VERSION ""

NS_ :

BS_:

BU_: FLC_FD3

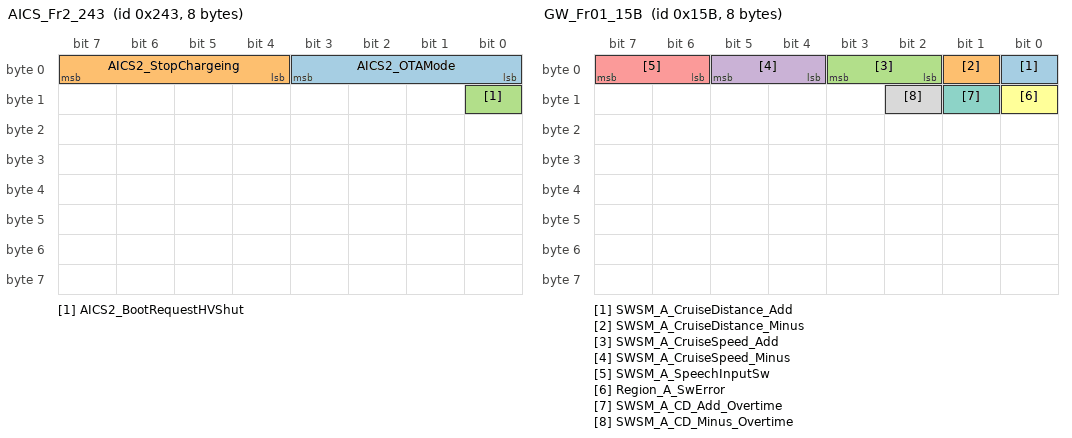
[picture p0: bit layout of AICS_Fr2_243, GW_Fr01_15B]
BO_ 579 AICS_Fr2_243: 8 Vector__XXX
 SG_ AICS2_OTAMode : 3|4@0+ (1,0) [0|15] "NoUnit" FLC_FD3
 SG_ AICS2_StopChargeing : 7|4@0+ (1,0) [0|15] "NoUnit" FLC_FD3
 SG_ AICS2_BootRequestHVShut : 8|1@0+ (1,0) [0|1] "NoUnit" FLC_FD3

BO_ 347 GW_Fr01_15B: 8 Vector__XXX
 SG_ SWSM_A_CruiseDistance_Add : 0|1@0+ (1,0) [0|1] "NoUnit" FLC_FD3
 SG_ SWSM_A_CruiseDistance_Minus : 1|1@0+ (1,0) [0|1] "NoUnit" FLC_FD3
 SG_ SWSM_A_CruiseSpeed_Add : 3|2@0+ (1,0) [0|3] "NoUnit" FLC_FD3
 SG_ SWSM_A_CruiseSpeed_Minus : 5|2@0+ (1,0) [0|3] "NoUnit" FLC_FD3
 SG_ SWSM_A_SpeechInputSw : 7|2@0+ (1,0) [0|3] "NoUnit" FLC_FD3
 SG_ Region_A_SwError : 8|1@0+ (1,0) [0|1] "NoUnit" FLC_FD3
 SG_ SWSM_A_CD_Add_Overtime : 9|1@0+ (1,0) [0|1] "NoUnit" FLC_FD3
 SG_ SWSM_A_CD_Minus_Overtime : 10|1@0+ (1,0) [0|1] "NoUnit" FLC_FD3

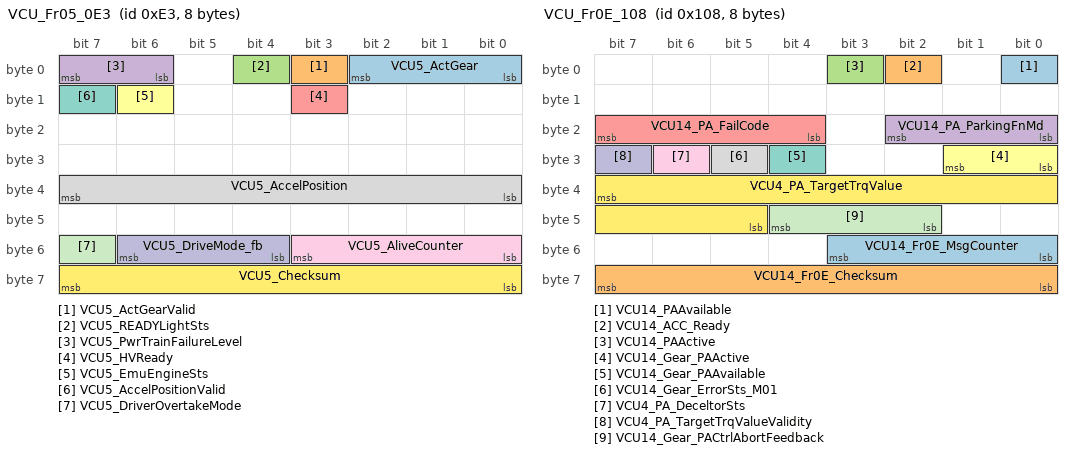
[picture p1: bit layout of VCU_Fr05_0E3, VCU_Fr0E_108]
BO_ 227 VCU_Fr05_0E3: 8 Vector__XXX
 SG_ VCU5_ActGear : 2|3@0+ (1,0) [0|7] "NoUnit" FLC_FD3
 SG_ VCU5_ActGearValid : 3|1@0+ (1,0) [0|1] "NoUnit" FLC_FD3
 SG_ VCU5_READYLightSts : 4|1@0+ (1,0) [0|1] "NoUnit" FLC_FD3
 SG_ VCU5_PwrTrainFailureLevel : 7|2@0+ (1,0) [0|3] "NoUnit" FLC_FD3
 SG_ VCU5_HVReady : 11|1@0+ (1,0) [0|1] "NoUnit" FLC_FD3
 SG_ VCU5_EmuEngineSts : 14|1@0+ (1,0) [0|1] "NoUnit" FLC_FD3
 SG_ VCU5_AccelPositionValid : 15|1@0+ (1,0) [0|1] "NoUnit" FLC_FD3
 SG_ VCU5_AccelPosition : 39|8@0+ (1,0) [0|100] "%" FLC_FD3
 SG_ VCU5_AliveCounter : 51|4@0+ (1,0) [0|15] "NoUnit" FLC_FD3
 SG_ VCU5_DriveMode_fb : 54|3@0+ (1,0) [0|7] "NoUnit" FLC_FD3
 SG_ VCU5_DriverOvertakeMode : 55|1@0+ (1,0) [0|1] "NoUnit" FLC_FD3
 SG_ VCU5_Checksum : 63|8@0+ (1,0) [0|255] "NoUnit" FLC_FD3

BO_ 264 VCU_Fr0E_108: 8 Vector__XXX
 SG_ VCU14_PAAvailable : 0|1@0+ (1,0) [0|1] "NoUnit" FLC_FD3
 SG_ VCU14_ACC_Ready : 2|1@0+ (1,0) [0|1] "NoUnit" FLC_FD3
 SG_ VCU14_PAActive : 3|1@0+ (1,0) [0|1] "NoUnit" FLC_FD3
 SG_ VCU14_PA_ParkingFnMd : 18|3@0+ (1,0) [0|7] "NoUnit" FLC_FD3
 SG_ VCU14_PA_FailCode : 23|4@0+ (1,0) [0|15] "NoUnit" FLC_FD3
 SG_ VCU14_Gear_PAActive : 25|2@0+ (1,0) [0|3] "NoUnit" FLC_FD3
 SG_ VCU14_Gear_PAAvailable : 28|1@0+ (1,0) [0|1] "NoUnit" FLC_FD3
 SG_ VCU14_Gear_ErrorSts_M01 : 29|1@0+ (1,0) [0|1] "NoUnit" FLC_FD3
 SG_ VCU4_PA_DeceltorSts : 30|1@0+ (1,0) [0|1] "NoUnit" FLC_FD3
 SG_ VCU4_PA_TargetTrqValueValidity : 31|1@0+ (1,0) [0|1] "NoUnit" FLC_FD3
 SG_ VCU14_Gear_PACtrlAbortFeedback : 44|3@0+ (1,0) [0|7] "NoUnit" FLC_FD3
 SG_ VCU4_PA_TargetTrqValue : 39|11@0+ (0.5,-400) [400|400] "Nm" FLC_FD3
 SG_ VCU14_Fr0E_MsgCounter : 51|4@0+ (1,0) [0|15] "NoUnit" FLC_FD3
 SG_ VCU14_Fr0E_Checksum : 63|8@0+ (1,0) [0|255] "NoUnit" FLC_FD3

BO_ 600 BMS_Fr03_258: 8 Vector__XXX
 SG_ BMS3_StateOfCharge : 7|16@0+ (0.1,0) [0|100] "NoUnit" FLC_FD3
 SG_ BMS3_Charge_State : 59|4@0+ (1,0) [0|15] "NoUnit" FLC_FD3

BO_ 170 MCU_Fr01_0AA: 16 Vector__XXX
 SG_ MCU1_MotorSpeed : 23|16@0+ (1,-20000) [-20000|45531] "Rpm" FLC_FD3
 SG_ MCU1_ControllerTorque : 39|16@0+ (0.05,-1024) [-1024|1024] "Nm" FLC_FD3
 SG_ MCU1_AliveCounter : 51|4@0+ (1,0) [0|15] "NoUnit" FLC_FD3
 SG_ MCU1_presentActivityFault : 71|8@0+ (1,0) [0|128] "NoUnit" FLC_FD3
 SG_ MCU1_CurrentTorque : 78|15@0+ (0.05,-400) [-400|400] "Nm" FLC_FD3
 SG_ MCU1_CurrentTorqueValid : 95|1@0+ (1,0) [0|1] "NoUnit" FLC_FD3

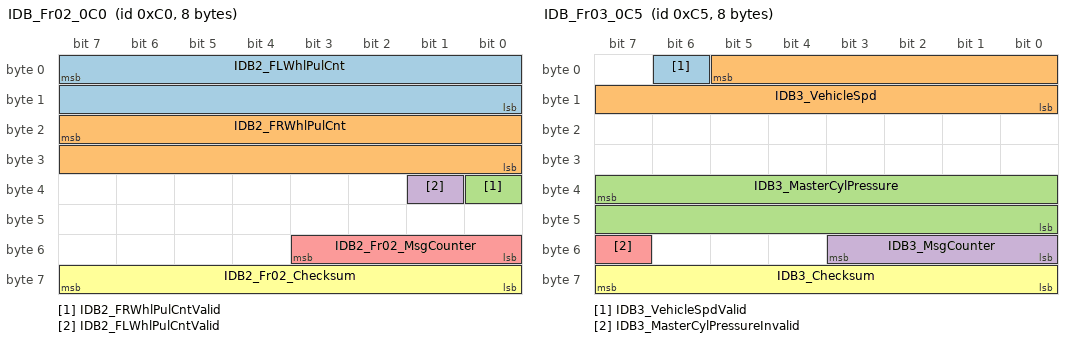
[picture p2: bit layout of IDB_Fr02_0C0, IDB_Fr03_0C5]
BO_ 192 IDB_Fr02_0C0: 8 Vector__XXX
 SG_ IDB2_FLWhlPulCnt : 7|16@0+ (0.5,0) [0|32767] "NoUnit" FLC_FD3
 SG_ IDB2_FRWhlPulCnt : 23|16@0+ (0.5,0) [0|32767] "NoUnit" FLC_FD3
 SG_ IDB2_FRWhlPulCntValid : 32|1@0+ (1,0) [0|1] "NoUnit" FLC_FD3
 SG_ IDB2_FLWhlPulCntValid : 33|1@0+ (1,0) [0|1] "NoUnit" FLC_FD3
 SG_ IDB2_Fr02_MsgCounter : 51|4@0+ (1,0) [0|15] "NoUnit" FLC_FD3
 SG_ IDB2_Fr02_Checksum : 63|8@0+ (1,0) [0|255] "NoUnit" FLC_FD3

BO_ 197 IDB_Fr03_0C5: 8 Vector__XXX
 SG_ IDB3_VehicleSpdValid : 6|1@0+ (1,0) [0|1] "NoUnit" FLC_FD3
 SG_ IDB3_VehicleSpd : 5|14@0+ (0.03125,0) [0|511.9375] "km/h" FLC_FD3
 SG_ IDB3_MasterCylPressure : 39|16@0+ (0.01,-30) [0|280] "bar" FLC_FD3
 SG_ IDB3_MsgCounter : 51|4@0+ (1,0) [0|15] "NoUnit" FLC_FD3
 SG_ IDB3_MasterCylPressureInvalid : 55|1@0+ (1,0) [0|1] "NoUnit" FLC_FD3
 SG_ IDB3_Checksum : 63|8@0+ (1,0) [0|255] "NoUnit" FLC_FD3

BO_ 199 IDB_Fr04_0C7: 32 Vector__XXX
 SG_ IDB4_FLWhlVelocityValid : 9|1@0+ (1,0) [0|1] "NoUnit" FLC_FD3
 SG_ IDB4_FLWhlVelocity : 7|14@0+ (0.03125,0) [0|511.9375] "km/h" FLC_FD3
 SG_ IDB4_FRWhlVelocityValid : 25|1@0+ (1,0) [0|1] "NoUnit" FLC_FD3
 SG_ IDB4_FRWhlVelocity : 23|14@0+ (0.03125,0) [0|511.9375] "km/h" FLC_FD3
 SG_ IDB4_RRWhlDir : 33|2@0+ (1,0) [0|3] "NoUnit" FLC_FD3
 SG_ IDB4_RLWhlDir : 35|2@0+ (1,0) [0|3] "NoUnit" FLC_FD3
 SG_ IDB4_FRWhlDir : 37|2@0+ (1,0) [0|3] "NoUnit" FLC_FD3
 SG_ IDB4_FLWhlDir : 39|2@0+ (1,0) [0|3] "NoUnit" FLC_FD3
 SG_ IDB4_MsgCounter : 51|4@0+ (1,0) [0|15] "NoUnit" FLC_FD3
 SG_ IDB4_Checksum : 63|8@0+ (1,0) [0|255] "NoUnit" FLC_FD3
 SG_ IDB4_RRWhlVelocityValid : 72|1@0+ (1,0) [0|1] "NoUnit" FLC_FD3
 SG_ IDB4_RLWhlVelocityValid : 73|1@0+ (1,0) [0|1] "NoUnit" FLC_FD3
 SG_ IDB4_RLWhlVelocity : 71|14@0+ (0.03125,0) [0|511.9375] "km/h" FLC_FD3
 SG_ IDB4_RLWhlPulCntValid : 88|1@0+ (1,0) [0|1] "NoUnit" FLC_FD3
 SG_ IDB4_RRWhlPulCntValid : 89|1@0+ (1,0) [0|1] "NoUnit" FLC_FD3
 SG_ IDB4_RRWhlVelocity : 87|14@0+ (0.03125,0) [0|511.9375] "km/h" FLC_FD3
 SG_ IDB4_RLWhlPulCnt : 103|16@0+ (0.5,0) [0|32767] "NoUnit" FLC_FD3
 SG_ IDB4_RRWhlPulCnt : 119|16@0+ (0.5,0) [0|32767] "NoUnit" FLC_FD3

BO_ 201 IDB_Fr10_0C9: 16 Vector__XXX
 SG_ IDB10_ADAS_DrvTorqueReq : 40|1@0+ (1,0) [0|1] "NoUnit" FLC_FD3
 SG_ IDB10_ADAS_RegenTorqueReq : 41|1@0+ (1,0) [0|1] "NoUnit" FLC_FD3
 SG_ IDB10_ADAS_DrvTorque : 103|16@0+ (0.5,-16000) [-16000|16000] "Nm" FLC_FD3
 SG_ IDB10_ADAS_RegenTorque : 119|16@0+ (0.5,-16000) [-16000|16000] "Nm" FLC_FD3

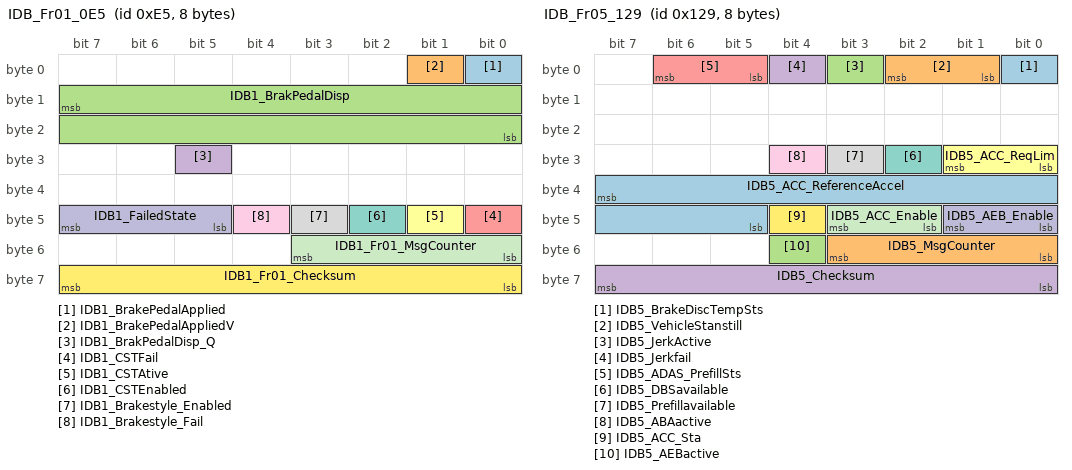
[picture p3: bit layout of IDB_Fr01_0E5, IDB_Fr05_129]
BO_ 229 IDB_Fr01_0E5: 8 Vector__XXX
 SG_ IDB1_BrakePedalApplied : 0|1@0+ (1,0) [0|1] "NoUnit" FLC_FD3
 SG_ IDB1_BrakePedalAppliedV : 1|1@0+ (1,0) [0|1] "NoUnit" FLC_FD3
 SG_ IDB1_BrakPedalDisp : 15|16@0+ (0.1,-40) [-40|160] "mm" FLC_FD3
 SG_ IDB1_BrakPedalDisp_Q : 29|1@0+ (1,0) [0|1] "NoUnit" FLC_FD3
 SG_ IDB1_CSTFail : 40|1@0+ (1,0) [0|1] "NoUnit" FLC_FD3
 SG_ IDB1_CSTAtive : 41|1@0+ (1,0) [0|1] "NoUnit" FLC_FD3
 SG_ IDB1_CSTEnabled : 42|1@0+ (1,0) [0|1] "NoUnit" FLC_FD3
 SG_ IDB1_Brakestyle_Enabled : 43|1@0+ (1,0) [0|1] "NoUnit" FLC_FD3
 SG_ IDB1_Brakestyle_Fail : 44|1@0+ (1,0) [0|1] "NoUnit" FLC_FD3
 SG_ IDB1_FailedState : 47|3@0+ (1,0) [0|7] "NoUnit" FLC_FD3
 SG_ IDB1_Fr01_MsgCounter : 51|4@0+ (1,0) [0|15] "NoUnit" FLC_FD3
 SG_ IDB1_Fr01_Checksum : 63|8@0+ (1,0) [0|255] "NoUnit" FLC_FD3

BO_ 289 IDB_Fr09_121: 8 Vector__XXX
 SG_ IDB9_BrakePedalPosition : 43|8@0+ (1,0) [0|100] "%" FLC_FD3

BO_ 297 IDB_Fr05_129: 8 Vector__XXX
 SG_ IDB5_BrakeDiscTempSts : 0|1@0+ (1,0) [0|1] "NoUnit" FLC_FD3
 SG_ IDB5_VehicleStanstill : 2|2@0+ (1,0) [0|3] "NoUnit" FLC_FD3
 SG_ IDB5_JerkActive : 3|1@0+ (1,0) [0|1] "NoUnit" FLC_FD3
 SG_ IDB5_Jerkfail : 4|1@0+ (1,0) [0|1] "NoUnit" FLC_FD3
 SG_ IDB5_ADAS_PrefillSts : 6|2@0+ (1,0) [0|3] "" FLC_FD3
 SG_ IDB5_ACC_ReqLim : 25|2@0+ (1,0) [0|3] "NoUnit" FLC_FD3
 SG_ IDB5_DBSavailable : 26|1@0+ (1,0) [0|1] "NoUnit" FLC_FD3
 SG_ IDB5_Prefillavailable : 27|1@0+ (1,0) [0|1] "NoUnit" FLC_FD3
 SG_ IDB5_ABAactive : 28|1@0+ (1,0) [0|1] "NoUnit" FLC_FD3
 SG_ IDB5_AEB_Enable : 41|2@0+ (1,0) [0|3] "NoUnit" FLC_FD3
 SG_ IDB5_ACC_Enable : 43|2@0+ (1,0) [0|3] "NoUnit" FLC_FD3
 SG_ IDB5_ACC_Sta : 44|1@0+ (1,0) [0|1] "NoUnit" FLC_FD3
 SG_ IDB5_ACC_ReferenceAccel : 39|11@0+ (0.01,-10.23) [-10.23|10.24] "m/s?" FLC_FD3
 SG_ IDB5_MsgCounter : 51|4@0+ (1,0) [0|15] "NoUnit" FLC_FD3
 SG_ IDB5_AEBactive : 52|1@0+ (1,0) [0|1] "NoUnit" FLC_FD3
 SG_ IDB5_Checksum : 63|8@0+ (1,0) [0|255] "NoUnit" FLC_FD3

BO_ 299 IDB_Fr06_12B: 8 Vector__XXX
 SG_ IDB6_EPBStatus : 34|3@0+ (1,0) [0|7] "NoUnit" FLC_FD3
 SG_ IDB6_EPBAvailable : 37|3@0+ (1,0) [0|7] "NoUnit" FLC_FD3

BO_ 301 IDB_Fr07_12D: 16 Vector__XXX
 SG_ IDB7_ESCFail : 0|1@0+ (1,0) [0|1] "NoUnit" FLC_FD3
 SG_ IDB7_ESCActive : 1|1@0+ (1,0) [0|1] "NoUnit" FLC_FD3
 SG_ IDB7_ESCDisable : 2|1@0+ (1,0) [0|1] "NoUnit" FLC_FD3
 SG_ IDB7_ABSActive : 3|1@0+ (1,0) [0|1] "NoUnit" FLC_FD3
 SG_ IDB7_EBD_Fail : 4|1@0+ (1,0) [0|1] "NoUnit" FLC_FD3
 SG_ IDB7_EBD_Active : 5|1@0+ (1,0) [0|1] "NoUnit" FLC_FD3
 SG_ IDB7_HBAActive : 6|1@0+ (1,0) [0|1] "NoUnit" FLC_FD3
 SG_ IDB7_HBAFail : 7|1@0+ (1,0) [0|1] "NoUnit" FLC_FD3
 SG_ IDB7_DiagMode : 8|1@0+ (1,0) [0|1] "NoUnit" FLC_FD3
 SG_ IDB7_TCSActive : 9|1@0+ (1,0) [0|1] "NoUnit" FLC_FD3
 SG_ IDB7_TCSDisable : 10|1@0+ (1,0) [0|1] "NoUnit" FLC_FD3
 SG_ IDB7_TCSFail : 11|1@0+ (1,0) [0|1] "NoUnit" FLC_FD3
 SG_ IDB7_ROPACTIVE : 12|1@0+ (1,0) [0|1] "NoUnit" FLC_FD3
 SG_ IDB7_ROPFailure : 13|1@0+ (1,0) [0|1] "NoUnit" FLC_FD3
 SG_ IDB7_DynParkBrkByIDBActive : 21|1@0+ (1,0) [0|1] "NoUnit" FLC_FD3
 SG_ IDB7_DynParkBrkByIDBAvailable : 22|1@0+ (1,0) [0|1] "NoUnit" FLC_FD3
 SG_ IDB7_HSAActive : 23|1@0+ (1,0) [0|1] "NoUnit" FLC_FD3
 SG_ IDB7_HSAFail : 24|1@0+ (1,0) [0|1] "NoUnit" FLC_FD3
 SG_ IDB7_HDCEnabled : 25|1@0+ (1,0) [0|1] "NoUnit" FLC_FD3
 SG_ IDB7_HDCFail : 26|1@0+ (1,0) [0|1] "NoUnit" FLC_FD3
 SG_ IDB7_HDCAtive : 27|1@0+ (1,0) [0|1] "NoUnit" FLC_FD3
 SG_ IDB7_ABSFail : 29|1@0+ (1,0) [0|1] "NoUnit" FLC_FD3
 SG_ IDB7_MsgCounter : 51|4@0+ (1,0) [0|15] "NoUnit" FLC_FD3
 SG_ IDB7_Checksum : 63|8@0+ (1,0) [0|255] "NoUnit" FLC_FD3

BO_ 302 IDB_Fr12_12E: 16 Vector__XXX
 SG_ IDB12_AVHDispMSG : 15|2@0+ (1,0) [0|3] "NoUnit" FLC_FD3
 SG_ IDB12_AVHLampReq : 17|2@0+ (1,0) [0|3] "NoUnit" FLC_FD3
 SG_ IDB12_AVHStatus : 19|2@0+ (1,0) [0|3] "NoUnit" FLC_FD3
 SG_ IDB12_AVHEnabled : 20|1@0+ (1,0) [0|1] "NoUnit" FLC_FD3

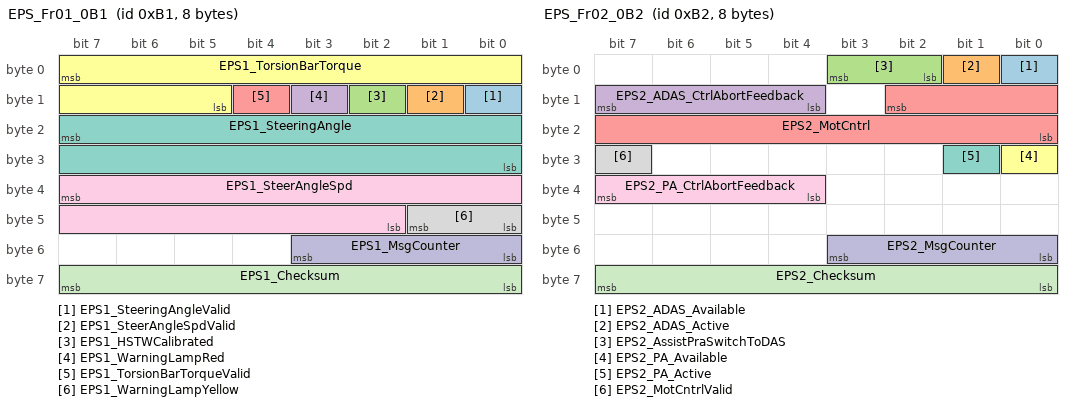
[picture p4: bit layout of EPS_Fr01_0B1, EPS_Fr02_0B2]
BO_ 177 EPS_Fr01_0B1: 8 Vector__XXX
 SG_ EPS1_SteeringAngleValid : 8|1@0+ (1,0) [0|1] "NoUnit" FLC_FD3
 SG_ EPS1_SteerAngleSpdValid : 9|1@0+ (1,0) [0|1] "NoUnit" FLC_FD3
 SG_ EPS1_HSTWCalibrated : 10|1@0+ (1,0) [0|1] "NoUnit" FLC_FD3
 SG_ EPS1_WarningLampRed : 11|1@0+ (1,0) [0|1] "NoUnit" FLC_FD3
 SG_ EPS1_TorsionBarTorqueValid : 12|1@0+ (1,0) [0|1] "NoUnit" FLC_FD3
 SG_ EPS1_TorsionBarTorque : 7|11@0+ (0.01,-10.24) [-10.24|10.23] "Nm" FLC_FD3
 SG_ EPS1_SteeringAngle : 23|16@0+ (0.0345,-780) [-780|780.021] "degree" FLC_FD3
 SG_ EPS1_WarningLampYellow : 41|2@0+ (1,0) [0|3] "NoUnit" FLC_FD3
 SG_ EPS1_SteerAngleSpd : 39|14@0+ (0.125,-1024) [-1024|1023.75] "deg/s" FLC_FD3
 SG_ EPS1_MsgCounter : 51|4@0+ (1,0) [0|15] "NoUnit" FLC_FD3
 SG_ EPS1_Checksum : 63|8@0+ (1,0) [0|255] "NoUnit" FLC_FD3

BO_ 178 EPS_Fr02_0B2: 8 Vector__XXX
 SG_ EPS2_ADAS_Available : 0|1@0+ (1,0) [0|1] "NoUnit" FLC_FD3
 SG_ EPS2_ADAS_Active : 1|1@0+ (1,0) [0|1] "NoUnit" FLC_FD3
 SG_ EPS2_AssistPraSwitchToDAS : 3|2@0+ (1,0) [0|3] "NoUnit" FLC_FD3
 SG_ EPS2_ADAS_CtrlAbortFeedback : 15|4@0+ (1,0) [0|15] "NoUnit" FLC_FD3
 SG_ EPS2_MotCntrl : 10|11@0+ (0.01,-8) [-8|8] "Nm" FLC_FD3
 SG_ EPS2_PA_Available : 24|1@0+ (1,0) [0|1] "NoUnit" FLC_FD3
 SG_ EPS2_PA_Active : 25|1@0+ (1,0) [0|1] "NoUnit" FLC_FD3
 SG_ EPS2_MotCntrlValid : 31|1@0+ (1,0) [0|1] "NoUnit" FLC_FD3
 SG_ EPS2_PA_CtrlAbortFeedback : 39|4@0+ (1,0) [0|15] "NoUnit" FLC_FD3
 SG_ EPS2_MsgCounter : 51|4@0+ (1,0) [0|15] "NoUnit" FLC_FD3
 SG_ EPS2_Checksum : 63|8@0+ (1,0) [0|255] "NoUnit" FLC_FD3

BO_ 142 ADCS_Fr02_08E: 16 FLC_FD3
 SG_ ADCS2_ADAS_EPSAngleReqSt : 0|1@0+ (1,0) [0|1] "NoUnit" Vector__XXX
 SG_ ADCS2_EPS_LDPState : 3|3@0+ (1,0) [0|7] "NoUnit" Vector__XXX
 SG_ ADCS2_NNP_SystemFaultStatus : 6|3@0+ (1,0) [0|7] "NoUnit" Vector__XXX
 SG_ ADCS_Pilot_SystemFaultStatus : 10|3@0+ (1,0) [0|7] "NoUnit" Vector__XXX
 SG_ ADCS2_ADAS_EPSLateralCtrlType : 14|4@0+ (1,0) [0|15] "NoUnit" Vector__XXX
 SG_ ADCS2_ADAS_EPSAngleReq : 29|14@0+ (0.1,-720) [-720|720] "degree" Vector__XXX
 SG_ ADCS2_ADAS_IHBCSysState : 42|3@0+ (1,0) [0|7] "NoUnit" Vector__XXX
 SG_ ADCS2_ALCDirection : 45|3@0+ (1,0) [0|7] "NoUnit" Vector__XXX
 SG_ ADCS2_ACC_EpbReq : 47|2@0+ (1,0) [0|3] "NoUnit" Vector__XXX
 SG_ ADCS2_MsgCounter0 : 51|4@0+ (1,0) [0|15] "NoUnit" Vector__XXX
 SG_ ADCS2_EPS_ELKState : 54|3@0+ (1,0) [0|7] "NoUnit" Vector__XXX
 SG_ ADCS2_Checksum0 : 63|8@0+ (1,0) [0|255] "NoUnit" Vector__XXX
 SG_ ADCS2_AEBVehicleHoldReq : 73|1@0+ (1,0) [0|1] "NoUnit" Vector__XXX
 SG_ ADCS2_AEBFullBrake : 74|1@0+ (1,0) [0|1] "NoUnit" Vector__XXX
 SG_ ADCS2_AEBPartialBrake : 75|1@0+ (1,0) [0|1] "NoUnit" Vector__XXX
 SG_ ADCS2_AEB_DBSLevel : 77|2@0+ (1,0) [0|3] "NoUnit" Vector__XXX
 SG_ ADCS2_AEBPrefillReq : 78|1@0+ (1,0) [0|1] "NoUnit" Vector__XXX
 SG_ ADCS2_AEB_JerkReq : 79|1@0+ (1,0) [0|1] "NoUnit" Vector__XXX
 SG_ ADCS2_AEBTargetDeceleration : 87|8@0+ (0.1,-12.7) [-12.7|12.8] "m/s?" Vector__XXX
 SG_ ADCS2_longitudCtrlType : 98|3@0+ (1,0) [0|7] "NoUnit" Vector__XXX
 SG_ ADCS2_LongitudCtrlDecToStopReq : 99|1@0+ (1,0) [0|1] "NoUnit" Vector__XXX
 SG_ ADCS2_LongitudCtrlDriveOff : 100|1@0+ (1,0) [0|1] "NoUnit" Vector__XXX
 SG_ ADCS2_AEB_JerkLevel : 102|2@0+ (1,0) [0|3] "NoUnit" Vector__XXX
 SG_ ADCS2_LongitudCtrlAccelCtrlReq : 116|1@0+ (1,0) [0|1] "NoUnit" Vector__XXX
 SG_ ADCS2_LongitudCtrlTargetAccel : 111|11@0+ (0.01,-10.23) [-10.23|10.24] "m/s?" Vector__XXX

BO_ 143 ADCS_Fr11_08F_APA1: 32 Vector__XXX
 SG_ ADCS11_Parking_WorkSts : 27|4@0+ (1,0) [0|15] "NoUnit" FLC_FD3

BO_ 310 ADCS_F12_136: 16 FLC_FD3
 SG_ ADCS12_FCWWarnAudioplay : 5|1@0+ (1,0) [0|1] "NoUnit" Vector__XXX
 SG_ ADCS12_RCTAWarnAudioplay : 9|2@0+ (1,0) [0|3] "NoUnit" Vector__XXX
 SG_ ADCS12_FCTAWarnAudioplay : 13|2@0+ (1,0) [0|3] "NoUnit" Vector__XXX
 SG_ ADCS12_SpeedWarnAudioplay : 16|1@0+ (1,0) [0|1] "NoUnit" Vector__XXX
 SG_ ADCS12_DOWWarnAudioplay : 21|1@0+ (1,0) [0|1] "NoUnit" Vector__XXX
 SG_ ADCS12_DCLCAudioplay : 31|3@0+ (1,0) [0|7] "NoUnit" Vector__XXX
 SG_ ADCS12_PilotAudioPlay : 33|2@0+ (1,0) [0|3] "NoUnit" Vector__XXX
 SG_ ADCS12_HandOffAudioplay : 35|2@0+ (1,0) [0|3] "NoUnit" Vector__XXX
 SG_ ADCS12_NNPCancelAudioPlay : 38|1@0+ (1,0) [0|1] "NoUnit" Vector__XXX
 SG_ ADCS12_RCWWarnAudioplay : 39|1@0+ (1,0) [0|1] "NoUnit" Vector__XXX
 SG_ ADCS12_MRMAudioPlay : 41|2@0+ (1,0) [0|3] "NoUnit" Vector__XXX
 SG_ ADCS12_NNP_ResumeAudioplay : 43|2@0+ (1,0) [0|3] "NoUnit" Vector__XXX
 SG_ ADCS12_Lcsndrequest : 45|2@0+ (1,0) [0|3] "NoUnit" Vector__XXX
 SG_ ADCS12_Lcsndrconfirm : 47|2@0+ (1,0) [0|3] "NoUnit" Vector__XXX
 SG_ ADCS12_DriveOffBroadcast : 50|1@0+ (1,0) [0|1] "NoUnit" Vector__XXX
 SG_ ADCS12_EyeOffBroadcast : 53|1@0+ (1,0) [0|1] "" Vector__XXX
 SG_ ADCS12_longitudDisableInfo : 59|4@0+ (1,0) [0|15] "NoUnit" Vector__XXX
 SG_ ADCS12_SpeedAdaptComfirm : 69|1@0+ (1,0) [0|1] "NoUnit" Vector__XXX
 SG_ ADCS12_PayModeConfirm : 72|1@0+ (1,0) [0|1] "NoUnit" Vector__XXX
 SG_ ADCS12_longitudCtrlSysInfo : 76|4@0+ (1,0) [0|15] "NoUnit" Vector__XXX
 SG_ ADCS12_ADAS_DriveOffinhibition : 80|1@0+ (1,0) [0|1] "NoUnit" Vector__XXX
 SG_ ADCS12_P2N_State_Reminder : 83|3@0+ (1,0) [0|7] "NoUnit" Vector__XXX
 SG_ ADCS12_NNP_State_Reminder : 86|3@0+ (1,0) [0|7] "NoUnit" Vector__XXX
 SG_ ADCS12_NNP_LightRemind : 87|1@0+ (1,0) [0|1] "NoUnit" Vector__XXX
 SG_ ADCS12_LaneChangePendingAlert : 90|1@0+ (1,0) [0|1] "NoUnit" Vector__XXX
 SG_ ADCS12_NPilotSysInfo : 95|5@0+ (1,0) [0|31] "NoUnit" Vector__XXX
 SG_ ADCS12_LCAudioPlay : 99|2@0+ (1,0) [0|3] "NoUnit" Vector__XXX
 SG_ ADCS12_NNP_Scenarios_AudioPlay : 103|4@0+ (1,0) [0|15] "NoUnit" Vector__XXX
 SG_ ADCS12_NNP_RINO : 111|4@0+ (1,0) [0|15] "NoUnit" Vector__XXX

BO_ 403 ADCS_Fr08_193: 64 FLC_FD3
 SG_ ADCS8_LDWState : 2|3@0+ (1,0) [0|7] "NoUnit" Vector__XXX
 SG_ ADCS8_LDWWarnState : 5|3@0+ (1,0) [0|7] "NoUnit" Vector__XXX
 SG_ ADCS8_ELKMode : 7|1@0+ (1,0) [0|1] "NoUnit" Vector__XXX
 SG_ ADCS8_LDPELKWarnState : 9|2@0+ (1,0) [0|3] "NoUnit" Vector__XXX
 SG_ ADCS8_lateralCtrHandsEyesOffWarning : 12|3@0+ (1,0) [0|7] "NoUnit" Vector__XXX
 SG_ ADCS8_MissingExitAlert : 15|3@0+ (1,0) [0|7] "NoUnit" Vector__XXX
 SG_ ADCS8_LKSSetspeed : 23|8@0+ (1,0) [0|255] "km/h" Vector__XXX
 SG_ ADCS8_ACCState : 26|3@0+ (1,0) [0|7] "NoUnit" Vector__XXX
 SG_ ADCS8_lateralCtrtakeover : 27|1@0+ (1,0) [0|1] "NoUnit" Vector__XXX
 SG_ ADAS8_LateralCtrHandOffReleasewarning : 28|1@0+ (1,0) [0|1] "NoUnit" Vector__XXX
 SG_ ADCS8_LDPELKtakeoverWarningstate : 31|2@0+ (1,0) [0|3] "NoUnit" Vector__XXX
 SG_ ADCS8_longitudCtrlSetSpeed : 39|8@0+ (1,0) [0|255] "km/h" Vector__XXX
 SG_ ADCS8_NNP_Scenarios : 43|4@0+ (1,0) [0|15] "NoUnit" Vector__XXX
 SG_ ADCS8_longitudCtrlTakeOverReq : 44|1@0+ (1,0) [0|1] "NoUnit" Vector__XXX
 SG_ ADCS8_longitudCtrlSetDistance : 47|3@0+ (1,0) [0|7] "NoUnit" Vector__XXX
 SG_ ADCS8_longitudCtrlTargetValidity : 48|1@0+ (1,0) [0|1] "NoUnit" Vector__XXX
 SG_ ADCS8_ACCSystemFaultStatus : 50|2@0+ (1,0) [0|3] "NoUnit" Vector__XXX
 SG_ ADCS8_AEB_SystemFaultStatus : 53|3@0+ (1,0) [0|7] "NoUnit" Vector__XXX
 SG_ ADCS8_AEB_SystemStatus : 55|2@0+ (1,0) [0|3] "NoUnit" Vector__XXX
 SG_ ADCS8_FCWSystemFaultStatus : 57|2@0+ (1,0) [0|3] "NoUnit" Vector__XXX
 SG_ ADCS8_FCWStatus : 59|2@0+ (1,0) [0|3] "NoUnit" Vector__XXX
 SG_ ADCS8_FCWSensitiveLevel : 61|2@0+ (1,0) [0|3] "NoUnit" Vector__XXX
 SG_ ADCS8_FCW_State : 63|2@0+ (1,0) [0|3] "NoUnit" Vector__XXX
 SG_ ADCS8_FCTA_State : 65|2@0+ (1,0) [0|3] "NoUnit" Vector__XXX
 SG_ ADCS8_AILampMode : 69|4@0+ (1,0) [0|15] "" Vector__XXX
 SG_ ADCS8_CDCS_CertificateState2 : 70|1@0+ (1,0) [0|1] "NoUnit" Vector__XXX
 SG_ ADCS8_FCTA_SystemFaultStatus : 73|2@0+ (1,0) [0|3] "NoUnit" Vector__XXX
 SG_ ADCS8_FCTAWarnObjType : 75|2@0+ (1,0) [0|3] "NoUnit" Vector__XXX
 SG_ ADCS8_FCTARightActiveSt : 77|2@0+ (1,0) [0|3] "NoUnit" Vector__XXX
 SG_ ADCS8_FCTALeftActiveSt : 79|2@0+ (1,0) [0|3] "NoUnit" Vector__XXX
 SG_ ADCS8_RCTA_SystemFaultStatus : 81|2@0+ (1,0) [0|3] "NoUnit" Vector__XXX
 SG_ ADCS8_RCTARightWarnSt : 83|2@0+ (1,0) [0|3] "NoUnit" Vector__XXX
 SG_ ADCS8_RCTALeftWarnSt : 85|2@0+ (1,0) [0|3] "NoUnit" Vector__XXX
 SG_ ADCS8_RCTA_State : 87|2@0+ (1,0) [0|3] "NoUnit" Vector__XXX
 SG_ ADCS8_DOW_State : 89|2@0+ (1,0) [0|3] "NoUnit" Vector__XXX
 SG_ ADCS8_RCW_SystemFaultStatus : 91|2@0+ (1,0) [0|3] "NoUnit" Vector__XXX
 SG_ ADCS8_RCW_WarnState : 93|2@0+ (1,0) [0|3] "NoUnit" Vector__XXX
 SG_ ADCS8_RCW_State : 95|2@0+ (1,0) [0|3] "NoUnit" Vector__XXX
 SG_ ADCS8_ADAS_IHBCStat : 97|2@0+ (1,0) [0|3] "NoUnit" Vector__XXX
 SG_ ADCS8_DOW_SystemFaultStatus : 99|2@0+ (1,0) [0|3] "NoUnit" Vector__XXX
 SG_ ADCS8_DOWRightWarnState : 101|2@0+ (1,0) [0|3] "NoUnit" Vector__XXX
 SG_ ADCS8_DOWLeftWarnState : 103|2@0+ (1,0) [0|3] "NoUnit" Vector__XXX
 SG_ ADCS8_LCAState : 105|2@0+ (1,0) [0|3] "NoUnit" Vector__XXX
 SG_ ADCS8_HornReq : 106|1@0+ (1,0) [0|1] "NoUnit" Vector__XXX
 SG_ ADCS8_DoorUnlock : 107|1@0+ (1,0) [0|1] "NoUnit" Vector__XXX
 SG_ ADCS8_ADAS_HazardLampReq : 108|1@0+ (1,0) [0|1] "NoUnit" Vector__XXX
 SG_ ADCS8_LKAActvSts : 111|3@0+ (1,0) [0|7] "NoUnit" Vector__XXX
 SG_ ADCS8_LCALeftWarnSt : 117|2@0+ (1,0) [0|3] "NoUnit" Vector__XXX
 SG_ ADCS8_LCARightWarnSt : 119|2@0+ (1,0) [0|3] "NoUnit" Vector__XXX
 SG_ ADCS8_ACCOnOffState : 126|1@0+ (1,0) [0|1] "NoUnit" Vector__XXX
 SG_ ADCS8_TSR_SpeedSign : 131|4@0+ (1,0) [0|15] "NoUnit" Vector__XXX
 SG_ ADCS8_TSRState : 133|2@0+ (1,0) [0|3] "NoUnit" Vector__XXX
 SG_ ADCS8_LCASystemFaultStatus : 135|2@0+ (1,0) [0|3] "NoUnit" Vector__XXX
 SG_ ADCS8_TSR_ForbiddenSign : 139|4@0+ (1,0) [0|15] "NoUnit" Vector__XXX
 SG_ ADCS8_NNP_SOAAudioplay : 140|1@0+ (1,0) [0|1] "NoUnit" Vector__XXX
 SG_ ADCS8_TSR_SLFStatefeedback : 142|2@0+ (1,0) [0|3] "NoUnit" Vector__XXX
 SG_ ADCS8_TSR_SpeedWarnState : 143|1@0+ (1,0) [0|1] "NoUnit" Vector__XXX
 SG_ ADCS8_TSR_SystemFaultStatus : 153|2@0+ (1,0) [0|3] "NoUnit" Vector__XXX
 SG_ ADCS8_TSR_StrLightColor : 155|2@0+ (1,0) [0|3] "NoUnit" Vector__XXX
 SG_ ADCS8_TSR_RightLightColor : 157|2@0+ (1,0) [0|3] "NoUnit" Vector__XXX
 SG_ ADCS8_TSR_LeftLightColor : 159|2@0+ (1,0) [0|3] "NoUnit" Vector__XXX
 SG_ ADCS8_VoiceNotifFrequency_mode : 161|2@0+ (1,0) [0|3] "NoUnit" Vector__XXX
 SG_ ADCS8_NPilot_SystemFaultStatus : 164|3@0+ (1,0) [0|7] "NoUnit" Vector__XXX
 SG_ ADCS8_NPilot_SysState : 167|3@0+ (1,0) [0|7] "NoUnit" Vector__XXX
 SG_ ADCS8_NNP_AutoOnOffSet : 169|2@0+ (1,0) [0|3] "NoUnit" Vector__XXX
 SG_ ADCS8_NNP_SystemFaultStatus : 172|3@0+ (1,0) [0|7] "NoUnit" Vector__XXX
 SG_ ADCS8_NNPSysState : 175|3@0+ (1,0) [0|7] "NoUnit" Vector__XXX
 SG_ ADCS8_DrvOffAlertState : 177|2@0+ (1,0) [0|3] "NoUnit" Vector__XXX
 SG_ ADCS8_DrvOffAlertSwitch : 178|1@0+ (1,0) [0|1] "NoUnit" Vector__XXX
 SG_ ADCS8_DrvOffAlert_SystemFaultStatus : 185|2@0+ (1,0) [0|3] "NoUnit" Vector__XXX
 SG_ ADCS8_Lanechangeinfor : 189|3@0+ (1,0) [0|7] "NoUnit" Vector__XXX
 SG_ ADCS8_DCLCSysState : 191|2@0+ (1,0) [0|3] "NoUnit" Vector__XXX
 SG_ ADCS8_LaneChangeSystemFaultStatus : 194|3@0+ (1,0) [0|7] "NoUnit" Vector__XXX
 SG_ ADCS8_LaneChangeWarning : 205|2@0+ (1,0) [0|3] "NoUnit" Vector__XXX
 SG_ ADCS8_ADAS_DriveOffPossilbe : 211|1@0+ (1,0) [0|1] "NoUnit" Vector__XXX
 SG_ ADCS8_SRR_FL_Fail : 215|2@0+ (1,0) [0|3] "NoUnit" Vector__XXX
 SG_ ADCS8_FRS_Fail : 217|2@0+ (1,0) [0|3] "NoUnit" Vector__XXX
 SG_ ADCS8_SRR_RL_Fail : 219|2@0+ (1,0) [0|3] "NoUnit" Vector__XXX
 SG_ ADCS8_DriveOffinhibitionObjType : 222|3@0+ (1,0) [0|7] "NoUnit" Vector__XXX
 SG_ ADCS8_SVC_RL_Fail : 225|2@0+ (1,0) [0|3] "NoUnit" Vector__XXX
 SG_ ADCS8_SVC_FL_Fail : 227|2@0+ (1,0) [0|3] "NoUnit" Vector__XXX
 SG_ ADCS8_SRR_RR_Fail : 229|2@0+ (1,0) [0|3] "NoUnit" Vector__XXX
 SG_ ADCS8_SRR_FR_Fail : 231|2@0+ (1,0) [0|3] "NoUnit" Vector__XXX
 SG_ ADCS8_TSR_OverspeedOnOffSet : 233|2@0+ (1,0) [0|3] "NoUnit" Vector__XXX
 SG_ ADCS8_RVC_Fail : 239|2@0+ (1,0) [0|3] "NoUnit" Vector__XXX
 SG_ ADCS8_VoiceMode : 240|1@0+ (1,0) [0|1] "NoUnit" Vector__XXX
 SG_ ADCS8_ALC_mode : 241|1@0+ (1,0) [0|1] "NoUnit" Vector__XXX
 SG_ ADCS8_NNP_State : 242|1@0+ (1,0) [0|1] "NoUnit" Vector__XXX
 SG_ ADCS8_FVC_120_Fail : 245|2@0+ (1,0) [0|3] "NoUnit" Vector__XXX
 SG_ ADCS8_Lanechangedirection : 247|2@0+ (1,0) [0|3] "NoUnit" Vector__XXX
 SG_ ADCS8_ADSDriving_mode : 249|2@0+ (1,0) [0|3] "NoUnit" Vector__XXX
 SG_ ADCS8_FVC_30_Fail : 251|2@0+ (1,0) [0|3] "NoUnit" Vector__XXX
 SG_ ADCS8_SVC_RR_Fail : 253|2@0+ (1,0) [0|3] "NoUnit" Vector__XXX
 SG_ ADCS8_SVC_FR_Fail : 255|2@0+ (1,0) [0|3] "NoUnit" Vector__XXX
 SG_ ADCS8_NNP_MRM_status : 258|3@0+ (1,0) [0|7] "NoUnit" Vector__XXX
 SG_ ADCS8_NpilotOverride_State : 262|2@0+ (1,0) [0|3] "NoUnit" Vector__XXX
 SG_ ADCS8_SystemFault : 271|2@0+ (1,0) [0|3] "NoUnit" Vector__XXX
 SG_ ADCS8_LeftLidarFault : 273|2@0+ (1,0) [0|3] "NoUnit" Vector__XXX
 SG_ ADCS8_RightlidarFault : 275|2@0+ (1,0) [0|3] "NoUnit" Vector__XXX
 SG_ ADCS8_NNP_SpeedLimit : 287|8@0+ (1,0) [0|255] "NoUnit" Vector__XXX
 SG_ ADCS8_TSR_LimitOverspeedSet : 295|8@0+ (1,0) [0|100] "%" Vector__XXX
 SG_ ADCS8_FLC_LDWLKAAid_OnOff_fbk : 306|3@0+ (1,0) [0|7] "" Vector__XXX
 SG_ ADCS8_DOWVoiceWarnSt : 308|2@0+ (1,0) [0|3] "" Vector__XXX
 SG_ ADCS8_Pilot_WorkMod : 313|2@0+ (1,0) [0|3] "NoUnit" Vector__XXX
 SG_ ADCS8_HandShakeSts : 316|3@0+ (1,0) [0|4] "NoUnit" Vector__XXX
 SG_ ADCS8_DCLC_SubStatus : 318|2@0+ (1,0) [0|3] "NoUnit" Vector__XXX
 SG_ ADCS8_DCLC_SystemSts : 327|2@0+ (1,0) [0|3] "NoUnit" Vector__XXX
 SG_ ADCS8_DCLC_AutChgLane : 325|4@0+ (1,0) [0|6] "NoUnit" Vector__XXX
 SG_ ADCS8_HandsOffWarning : 321|2@0+ (1,0) [0|3] "NoUnit" Vector__XXX

BO_ 404 ADCS_Fr10_194: 64 Vector__XXX
 SG_ ADCS8_RPA_CheckListDispReq6 : 0|1@0+ (1,0) [0|1] "NoUnit" FLC_FD3
 SG_ ADCS8_RPA_CheckListDispReq5 : 1|1@0+ (1,0) [0|1] "NoUnit" FLC_FD3
 SG_ ADCS8_RPA_CheckListDispReq4 : 2|1@0+ (1,0) [0|1] "NoUnit" FLC_FD3
 SG_ ADCS8_RPA_CheckListDispReq3 : 3|1@0+ (1,0) [0|1] "NoUnit" FLC_FD3
 SG_ ADCS8_RPA_CheckListDispReq2 : 4|1@0+ (1,0) [0|1] "NoUnit" FLC_FD3
 SG_ ADCS8_RPA_CheckListDispReq1 : 5|1@0+ (1,0) [0|1] "NoUnit" FLC_FD3
 SG_ ADCS8_PA_warninginfo : 15|8@0+ (1,0) [0|255] "NoUnit" FLC_FD3
 SG_ ADCS8_PA_FPAS_SnsrObjWrnngZn_FLM : 18|3@0+ (1,0) [0|7] "NoUnit" FLC_FD3
 SG_ ADCS8_PA_FPAS_SnsrObjWrnngZn_FLC : 21|3@0+ (1,0) [0|7] "NoUnit" FLC_FD3
 SG_ ADCS8_RPA_CheckListDispReq8 : 22|1@0+ (1,0) [0|1] "NoUnit" FLC_FD3
 SG_ ADCS8_RPA_CheckListDispReq7 : 23|1@0+ (1,0) [0|1] "NoUnit" FLC_FD3
 SG_ ADCS8_PA_FPAS_SnsrObjWrnngZn_FRC : 28|3@0+ (1,0) [0|7] "NoUnit" FLC_FD3
 SG_ ADCS8_PA_FPAS_SnsrObjWrnngZn_FRM : 31|3@0+ (1,0) [0|7] "NoUnit" FLC_FD3
 SG_ ADCS8_PA_FPAS_SnsrObjWrnngZn_RLM : 36|3@0+ (1,0) [0|7] "NoUnit" FLC_FD3
 SG_ ADCS8_PA_FPAS_SnsrObjWrnngZn_RLC : 39|3@0+ (1,0) [0|7] "NoUnit" FLC_FD3
 SG_ ADCS8_PA_FPAS_SnsrObjWrnngZn_RRC : 44|3@0+ (1,0) [0|7] "NoUnit" FLC_FD3
 SG_ ADCS8_PA_FPAS_SnsrObjWrnngZn_RRM : 47|3@0+ (1,0) [0|7] "NoUnit" FLC_FD3
 SG_ ADCS8_PA_FPAS_SnsrObjWrnngZn_SFR : 52|3@0+ (1,0) [0|7] "NoUnit" FLC_FD3
 SG_ ADCS8_PA_FPAS_SnsrObjWrnngZn_SFL : 55|3@0+ (1,0) [0|7] "NoUnit" FLC_FD3
 SG_ ADCS8_PA_FPAS_SnsrObjWrnngZn_SRR : 60|3@0+ (1,0) [0|7] "NoUnit" FLC_FD3
 SG_ ADCS8_PA_FPAS_SnsrObjWrnngZn_SRL : 63|3@0+ (1,0) [0|7] "NoUnit" FLC_FD3
 SG_ ADCS8_PA_FPAS_SnsrDist_FLC : 71|8@0+ (1,0) [0|255] "cm" FLC_FD3
 SG_ ADCS8_PA_FPAS_SnsrDist_FLM : 79|8@0+ (1,0) [0|255] "cm" FLC_FD3
 SG_ ADCS8_PA_FPAS_SnsrDist_FRM : 87|8@0+ (1,0) [0|255] "cm" FLC_FD3
 SG_ ADCS8_PA_FPAS_SnsrDist_FRC : 95|8@0+ (1,0) [0|255] "cm" FLC_FD3
 SG_ ADCS8_PA_FPAS_SnsrDist_RLC : 103|8@0+ (1,0) [0|255] "cm" FLC_FD3
 SG_ ADCS8_PA_FPAS_SnsrDist_RLM : 111|8@0+ (1,0) [0|255] "cm" FLC_FD3
 SG_ ADCS8_PA_FPAS_SnsrDist_RRM : 119|8@0+ (1,0) [0|255] "cm" FLC_FD3
 SG_ ADCS8_PA_FPAS_SnsrDist_RRC : 127|8@0+ (1,0) [0|255] "cm" FLC_FD3
 SG_ ADCS8_PA_FPAS_SnsrDist_SFL : 135|9@0+ (1,0) [0|511] "cm" FLC_FD3
 SG_ ADCS8_PA_FPAS_SnsrDist_SFR : 142|9@0+ (1,0) [0|511] "cm" FLC_FD3
 SG_ ADCS8_PA_FPAS_SnsrDist_SRL : 149|9@0+ (1,0) [0|511] "cm" FLC_FD3
 SG_ ADCS8_PA_FPAS_SnsrDist_SRR : 156|9@0+ (1,0) [0|511] "cm" FLC_FD3
 SG_ ADCS8_PA_FPAS_SensorFaultStsFRC : 168|1@0+ (1,0) [0|1] "NoUnit" FLC_FD3
 SG_ ADCS8_PA_FPAS_SensorFaultStsFRM : 169|1@0+ (1,0) [0|1] "NoUnit" FLC_FD3
 SG_ ADCS8_PA_FPAS_SensorFaultStsFLM : 170|1@0+ (1,0) [0|1] "NoUnit" FLC_FD3
 SG_ ADCS8_PA_FPAS_SensorFaultStsFLC : 171|1@0+ (1,0) [0|1] "NoUnit" FLC_FD3
 SG_ ADCS8_PA_RPAS_WorkSts : 173|2@0+ (1,0) [0|3] "NoUnit" FLC_FD3
 SG_ ADCS8_PA_FPAS_WorkSts : 175|2@0+ (1,0) [0|3] "NoUnit" FLC_FD3
 SG_ ADCS8_PA_RPAS_SensorFaultStsSRR : 176|1@0+ (1,0) [0|1] "NoUnit" FLC_FD3
 SG_ ADCS8_PA_RPAS_SensorFaultStsSRL : 177|1@0+ (1,0) [0|1] "NoUnit" FLC_FD3
 SG_ ADCS8_PA_FPAS_SensorFaultStsSFR : 178|1@0+ (1,0) [0|1] "NoUnit" FLC_FD3
 SG_ ADCS8_PA_FPAS_SensorFaultStsSFL : 179|1@0+ (1,0) [0|1] "NoUnit" FLC_FD3
 SG_ ADCS8_PA_RPAS_SensorFaultStsRRC : 180|1@0+ (1,0) [0|1] "NoUnit" FLC_FD3
 SG_ ADCS8_PA_RPAS_SensorFaultStsRRM : 181|1@0+ (1,0) [0|1] "NoUnit" FLC_FD3
 SG_ ADCS8_PA_RPAS_SensorFaultStsRLM : 182|1@0+ (1,0) [0|1] "NoUnit" FLC_FD3
 SG_ ADCS8_PA_RPAS_SensorFaultStsRLC : 183|1@0+ (1,0) [0|1] "NoUnit" FLC_FD3
 SG_ ADCS8_AudBpRate_R : 186|3@0+ (1,0) [0|7] "NoUnit" FLC_FD3
 SG_ ADCS8_AudBpRate_F : 189|3@0+ (1,0) [0|7] "NoUnit" FLC_FD3
 SG_ ADCS8_AVM_MODWarning : 190|1@0+ (1,0) [0|1] "NoUnit" FLC_FD3
 SG_ ADCS8_AVM_RomoteAVMFeedBack : 191|1@0+ (1,0) [0|1] "NoUnit" FLC_FD3
 SG_ ADCS8_PA_FPAS_SnsrObjWrnngZn_RSDW : 194|3@0+ (1,0) [0|7] "NoUnit" FLC_FD3
 SG_ ADCS8_PA_FPAS_SnsrObjWrnngZn_LSDW : 197|3@0+ (1,0) [0|7] "NoUnit" FLC_FD3
 SG_ ADCS8_PA_FPAS_SnsrObjWrnnglc_RSDW : 201|2@0+ (1,0) [0|3] "NoUnit" FLC_FD3
 SG_ ADCS8_PA_FPAS_SnsrObjWrnnglc_LSDW : 204|2@0+ (1,0) [0|3] "NoUnit" FLC_FD3
 SG_ ADCS8_Mod_Object_MovingDirection : 211|4@0+ (1,0) [0|15] "NoUnit" FLC_FD3

BO_ 1556 FLC_NM_614: 8 FLC_FD3
 SG_ FLC_SourceNodeIdentifier : 7|8@0+ (1,0) [0|255] "NoUnit" Vector__XXX
 SG_ FLC_RepeatMessageRequest : 8|1@0+ (1,0) [0|1] "NoUnit" Vector__XXX
 SG_ FLC_Reserve1 : 11|3@0+ (1,0) [0|3] "NoUnit" Vector__XXX
 SG_ FLC_ActiveWakeup : 12|1@0+ (1,0) [0|1] "NoUnit" Vector__XXX
 SG_ FLC_Reserve2 : 15|3@0+ (1,0) [0|7] "NoUnit" Vector__XXX
 SG_ FLC_WakeUp_KL15 : 16|1@0+ (1,0) [0|1] "NoUnit" Vector__XXX
 SG_ FLC_WakeUp_NM : 17|1@0+ (1,0) [0|1] "NoUnit" Vector__XXX
 SG_ FLC_WakeUpReason4 : 19|1@0+ (1,0) [0|1] "NoUnit" Vector__XXX
 SG_ FLC_WakeUpReason5 : 20|1@0+ (1,0) [0|1] "NoUnit" Vector__XXX
 SG_ FLC_WakeUpReason6 : 21|1@0+ (1,0) [0|1] "NoUnit" Vector__XXX
 SG_ FLC_WakeUpReason7 : 22|1@0+ (1,0) [0|1] "NoUnit" Vector__XXX
 SG_ FLC_WakeUpReason8 : 23|1@0+ (1,0) [0|1] "NoUnit" Vector__XXX
 SG_ FLC_RepeatFromSleep : 24|1@0+ (1,0) [0|1] "NoUnit" Vector__XXX
 SG_ FLC_RepeatFromPrepare : 25|1@0+ (1,0) [0|1] "NoUnit" Vector__XXX
 SG_ FLC_NormalFromRepeat : 26|1@0+ (1,0) [0|1] "NoUnit" Vector__XXX
 SG_ FLC_NormalFromReady : 27|1@0+ (1,0) [0|1] "NoUnit" Vector__XXX
 SG_ FLC_RepeatFromReady : 28|1@0+ (1,0) [0|1] "NoUnit" Vector__XXX
 SG_ FLC_RepeatFromNormal : 29|1@0+ (1,0) [0|1] "NoUnit" Vector__XXX
 SG_ FLC_RNM_DOW : 32|1@0+ (1,0) [0|1] "NoUnit" Vector__XXX

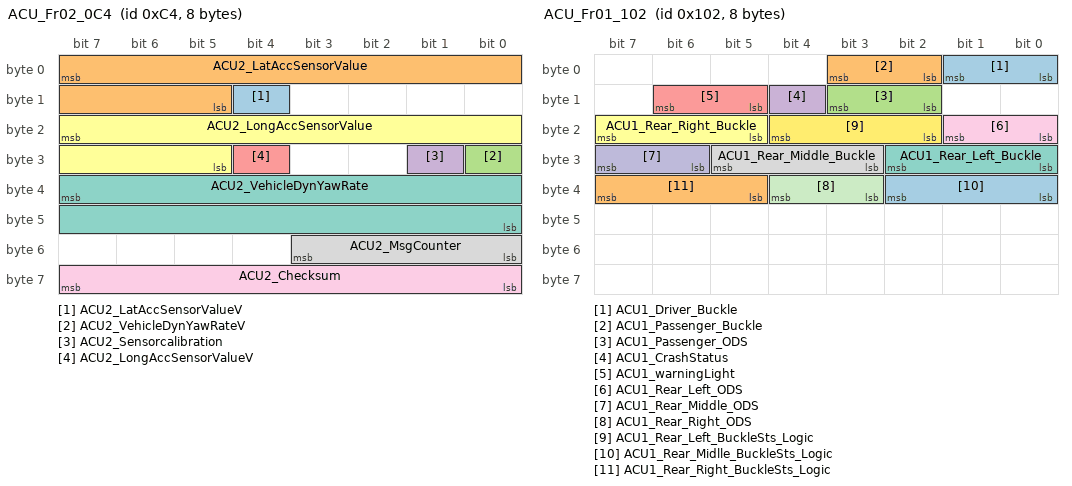
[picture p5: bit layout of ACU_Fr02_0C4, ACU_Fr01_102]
BO_ 196 ACU_Fr02_0C4: 8 Vector__XXX
 SG_ ACU2_LatAccSensorValueV : 12|1@0+ (1,0) [0|1] "NoUnit" FLC_FD3
 SG_ ACU2_LatAccSensorValue : 7|11@0+ (0.02,-16) [-16|16] "m/s?" FLC_FD3
 SG_ ACU2_VehicleDynYawRateV : 24|1@0+ (1,0) [0|1] "NoUnit" FLC_FD3
 SG_ ACU2_Sensorcalibration : 25|1@0+ (1,0) [0|1] "NoUnit" FLC_FD3
 SG_ ACU2_LongAccSensorValueV : 28|1@0+ (1,0) [0|1] "NoUnit" FLC_FD3
 SG_ ACU2_LongAccSensorValue : 23|11@0+ (0.02,-16) [-16|16] "m/s?" FLC_FD3
 SG_ ACU2_VehicleDynYawRate : 39|16@0+ (0.01,-180) [-180|180] "deg/s" FLC_FD3
 SG_ ACU2_MsgCounter : 51|4@0+ (1,0) [0|15] "NoUnit" FLC_FD3
 SG_ ACU2_Checksum : 63|8@0+ (1,0) [0|255] "NoUnit" FLC_FD3

BO_ 258 ACU_Fr01_102: 8 Vector__XXX
 SG_ ACU1_Driver_Buckle : 1|2@0+ (1,0) [0|3] "NoUnit" FLC_FD3
 SG_ ACU1_Passenger_Buckle : 3|2@0+ (1,0) [0|3] "NoUnit" FLC_FD3
 SG_ ACU1_Passenger_ODS : 11|2@0+ (1,0) [0|3] "NoUnit" FLC_FD3
 SG_ ACU1_CrashStatus : 12|1@0+ (1,0) [0|1] "NoUnit" FLC_FD3
 SG_ ACU1_warningLight : 14|2@0+ (1,0) [0|3] "NoUnit" FLC_FD3
 SG_ ACU1_Rear_Right_Buckle : 23|3@0+ (1,0) [0|7] "NoUnit" FLC_FD3
 SG_ ACU1_Rear_Left_Buckle : 26|3@0+ (1,0) [0|7] "NoUnit" FLC_FD3
 SG_ ACU1_Rear_Middle_Buckle : 29|3@0+ (1,0) [0|7] "NoUnit" FLC_FD3
 SG_ ACU1_Rear_Left_ODS : 17|2@0+ (1,0) [0|3] "NoUnit" FLC_FD3
 SG_ ACU1_Rear_Middle_ODS : 31|2@0+ (1,0) [0|3] "NoUnit" FLC_FD3
 SG_ ACU1_Rear_Right_ODS : 36|2@0+ (1,0) [0|3] "NoUnit" FLC_FD3
 SG_ ACU1_Rear_Left_BuckleSts_Logic : 20|3@0+ (1,0) [0|7] "NoUnit" FLC_FD3
 SG_ ACU1_Rear_Midlle_BuckleSts_Logic : 34|3@0+ (1,0) [0|7] "NoUnit" FLC_FD3
 SG_ ACU1_Rear_Right_BuckleSts_Logic : 39|3@0+ (1,0) [0|7] "NoUnit" FLC_FD3

BO_ 272 BDCS_Fr01_110: 8 Vector__XXX
 SG_ BDCS1_PowerMode : 1|2@0+ (1,0) [0|3] "NoUnit" FLC_FD3
 SG_ BDCS1_PowerManageMode : 7|4@0+ (1,0) [0|15] "NoUnit" FLC_FD3
 SG_ BDCS1_LowBeamSt : 11|1@0+ (1,0) [0|1] "NoUnit" FLC_FD3
 SG_ BDCS1_HighBeamSt : 12|1@0+ (1,0) [0|1] "NoUnit" FLC_FD3
 SG_ BDCS1_PositionLightSts : 17|1@0+ (1,0) [0|1] "NoUnit" FLC_FD3
 SG_ BDCS1_BacklightStatus : 18|1@0+ (1,0) [0|1] "NoUnit" FLC_FD3
 SG_ BDCS1_LeftTurnLightSt : 19|1@0+ (1,0) [0|1] "NoUnit" FLC_FD3
 SG_ BDCS1_RightTurnLightSt : 20|1@0+ (1,0) [0|1] "NoUnit" FLC_FD3
 SG_ BDCS1_FrontLampSt : 22|2@0+ (1,0) [0|3] "NoUnit" FLC_FD3
 SG_ BDCS1_HazardLampSt : 23|1@0+ (1,0) [0|1] "NoUnit" FLC_FD3
 SG_ BDCS1_HighBeamSW : 25|2@0+ (1,0) [0|3] "NoUnit" FLC_FD3
 SG_ BDCS1_TurnLightSW : 27|2@0+ (1,0) [0|3] "NoUnit" FLC_FD3
 SG_ BDCS1_HazardSwSt : 28|1@0+ (1,0) [0|1] "NoUnit" FLC_FD3
 SG_ BDCS1_RearFogLampSt : 30|1@0+ (1,0) [0|1] "NoUnit" FLC_FD3
 SG_ BDCS1_FrontFogLampSt : 31|1@0+ (1,0) [0|1] "NoUnit" FLC_FD3
 SG_ BDCS1_TrunkLockSts : 35|1@0+ (1,0) [0|1] "NoUnit" FLC_FD3
 SG_ BDCS1_HoodAjarSts : 39|1@0+ (1,0) [0|1] "NoUnit" FLC_FD3
 SG_ BDCS1_MsgCounter : 51|4@0+ (1,0) [0|15] "NoUnit" FLC_FD3
 SG_ BDCS1_Checksum : 63|8@0+ (1,0) [0|255] "NoUnit" FLC_FD3

BO_ 274 BDCS_Fr03_112: 16 Vector__XXX
 SG_ BDCS3_RemoteAuthenSts : 11|2@0+ (1,0) [0|3] "NoUnit" FLC_FD3
 SG_ BDCS3_BackDoorAjar : 27|3@0+ (1,0) [0|7] "NoUnit" FLC_FD3
 SG_ BDCS3_ADCSAuthenSts : 63|2@0+ (1,0) [0|3] "NoUnit" FLC_FD3

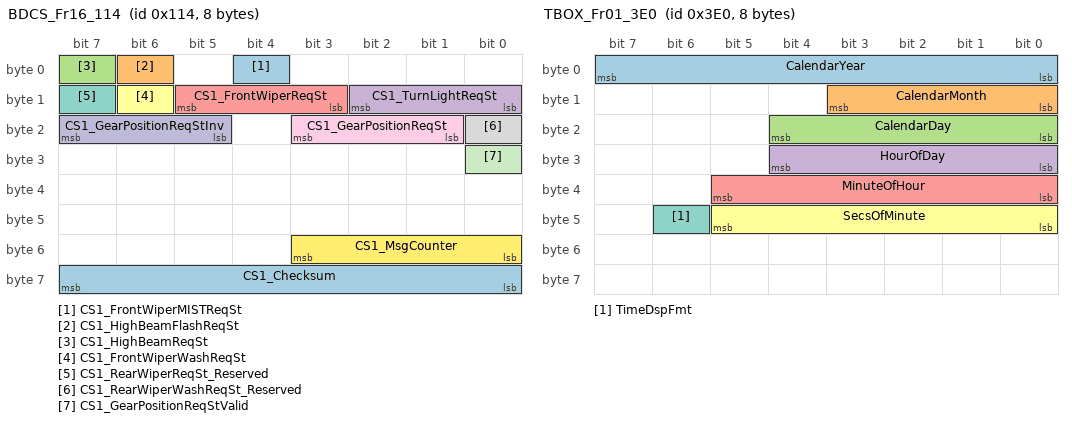
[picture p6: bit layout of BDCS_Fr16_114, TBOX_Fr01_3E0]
BO_ 276 BDCS_Fr16_114: 8 Vector__XXX
 SG_ CS1_FrontWiperMISTReqSt : 4|1@0+ (1,0) [0|1] "NoUnit" FLC_FD3
 SG_ CS1_HighBeamFlashReqSt : 6|1@0+ (1,0) [0|1] "NoUnit" FLC_FD3
 SG_ CS1_HighBeamReqSt : 7|1@0+ (1,0) [0|1] "NoUnit" FLC_FD3
 SG_ CS1_TurnLightReqSt : 10|3@0+ (1,0) [0|7] "NoUnit" FLC_FD3
 SG_ CS1_FrontWiperReqSt : 13|3@0+ (1,0) [0|7] "NoUnit" FLC_FD3
 SG_ CS1_FrontWiperWashReqSt : 14|1@0+ (1,0) [0|1] "NoUnit" FLC_FD3
 SG_ CS1_RearWiperReqSt_Reserved : 15|1@0+ (1,0) [0|1] "NoUnit" FLC_FD3
 SG_ CS1_RearWiperWashReqSt_Reserved : 16|1@0+ (1,0) [0|1] "NoUnit" FLC_FD3
 SG_ CS1_GearPositionReqSt : 19|3@0+ (1,0) [0|7] "NoUnit" FLC_FD3
 SG_ CS1_GearPositionReqStInv : 23|3@0+ (1,0) [0|7] "NoUnit" FLC_FD3
 SG_ CS1_GearPositionReqStValid : 24|1@0+ (1,0) [0|1] "NoUnit" FLC_FD3
 SG_ CS1_MsgCounter : 51|4@0+ (1,0) [0|15] "NoUnit" FLC_FD3
 SG_ CS1_Checksum : 63|8@0+ (1,0) [0|255] "NoUnit" FLC_FD3

BO_ 486 BDCS_Fr06_1E6: 16 Vector__XXX
 SG_ BDCS6_FrontWiperParkPos : 15|1@0+ (1,0) [0|1] "NoUnit" FLC_FD3
 SG_ BDCS6_FrontWiperSts : 18|3@0+ (1,0) [0|7] "NoUnit" FLC_FD3
 SG_ BDCS6_DayNightMode : 93|2@0+ (1,0) [0|3] "NoUnit" FLC_FD3

BO_ 645 BDCS_Fr13_LIN2_285: 8 Vector__XXX
 SG_ BDCS13_RLS_RQ_WiperSPD : 14|2@0+ (1,0) [0|3] "NoUnit" FLC_FD3

BO_ 418 DDCU_Fr01_1A2: 16 Vector__XXX
 SG_ DDCU1_FL_WinPos : 15|8@0+ (1,0) [0|100] "%" FLC_FD3
 SG_ DDCU1_RL_WinPos : 23|8@0+ (1,0) [0|100] "%" FLC_FD3
 SG_ DDCU1_FLDoorAjar : 25|2@0+ (1,0) [0|3] "NoUnit" FLC_FD3
 SG_ DDCU1_RLDoorAjar : 27|2@0+ (1,0) [0|3] "NoUnit" FLC_FD3
 SG_ DDCU1_MirrorFoldSt : 29|1@0+ (1,0) [0|1] "NoUnit" FLC_FD3

BO_ 419 PDCU_Fr01_1A3: 16 Vector__XXX
 SG_ PDCU1_FR_WinPos : 15|8@0+ (1,0) [0|100] "%" FLC_FD3
 SG_ PDCU1_RR_WinPos : 23|8@0+ (1,0) [0|100] "%" FLC_FD3
 SG_ PDCU1_FRDoorAjar : 25|2@0+ (1,0) [0|3] "NoUnit" FLC_FD3
 SG_ PDCU1_RRDoorAjar : 27|2@0+ (1,0) [0|3] "NoUnit" FLC_FD3

BO_ 320 CDCS_Fr03_140: 16 Vector__XXX
 SG_ CDCS3_ESCOffSw : 11|2@0+ (1,0) [0|3] "NoUnit" FLC_FD3
 SG_ CDCS3_HDCSw : 19|2@0+ (1,0) [0|3] "NoUnit" FLC_FD3
 SG_ CDCS3_DriveModeSet : 50|3@0+ (1,0) [0|7] "NoUnit" FLC_FD3
 SG_ CDCS3_Xcoordinate : 79|16@0+ (1,0) [0|65534] "NoUnit" FLC_FD3
 SG_ CDCS3_Ycoordinate : 95|16@0+ (1,0) [0|65534] "NoUnit" FLC_FD3
 SG_ CDCS3_XGestureSpd : 111|8@0+ (1,0) [0|254] "NoUnit" FLC_FD3
 SG_ CDCS3_YGestureSpd : 119|8@0+ (1,0) [0|254] "NoUnit" FLC_FD3
 SG_ CDCS3_TouchEvtTyp : 123|4@0+ (1,0) [0|15] "NoUnit" FLC_FD3

BO_ 442 CDCS_Fr10_1BA: 8 Vector__XXX
 SG_ CDCS10_WorK_status : 7|2@0+ (1,0) [0|3] "NoUnit" FLC_FD3

BO_ 443 CDCS_Fr13_1BB: 8 Vector__XXX
 SG_ CDCS13_SwSmMode : 1|2@0+ (1,0) [0|3] "NoUnit" FLC_FD3

BO_ 468 CDCS_FR05_1D4: 32 Vector__XXX
 SG_ CDCS5_ResetAllSetup : 0|1@0+ (1,0) [0|1] "NoUnit" FLC_FD3
 SG_ CDCS5_FactoryReset : 1|1@0+ (1,0) [0|1] "NoUnit" FLC_FD3

BO_ 501 CDCS_Fr11_1F5: 64 Vector__XXX
 SG_ CDCS11_LKSSetspeed : 7|8@0+ (1,0) [0|255] "Km/h" FLC_FD3
 SG_ CDCS11_LDW_OnOffSet : 9|2@0+ (1,0) [0|3] "NoUnit" FLC_FD3
 SG_ CDCS11_LowSpeedBSDSw : 11|2@0+ (1,0) [0|3] "NoUnit" FLC_FD3
 SG_ CDCS11_FCW_OnOffSet : 13|2@0+ (1,0) [0|3] "NoUnit" FLC_FD3
 SG_ CDCS11_AEB_OnOffSet : 15|2@0+ (1,0) [0|3] "NoUnit" FLC_FD3
 SG_ CDCS11_FCW_WarnTiming : 17|2@0+ (1,0) [0|3] "NoUnit" FLC_FD3
 SG_ CDCS11_FCTA_OnOffSet : 19|2@0+ (1,0) [0|3] "NoUnit" FLC_FD3
 SG_ CDCS11_RCTA_OnOffSet : 21|2@0+ (1,0) [0|3] "NoUnit" FLC_FD3
 SG_ CDCS11_RCW_OnOffSet : 23|2@0+ (1,0) [0|3] "NoUnit" FLC_FD3
 SG_ CDCS11_DOW_OnOffSet : 25|2@0+ (1,0) [0|3] "NoUnit" FLC_FD3
 SG_ CDCS11_IHBC_SysSwState : 27|2@0+ (1,0) [0|3] "NoUnit" FLC_FD3
 SG_ CDCS11_LCA_OnOffSet : 29|2@0+ (1,0) [0|3] "NoUnit" FLC_FD3
 SG_ CDCS11_TSR_OnOffSet : 31|2@0+ (1,0) [0|3] "NoUnit" FLC_FD3
 SG_ CDCS11_AVM_3DRotate : 33|2@0+ (1,0) [0|3] "NoUnit" FLC_FD3
 SG_ CDCS11_AVM_Turnlightstart : 35|2@0+ (1,0) [0|3] "NoUnit" FLC_FD3
 SG_ CDCS11_AVM_Steeringstart : 37|2@0+ (1,0) [0|3] "NoUnit" FLC_FD3
 SG_ CDCS11_AVM_Magnifiedview : 39|2@0+ (1,0) [0|3] "NoUnit" FLC_FD3
 SG_ CDCS11_AVM_MODdetection : 43|2@0+ (1,0) [0|3] "NoUnit" FLC_FD3
 SG_ CDCS11_GM_OnOffSet : 45|2@0+ (1,0) [0|3] "NoUnit" FLC_FD3
 SG_ CDCS11_NNP_OnOffSet : 47|2@0+ (1,0) [0|3] "NoUnit" FLC_FD3
 SG_ CDCS11_DCLCSysState : 49|2@0+ (1,0) [0|3] "NoUnit" FLC_FD3
 SG_ CDCS11_ALCSysState : 51|2@0+ (1,0) [0|3] "NoUnit" FLC_FD3
 SG_ CDCS11_DriveOffPossilbeswitch : 53|2@0+ (1,0) [0|3] "NoUnit" FLC_FD3
 SG_ CDCS11_DriveOffinhibitionswitch : 55|2@0+ (1,0) [0|3] "NoUnit" FLC_FD3
 SG_ CDCS11_ADAS_SndCtrlOnOff : 57|2@0+ (1,0) [0|3] "NoUnit" FLC_FD3
 SG_ CDCS11_AVM_auxiliaryline : 59|2@0+ (1,0) [0|3] "NoUnit" FLC_FD3
 SG_ CDCS11_AVM_Raderdisplay : 61|2@0+ (1,0) [0|3] "NoUnit" FLC_FD3
 SG_ CDCS11_AVM_Transparentchassis : 63|2@0+ (1,0) [0|3] "NoUnit" FLC_FD3
 SG_ CDCS11_VoiceMode : 65|2@0+ (1,0) [0|3] "NoUnit" FLC_FD3
 SG_ CDCS11_NNP_Active_OnOffSet : 67|2@0+ (1,0) [0|3] "NoUnit" FLC_FD3
 SG_ CDCS11_ALC_mode : 69|2@0+ (1,0) [0|3] "NoUnit" FLC_FD3
 SG_ CDCS11_ADSDriving_mode : 71|2@0+ (1,0) [0|3] "NoUnit" FLC_FD3
 SG_ CDCS11_TSR_OverspeedOnoffSet : 73|2@0+ (1,0) [0|3] "NoUnit" FLC_FD3
 SG_ CDCS11_NNP_AutoOnOffSet : 75|2@0+ (1,0) [0|3] "NoUnit" FLC_FD3
 SG_ CDCS11_SnCtrl_NNP_OnOff : 77|2@0+ (1,0) [0|3] "NoUnit" FLC_FD3
 SG_ CDCS11_GM_VidedIn : 79|2@0+ (1,0) [0|3] "NoUnit" FLC_FD3
 SG_ CDCS11_TSR_SLFOnOffSet : 81|2@0+ (1,0) [0|3] "NoUnit" FLC_FD3
 SG_ CDCS11_APA_FunctionMode : 85|4@0+ (1,0) [0|15] "NoUnit" FLC_FD3
 SG_ CDCS11_TrackreverseSW : 87|2@0+ (1,0) [0|3] "NoUnit" FLC_FD3
 SG_ CDCS11_SetPathwaySW : 89|2@0+ (1,0) [0|3] "NoUnit" FLC_FD3
 SG_ CDCS11_PA_changeLanguage : 91|2@0+ (1,0) [0|3] "NoUnit" FLC_FD3
 SG_ CDCS11_LDP_OnOffSet : 93|2@0+ (1,0) [0|3] "NoUnit" FLC_FD3
 SG_ CDCS11_AVMSw : 95|2@0+ (1,0) [0|3] "NoUnit" FLC_FD3
 SG_ CDCS11_tryHPP : 96|1@0+ (1,0) [0|1] "NoUnit" FLC_FD3
 SG_ CDCS11_RPASw : 99|2@0+ (1,0) [0|3] "NoUnit" FLC_FD3
 SG_ CDCS11_SetSw : 100|1@0+ (1,0) [0|1] "NoUnit" FLC_FD3
 SG_ CDCS11_SoundCtrlSetReq : 103|3@0+ (1,0) [0|7] "NoUnit" FLC_FD3
 SG_ CDCS11_location_sw : 104|1@0+ (1,0) [0|1] "NoUnit" FLC_FD3
 SG_ CDCS11_Pathrefresh : 105|1@0+ (1,0) [0|1] "NoUnit" FLC_FD3
 SG_ CDCS11_HPAGuideSW : 107|2@0+ (1,0) [0|3] "NoUnit" FLC_FD3
 SG_ CDCS11_HPAPathwaytoCloudSW : 109|2@0+ (1,0) [0|3] "NoUnit" FLC_FD3
 SG_ CDCS11_PathlearningSw : 111|2@0+ (1,0) [0|3] "NoUnit" FLC_FD3
 SG_ CDCS11_PA_screenMd : 115|4@0+ (1,0) [0|15] "NoUnit" FLC_FD3
 SG_ CDCS11_PASw : 118|3@0+ (1,0) [0|7] "NoUnit" FLC_FD3
 SG_ CDCS11_PA_Recover : 119|1@0+ (1,0) [0|1] "NoUnit" FLC_FD3
 SG_ CDCS_Lcsndrequest : 121|2@0+ (1,0) [0|3] "NoUnit" FLC_FD3
 SG_ CDCS_Lcsndconfirm : 123|2@0+ (1,0) [0|3] "NoUnit" FLC_FD3
 SG_ CDCS_SpdAdaptComfirm : 125|2@0+ (1,0) [0|3] "NoUnit" FLC_FD3
 SG_ CDCS_PayModeConfirm : 127|2@0+ (1,0) [0|3] "NoUnit" FLC_FD3
 SG_ CDCS11_SelectSlotID : 131|4@0+ (1,0) [0|15] "NoUnit" FLC_FD3
 SG_ CDCS11_ParkingInReq : 133|2@0+ (1,0) [0|3] "NoUnit" FLC_FD3
 SG_ CDCS11_ParkingOutReq : 135|2@0+ (1,0) [0|3] "NoUnit" FLC_FD3
 SG_ CDCS11_AVM_ViewMode : 137|2@0+ (1,0) [0|3] "NoUnit" FLC_FD3
 SG_ CDCS11_RPA_FunctionMode : 139|2@0+ (1,0) [0|3] "NoUnit" FLC_FD3
 SG_ CDCS11_AVM_VideoOutputFail : 140|1@0+ (1,0) [0|1] "NoUnit" FLC_FD3
 SG_ CDCS11_AVM_Initialization : 141|1@0+ (1,0) [0|1] "NoUnit" FLC_FD3
 SG_ CDCS11_AVM_bodySync : 143|2@0+ (1,0) [0|3] "NoUnit" FLC_FD3
 SG_ CDCS11_AVM_licenseplateabbr : 149|6@0+ (1,0) [0|63] "NoUnit" FLC_FD3
 SG_ CDCS11_AVM_SpeView : 151|2@0+ (1,0) [0|3] "NoUnit" FLC_FD3
 SG_ CDCS11_AVM_licenseplateArea : 156|5@0+ (1,0) [0|31] "NoUnit" FLC_FD3
 SG_ CDCS11_AVM_StartMode : 159|3@0+ (1,0) [0|7] "NoUnit" FLC_FD3
 SG_ CDCS11_AVM_LicensePlateNO1 : 165|6@0+ (1,0) [0|63] "NoUnit" FLC_FD3
 SG_ CDCS11_ELK_OnOffSet : 167|2@0+ (1,0) [0|3] "NoUnit" FLC_FD3
 SG_ CDCS11_AVM_LicensePlateNO2 : 173|6@0+ (1,0) [0|63] "NoUnit" FLC_FD3
 SG_ CDCS11_DrvOffAlertSwitch : 175|2@0+ (1,0) [0|3] "NoUnit" FLC_FD3
 SG_ CDCS11_AVM_LicensePlateNO3 : 181|6@0+ (1,0) [0|63] "NoUnit" FLC_FD3
 SG_ CDCS11_DCWposition : 183|2@0+ (1,0) [0|3] "NoUnit" FLC_FD3
 SG_ CDCS11_AVM_LicensePlateNO4 : 189|6@0+ (1,0) [0|63] "NoUnit" FLC_FD3
 SG_ CDCS11_AVM_LicensePlateNO5 : 197|6@0+ (1,0) [0|63] "NoUnit" FLC_FD3
 SG_ CDCS11_AVM_LicensePlateNO6 : 205|6@0+ (1,0) [0|63] "NoUnit" FLC_FD3
 SG_ CDCS11_DataUp_Trigger : 207|2@0+ (1,0) [0|3] "NoUnit" FLC_FD3
 SG_ CDCS11_AVM_LicensePlateNO7 : 213|6@0+ (1,0) [0|63] "NoUnit" FLC_FD3
 SG_ CDCS11_AVM_LicensePlateNO8 : 221|6@0+ (1,0) [0|63] "NoUnit" FLC_FD3
 SG_ CDCS11_AVM_Powertype : 223|2@0+ (1,0) [0|3] "NoUnit" FLC_FD3
 SG_ CDCS11_AVM_Diaphaneity : 227|4@0+ (1,0) [0|15] "NoUnit" FLC_FD3
 SG_ CDCS11_AVM_DiaphaneitySw : 228|1@0+ (1,0) [0|1] "NoUnit" FLC_FD3
 SG_ CDCS11_LDWLKAAidSwSts : 231|3@0+ (1,0) [0|3] "NoUnit" FLC_FD3
 SG_ CDCS11_MOD_Sound_Sw : 233|2@0+ (1,0) [0|3] "NoUnit" FLC_FD3
 SG_ CDCS11_MOD_BSD_Sw : 235|2@0+ (1,0) [0|3] "NoUnit" FLC_FD3
 SG_ CDCS11_PA_FRS_OnOffSet : 237|2@0+ (1,0) [0|3] "NoUnit" FLC_FD3
 SG_ CDCS11_PA_3D_OnOffSet : 239|2@0+ (1,0) [0|3] "NoUnit" FLC_FD3
 SG_ CDCS11_PA_measure_OnOffSet : 241|2@0+ (1,0) [0|3] "NoUnit" FLC_FD3
 SG_ CDCS11_MODSw : 243|2@0+ (1,0) [0|3] "NoUnit" FLC_FD3
 SG_ CDCS11_VoiceNotifFrequency_mode : 245|2@0+ (1,0) [0|3] "NoUnit" FLC_FD3
 SG_ CDCS11_ACCOnOffSet : 247|2@0+ (1,0) [0|3] "NoUnit" FLC_FD3
 SG_ CDCS11_HPASw : 249|2@0+ (1,0) [0|3] "NoUnit" FLC_FD3
 SG_ CDCS11_DeleteMapID : 263|8@0+ (1,0) [0|255] "NoUnit" FLC_FD3
 SG_ CDCS11_UploadMapID : 271|8@0+ (1,0) [0|255] "NoUnit" FLC_FD3
 SG_ CDCS11_HPAActiveConfirm : 274|1@0+ (1,0) [0|1] "NoUnit" FLC_FD3
 SG_ CDCS11_HPApreparkingSw : 278|2@0+ (1,0) [0|3] "NoUnit" FLC_FD3
 SG_ CDCS11_HPAPathwaytoCloud_WorkSts : 282|3@0+ (1,0) [0|7] "NoUnit" FLC_FD3
 SG_ CDCS11_HPA_ONPath_ID1 : 295|8@0+ (1,0) [0|255] "NoUnit" FLC_FD3
 SG_ CDCS11_HPA_ONPath_ID2 : 303|8@0+ (1,0) [0|255] "NoUnit" FLC_FD3
 SG_ CDCS11_HPA_ONPath_ID3 : 311|8@0+ (1,0) [0|255] "NoUnit" FLC_FD3
 SG_ CDCS11_HPA_ONPath_ID4 : 319|8@0+ (1,0) [0|255] "NoUnit" FLC_FD3
 SG_ CDCS11_HPA_Select_ID : 327|8@0+ (1,0) [0|255] "NoUnit" FLC_FD3
 SG_ CDCS11_PA_Select_ID : 335|8@0+ (1,0) [0|255] "NoUnit" FLC_FD3
 SG_ CDCS11_learnpath_St : 337|2@0+ (1,0) [0|3] "NoUnit" FLC_FD3
 SG_ CDCS11_LKAActvReq : 340|3@0+ (1,0) [0|7] "NoUnit" FLC_FD3
 SG_ CDCS11_TSR_LimitOverspeedSet : 351|8@0+ (1,0) [0|100] "%" FLC_FD3
 SG_ CDCS11_ParkingoutSlot_Type : 369|2@0+ (1,0) [0|3] "NoUnit" FLC_FD3
 SG_ CDCS11_ParkingoutSlot_Dire : 371|2@0+ (1,0) [0|3] "NoUnit" FLC_FD3
 SG_ CDCS11_OptionalSlot_Type : 373|2@0+ (1,0) [0|3] "NoUnit" FLC_FD3
 SG_ CDCS11_OptionalSlot_Dire : 360|3@0+ (1,0) [0|7] "NoUnit" FLC_FD3
 SG_ CDCS11_OptionalSlotAngle : 383|8@0+ (0.255,0) [0|65.025] "rad" FLC_FD3
 SG_ CDCS11_OptionalSlotCoor_P0_X : 391|16@0+ (1,0) [0|65535] "NoUnit" FLC_FD3
 SG_ CDCS11_OptionalSlotCoor_P0_Y : 407|16@0+ (1,0) [0|65535] "NoUnit" FLC_FD3
 SG_ CDCS11_OptionalSlotCoor_P1_X : 423|16@0+ (1,0) [0|65535] "NoUnit" FLC_FD3
 SG_ CDCS11_OptionalSlotCoor_P1_Y : 439|16@0+ (1,0) [0|65535] "NoUnit" FLC_FD3
 SG_ CDCS11_OptionalSlotCoor_P2_X : 455|16@0+ (1,0) [0|65535] "NoUnit" FLC_FD3
 SG_ CDCS11_OptionalSlotCoor_P2_Y : 471|16@0+ (1,0) [0|65535] "NoUnit" FLC_FD3
 SG_ CDCS11_OptionalSlotCoor_P3_X : 487|16@0+ (1,0) [0|65535] "NoUnit" FLC_FD3
 SG_ CDCS11_OptionalSlotCoor_P3_Y : 503|16@0+ (1,0) [0|65535] "NoUnit" FLC_FD3

BO_ 515 CDCS_Fr15_203: 16 Vector__XXX
 SG_ CDCS15_NNP_DriverStatus : 71|2@0+ (1,0) [0|3] "NoUnit" FLC_FD3
 SG_ CDCS15_Storage_St : 72|1@0+ (1,0) [0|1] "NoUnit" FLC_FD3
 SG_ CDCS15_USB_St : 73|1@0+ (1,0) [0|1] "NoUnit" FLC_FD3
 SG_ CDCS15_UserSceneMode : 79|4@0+ (1,0) [0|15] "NoUnit" FLC_FD3
 SG_ CDCS15_NNP_DriverFatigueStatus : 85|2@0+ (1,0) [0|3] "NoUnit" FLC_FD3
 SG_ CDCS15_NNP_DriverDistractedStatus : 87|2@0+ (1,0) [0|3] "NoUnit" FLC_FD3

BO_ 805 ICU_Fr02_325: 8 Vector__XXX
 SG_ ICU2_Odometer : 7|24@0+ (0.1,0) [0|1677721.4] "km" FLC_FD3

BO_ 305 ICU_Fr01_131: 8 Vector__XXX
 SG_ ICU1_VehicleSpdDisplayValid : 8|1@0+ (1,0) [0|1] "NoUnit" FLC_FD3
 SG_ ICU1_VehicleSpdDisplay : 7|10@0+ (0.5,0) [0|511] "NoUnit" FLC_FD3

BO_ 992 TBOX_Fr01_3E0: 8 Vector__XXX
 SG_ CalendarYear : 7|8@0+ (1,2000) [2000|2255] "NoUnit" FLC_FD3
 SG_ CalendarMonth : 11|4@0+ (1,0) [0|15] "NoUnit" FLC_FD3
 SG_ CalendarDay : 20|5@0+ (1,0) [0|31] "NoUnit" FLC_FD3
 SG_ HourOfDay : 28|5@0+ (1,0) [0|23] "NoUnit" FLC_FD3
 SG_ MinuteOfHour : 37|6@0+ (1,0) [0|59] "NoUnit" FLC_FD3
 SG_ SecsOfMinute : 45|6@0+ (1,0) [0|59] "NoUnit" FLC_FD3
 SG_ TimeDspFmt : 46|1@0+ (1,0) [0|1] "NoUnit" FLC_FD3

CM_ SG_ 579 AICS2_OTAMode "OTA模式进入及退出请求";
CM_ SG_ 579 AICS2_StopChargeing "断开充电";
CM_ SG_ 579 AICS2_BootRequestHVShut "OTA刷写三电下高压电请求";
CM_ SG_ 347 SWSM_A_CruiseDistance_Add "巡航跟车距离加开关";
CM_ SG_ 347 SWSM_A_CruiseDistance_Minus "巡航跟车距离减开关";
CM_ SG_ 347 SWSM_A_CruiseSpeed_Add "方向盘A区巡航车速+开关";
CM_ SG_ 347 SWSM_A_CruiseSpeed_Minus "方向盘A区巡航车速-开关";
CM_ SG_ 347 SWSM_A_SpeechInputSw "语音唤醒开关";
CM_ SG_ 347 Region_A_SwError "方向盘A区开关故障";
CM_ SG_ 347 SWSM_A_CD_Add_Overtime "CD加开关超时";
CM_ SG_ 347 SWSM_A_CD_Minus_Overtime "CD减开关超时";
CM_ SG_ 227 VCU5_ActGear "Strategy gear (VCU)";
CM_ SG_ 227 VCU5_ActGearValid "Strategy gear valid (VCU)";
CM_ SG_ 227 VCU5_READYLightSts "运动准备就绪指示灯";
CM_ SG_ 227 VCU5_PwrTrainFailureLevel "动力系统故障等级";
CM_ SG_ 227 VCU5_HVReady "高压准备就绪";
CM_ SG_ 227 VCU5_EmuEngineSts "模拟（仿真emulated）的引擎状态，用于start控制逻辑。";
CM_ SG_ 227 VCU5_AccelPositionValid "加速踏板行程有效位";
CM_ SG_ 227 VCU5_AccelPosition "加速踏板行程";
CM_ SG_ 227 VCU5_AliveCounter "E2E Profile2-CRC8H2F，Counter：0-15";
CM_ SG_ 227 VCU5_DriveMode_fb "驾驶模式反馈(VCU)";
CM_ SG_ 227 VCU5_DriverOvertakeMode "驾驶员超越模式";
CM_ SG_ 227 VCU5_Checksum "E2E Profile2-CRC8H2F
DataID List:#16 - 149 178 48 27 29 185 17 203 148 68 204 36 101 195 44 16";
CM_ SG_ 264 VCU14_PAAvailable "VCU是否满足APA控制要求";
CM_ SG_ 264 VCU14_ACC_Ready "VCU的ACC功能准备就绪，可以响应ACC扭矩请求";
CM_ SG_ 264 VCU14_PAActive "VCU反馈握手请求";
CM_ SG_ 264 VCU14_PA_ParkingFnMd "VCU反馈当前泊车功能模式";
CM_ SG_ 264 VCU14_PA_FailCode "VCU反馈VCU fail的原因";
CM_ SG_ 264 VCU14_Gear_PAActive "Gear反馈握手请求";
CM_ SG_ 264 VCU14_Gear_PAAvailable "Gear是否满足APA控制状态";
CM_ SG_ 264 VCU14_Gear_ErrorSts_M01 "系统故障信号";
CM_ SG_ 264 VCU4_PA_DeceltorSts "VCU是否支持负扭矩";
CM_ SG_ 264 VCU4_PA_TargetTrqValueValidity "VCU接收到PA目标扭力值有效位";
CM_ SG_ 264 VCU14_Gear_PACtrlAbortFeedback "Gear系统APA功能退出原因";
CM_ SG_ 264 VCU4_PA_TargetTrqValue "VCU接收到PA目标扭力值[-400,400]Nm";
CM_ SG_ 264 VCU14_Fr0E_MsgCounter "E2E Profile2-CRC8H2F，Counter：0-15";
CM_ SG_ 264 VCU14_Fr0E_Checksum "E2E Profile2-CRC8H2F
DataID List:#28 - 148 221 7 229 19 81 190 49 200 67 41 82 170 169 230 197";
CM_ SG_ 600 BMS3_StateOfCharge "电池电量SOC";
CM_ SG_ 600 BMS3_Charge_State "电池充电状态";
CM_ SG_ 170 MCU1_MotorSpeed "电机转速";
CM_ SG_ 170 MCU1_ControllerTorque "实际输出扭矩
包含MCU Damping torque";
CM_ SG_ 170 MCU1_AliveCounter "E2E Profile2-CRC8H2F，Counter：0-15";
CM_ SG_ 170 MCU1_presentActivityFault "当前活动最严重错误号";
CM_ SG_ 170 MCU1_CurrentTorque "实际扭力值
[-400,400] Nm";
CM_ SG_ 170 MCU1_CurrentTorqueValid "实际扭力值有效位";
CM_ SG_ 192 IDB2_FLWhlPulCnt "FL Wheel Pulse Counter";
CM_ SG_ 192 IDB2_FRWhlPulCnt "FR Wheel Pulse Counter";
CM_ SG_ 192 IDB2_FRWhlPulCntValid "FR Wheel Speed Sensor Validity";
CM_ SG_ 192 IDB2_FLWhlPulCntValid "FL Wheel Speed Sensor Validity";
CM_ SG_ 192 IDB2_Fr02_MsgCounter "E2E Profile2-CRC8H2F，Counter：0-15";
CM_ SG_ 192 IDB2_Fr02_Checksum "E2E Profile2-CRC8H2F
DataID List:#32 - 242 165 194 90 167 136 69 119 173 80 76 95 67 239 144 234";
CM_ SG_ 197 IDB3_VehicleSpdValid "Vehicle Speed Status 车速有效位";
CM_ SG_ 197 IDB3_VehicleSpd "Vehicle Speed 车速";
CM_ SG_ 197 IDB3_MasterCylPressure "主缸压力";
CM_ SG_ 197 IDB3_MsgCounter "E2E Profile2-CRC8H2F，Counter：0-15";
CM_ SG_ 197 IDB3_MasterCylPressureInvalid "主缸压力值有效性";
CM_ SG_ 197 IDB3_Checksum "E2E Profile2-CRC8H2F
DataID List:#54 - 87 57 114 13 81 177 37 40 90 82 133 184 56 248 43 107";
CM_ SG_ 199 IDB4_FLWhlVelocityValid "Wheel Ground Velocity FL Valid";
CM_ SG_ 199 IDB4_FLWhlVelocity "Wheel Ground Velocity FL";
CM_ SG_ 199 IDB4_FRWhlVelocityValid "Wheel Ground Velocity FR Valid";
CM_ SG_ 199 IDB4_FRWhlVelocity "Wheel Ground Velocity FR";
CM_ SG_ 199 IDB4_RRWhlDir "Wheel RR Directiion";
CM_ SG_ 199 IDB4_RLWhlDir "Wheel RL Directiion";
CM_ SG_ 199 IDB4_FRWhlDir "Wheel FR Directiion";
CM_ SG_ 199 IDB4_FLWhlDir "Wheel FL Directiion";
CM_ SG_ 199 IDB4_MsgCounter "E2E Profile2-CRC8H2F，Counter：0-15";
CM_ SG_ 199 IDB4_Checksum "E2E Profile2-CRC8H2F
DataID List:#2 - 180 134 53 233 243 121 67 176 9 94 168 132 198 142 201 138";
CM_ SG_ 199 IDB4_RRWhlVelocityValid "Wheel Ground Velocity RR Valid";
CM_ SG_ 199 IDB4_RLWhlVelocityValid "Wheel Ground Velocity RL Valid";
CM_ SG_ 199 IDB4_RLWhlVelocity "Wheel Ground Velocity RL";
CM_ SG_ 199 IDB4_RLWhlPulCntValid "RL Wheel Speed Sensor Validity";
CM_ SG_ 199 IDB4_RRWhlPulCntValid "RR Wheel Speed Sensor Validity";
CM_ SG_ 199 IDB4_RRWhlVelocity "Wheel Ground Velocity RR";
CM_ SG_ 199 IDB4_RLWhlPulCnt "RL Wheel Pulse Counter";
CM_ SG_ 199 IDB4_RRWhlPulCnt "RR Wheel Pulse Counter";
CM_ SG_ 201 IDB10_ADAS_DrvTorqueReq "Total driver torque of ADAS request";
CM_ SG_ 201 IDB10_ADAS_RegenTorqueReq "Total regenerative braking torque of ADAS request";
CM_ SG_ 201 IDB10_ADAS_DrvTorque "Total driver torque of ADAS";
CM_ SG_ 201 IDB10_ADAS_RegenTorque "Total regenerative braking torque of ADAS";
CM_ SG_ 229 IDB1_BrakePedalApplied "制动踏板踩下信号";
CM_ SG_ 229 IDB1_BrakePedalAppliedV "制动踏板踩下信号有效性";
CM_ SG_ 229 IDB1_BrakPedalDisp "制动踏板位移量";
CM_ SG_ 229 IDB1_BrakPedalDisp_Q "制动踏板位移量有效性";
CM_ SG_ 229 IDB1_CSTFail "CST功能失效";
CM_ SG_ 229 IDB1_CSTAtive "CST激活";
CM_ SG_ 229 IDB1_CSTEnabled "CST功能使能";
CM_ SG_ 229 IDB1_Brakestyle_Enabled "Brake style功能使能";
CM_ SG_ 229 IDB1_Brakestyle_Fail "Brake style功能失效";
CM_ SG_ 229 IDB1_FailedState "IDB/EHB故障及有效性";
CM_ SG_ 229 IDB1_Fr01_MsgCounter "E2E Profile2-CRC8H2F，Counter：0-15";
CM_ SG_ 229 IDB1_Fr01_Checksum "E2E Profile2-CRC8H2F
DataID List:#19 - 42 45 226 106 113 62 80 154 133 115 60 98 94 63 21 212";
CM_ SG_ 289 IDB9_BrakePedalPosition "制动踏板开度";
CM_ SG_ 297 IDB5_BrakeDiscTempSts "Over Temp status";
CM_ SG_ 297 IDB5_VehicleStanstill "Vehicle Stan still";
CM_ SG_ 297 IDB5_JerkActive "Jerk Active 点刹功能激活";
CM_ SG_ 297 IDB5_Jerkfail "Jerk fail 点刹功能失败";
CM_ SG_ 297 IDB5_ACC_ReqLim "Due to limitaion of the actuators the acceleration or deceleration request from FRM can not be processed or only partly";
CM_ SG_ 297 IDB5_DBSavailable "DBS function available";
CM_ SG_ 297 IDB5_Prefillavailable "Prefill function available";
CM_ SG_ 297 IDB5_AEB_Enable "This signal is set by the safety logic for AEB in the ESC";
CM_ SG_ 297 IDB5_ACC_Enable "This signal is set by the safety logic in the ESC.";
CM_ SG_ 297 IDB5_ACC_Sta "IDB ACC激活状态";
CM_ SG_ 297 IDB5_ACC_ReferenceAccel "Feedback signal for the inner acceleration control loop";
CM_ SG_ 297 IDB5_MsgCounter "E2E Profile2-CRC8H2F，Counter：0-15";
CM_ SG_ 297 IDB5_Checksum "E2E Profile2-CRC8H2F
DataID List:#58 - 204 92 25 9 246 113 123 47 41 35 210 115 157 97 39 37";
CM_ SG_ 299 IDB6_EPBStatus "EPB工作状态";
CM_ SG_ 299 IDB6_EPBAvailable "Availability of EPB";
CM_ SG_ 301 IDB7_ESCFail "Electric Stability Control  Fault";
CM_ SG_ 301 IDB7_ESCActive "Electric Stability Control Active";
CM_ SG_ 301 IDB7_ESCDisable "Electric Stability Control Driver Intent
(ESC_DISABLED)";
CM_ SG_ 301 IDB7_ABSActive "Antilock Brake System Active";
CM_ SG_ 301 IDB7_EBD_Fail "EBD Fault";
CM_ SG_ 301 IDB7_EBD_Active "EBD激活";
CM_ SG_ 301 IDB7_HBAActive "HBA激活";
CM_ SG_ 301 IDB7_HBAFail "HBA失效";
CM_ SG_ 301 IDB7_DiagMode "This signal indicate diagnostic mode condition";
CM_ SG_ 301 IDB7_TCSActive "Traction Control System Active";
CM_ SG_ 301 IDB7_TCSDisable "Traction Control System Driver Intent";
CM_ SG_ 301 IDB7_TCSFail "Traction Control System Fault";
CM_ SG_ 301 IDB7_ROPACTIVE "ROP激活";
CM_ SG_ 301 IDB7_ROPFailure "ROP失效";
CM_ SG_ 301 IDB7_DynParkBrkByIDBActive "Dynamic Parking Brake Activation by IDB";
CM_ SG_ 301 IDB7_DynParkBrkByIDBAvailable "Dynamic Parking Brake Available status by IDB";
CM_ SG_ 301 IDB7_HSAActive "坡道辅助";
CM_ SG_ 301 IDB7_HSAFail "坡道辅助故障";
CM_ SG_ 301 IDB7_HDCEnabled "HDC功能使能";
CM_ SG_ 301 IDB7_HDCFail "HDC功能失效";
CM_ SG_ 301 IDB7_HDCAtive "HDC激活";
CM_ SG_ 301 IDB7_ABSFail "Antilock Brake System Failed";
CM_ SG_ 301 IDB7_MsgCounter "E2E Profile2-CRC8H2F，Counter：0-15";
CM_ SG_ 301 IDB7_Checksum "E2E Profile2-CRC8H2F
DataID List:#12 - 159 194 20 136 217 173 214 95 89 144 158 77 230 186 51 205";
CM_ SG_ 302 IDB12_AVHDispMSG "Auto Hold System Display Message";
CM_ SG_ 302 IDB12_AVHLampReq "Auto Hold System Lamp Request";
CM_ SG_ 302 IDB12_AVHStatus "Auto Hold System Status";
CM_ SG_ 302 IDB12_AVHEnabled "AVH功能使能";
CM_ SG_ 177 EPS1_SteeringAngleValid "方向盘转角有效位";
CM_ SG_ 177 EPS1_SteerAngleSpdValid "方向盘角速度有效位";
CM_ SG_ 177 EPS1_HSTWCalibrated "方向盘水平位置标定状态";
CM_ SG_ 177 EPS1_WarningLampRed "EPS功能故障红色警示灯";
CM_ SG_ 177 EPS1_TorsionBarTorqueValid "转向杆扭矩有效位";
CM_ SG_ 177 EPS1_TorsionBarTorque "转向扭杆扭矩（驾驶员手力矩，左正右负）";
CM_ SG_ 177 EPS1_SteeringAngle "方向盘转角（左正右负）";
CM_ SG_ 177 EPS1_WarningLampYellow "EPS一般故障黄色警示灯";
CM_ SG_ 177 EPS1_SteerAngleSpd "方向盘角速度（左正右负）";
CM_ SG_ 177 EPS1_MsgCounter "E2E Profile2-CRC8H2F，Counter：0-15";
CM_ SG_ 177 EPS1_Checksum "E2E Profile2-CRC8H2F
DataID List:#7 - 12 243 207 94 6 201 30 183 35 143 78 190 188 108 16 38";
CM_ SG_ 178 EPS2_ADAS_Available "EPS ADAS功能可用状态";
CM_ SG_ 178 EPS2_ADAS_Active "EPS反馈ADAS功能激活状态";
CM_ SG_ 178 EPS2_AssistPraSwitchToDAS "EPS ADAS助力模式状态";
CM_ SG_ 178 EPS2_ADAS_CtrlAbortFeedback "EPS当前跳出ADAS的原因";
CM_ SG_ 178 EPS2_MotCntrl "电机控制扭矩 (left“+”,right“-” )";
CM_ SG_ 178 EPS2_PA_Available "EPS系统APA功能可用状态";
CM_ SG_ 178 EPS2_PA_Active "EPS反馈APA功能激活状态";
CM_ SG_ 178 EPS2_MotCntrlValid "电机扭矩有效性";
CM_ SG_ 178 EPS2_PA_CtrlAbortFeedback "EPS当前跳出APA的原因";
CM_ SG_ 178 EPS2_MsgCounter "E2E Profile2-CRC8H2F，Counter：0-15";
CM_ SG_ 178 EPS2_Checksum "E2E Profile2-CRC8H2F
DataID List:#10 - 4 65 1 42 110 208 168 45 211 25 191 226 12 167 122 106";
CM_ SG_ 142 ADCS2_ADAS_EPSAngleReqSt "ADAS横向控制对EPS的请求状态";
CM_ SG_ 142 ADCS2_EPS_LDPState "LDP功能状态";
CM_ SG_ 142 ADCS2_NNP_SystemFaultStatus "NNP故障状态";
CM_ SG_ 142 ADCS_Pilot_SystemFaultStatus "Pilot故障状态";
CM_ SG_ 142 ADCS2_ADAS_EPSLateralCtrlType "ADAS横向控制对EPS的请求类型";
CM_ SG_ 142 ADCS2_ADAS_EPSAngleReq "ADAS 请求转向角度值(left“+”,right“-” )";
CM_ SG_ 142 ADCS2_ADAS_IHBCSysState "IHBC System State";
CM_ SG_ 142 ADCS2_ALCDirection "变道转向灯请求";
CM_ SG_ 142 ADCS2_ACC_EpbReq "EPB请求信号(行车功能)";
CM_ SG_ 142 ADCS2_MsgCounter0 "E2E Profile2-CRC8H2F，Counter：0-15";
CM_ SG_ 142 ADCS2_EPS_ELKState "ELK功能状态";
CM_ SG_ 142 ADCS2_Checksum0 "E2E Profile2-CRC8H2F
DataID List:#4 - 158 161 150 33 238 151 203 19 139 104 55 2 184 16 105 67";
CM_ SG_ 142 ADCS2_AEBVehicleHoldReq "This signal means stop request flag by AEB";
CM_ SG_ 142 ADCS2_AEBFullBrake "This signal means flag which indicates that the deceleration command for AEB full braking is valid or not.";
CM_ SG_ 142 ADCS2_AEBPartialBrake "This signal means flag which indicates that the deceleration command for AEB partial braking is valid or not.";
CM_ SG_ 142 ADCS2_AEB_DBSLevel "This signal means command to use lowered DBS (Dynamic Braking Support) threshold to determine the DBS entrance";
CM_ SG_ 142 ADCS2_AEBPrefillReq "This signal means command to activate pre-fill";
CM_ SG_ 142 ADCS2_AEB_JerkReq "AEB点刹报警请求";
CM_ SG_ 142 ADCS2_AEBTargetDeceleration "This signal means deceleration command for AEB braking";
CM_ SG_ 142 ADCS2_longitudCtrlType "ADAS纵向控制请求类型";
CM_ SG_ 142 ADCS2_LongitudCtrlDecToStopReq "ADAS纵向控制减速到停请求";
CM_ SG_ 142 ADCS2_LongitudCtrlDriveOff "ADAS纵向控制起步请求";
CM_ SG_ 142 ADCS2_AEB_JerkLevel "Jerk等级";
CM_ SG_ 142 ADCS2_LongitudCtrlAccelCtrlReq "ADAS纵向控制请求";
CM_ SG_ 142 ADCS2_LongitudCtrlTargetAccel "ADAS纵向控制请求值";
CM_ SG_ 143 ADCS11_Parking_WorkSts "泊车工作状态信号";
CM_ SG_ 310 ADCS12_FCWWarnAudioplay "FCW报警类型语音播报";
CM_ SG_ 310 ADCS12_RCTAWarnAudioplay "RCTA报警类型语音播报";
CM_ SG_ 310 ADCS12_FCTAWarnAudioplay "FCTA报警类型语音播报";
CM_ SG_ 310 ADCS12_SpeedWarnAudioplay "超速语音播报";
CM_ SG_ 310 ADCS12_DOWWarnAudioplay "DOW报警类型语音播报";
CM_ SG_ 310 ADCS12_DCLCAudioplay "DCLC语音播报";
CM_ SG_ 310 ADCS12_PilotAudioPlay "Pilot语音播报";
CM_ SG_ 310 ADCS12_HandOffAudioplay "脱手语音播报";
CM_ SG_ 310 ADCS12_NNPCancelAudioPlay "NNP_cancel语音播报";
CM_ SG_ 310 ADCS12_RCWWarnAudioplay "RCW报警类型语音播报";
CM_ SG_ 310 ADCS12_MRMAudioPlay "MRM语音播报";
CM_ SG_ 310 ADCS12_NNP_ResumeAudioplay "NNP_Resume语音播报";
CM_ SG_ 310 ADCS12_Lcsndrequest "语音变道反馈";
CM_ SG_ 310 ADCS12_Lcsndrconfirm "主动变道驾驶员确认反馈";
CM_ SG_ 310 ADCS12_DriveOffBroadcast "起步提醒播报";
CM_ SG_ 310 ADCS12_EyeOffBroadcast "脱眼语音播报";
CM_ SG_ 310 ADCS12_longitudDisableInfo "不可开启原因";
CM_ SG_ 310 ADCS12_SpeedAdaptComfirm "速度匹配确认反馈信号";
CM_ SG_ 310 ADCS12_PayModeConfirm "收费站匹配确认反馈信号";
CM_ SG_ 310 ADCS12_longitudCtrlSysInfo "HMI文字显示";
CM_ SG_ 310 ADCS12_ADAS_DriveOffinhibition "前车起步抑制请求";
CM_ SG_ 310 ADCS12_P2N_State_Reminder "NNP升降级状态";
CM_ SG_ 310 ADCS12_NNP_State_Reminder "NNP_语音状态提醒";
CM_ SG_ 310 ADCS12_NNP_LightRemind "NNP_语音提示关闭转向灯提醒";
CM_ SG_ 310 ADCS12_LaneChangePendingAlert "变道等待超时提醒";
CM_ SG_ 310 ADCS12_NPilotSysInfo "Npilot信息显示";
CM_ SG_ 310 ADCS12_LCAudioPlay "变道语音提醒";
CM_ SG_ 310 ADCS12_NNP_Scenarios_AudioPlay "NNP所有场景语音提醒";
CM_ SG_ 310 ADCS12_NNP_RINO "NNP进入匝道相关提醒";
CM_ SG_ 403 ADCS8_LDWState "LDW功能状态";
CM_ SG_ 403 ADCS8_LDWWarnState "LDW报警状态";
CM_ SG_ 403 ADCS8_ELKMode "ELK功能模式";
CM_ SG_ 403 ADCS8_LDPELKWarnState "LDPELK报警状态";
CM_ SG_ 403 ADCS8_lateralCtrHandsEyesOffWarning "Hands-off Warning Display";
CM_ SG_ 403 ADCS8_LKSSetspeed "LKA激活速度反馈";
CM_ SG_ 403 ADCS8_ACCState "HMI显示";
CM_ SG_ 403 ADCS8_lateralCtrtakeover "驾驶员接管请求";
CM_ SG_ 403 ADAS8_LateralCtrHandOffReleasewarning "HandOffReleasewarning";
CM_ SG_ 403 ADCS8_LDPELKtakeoverWarningstate "LDPELK接管报警状态";
CM_ SG_ 403 ADCS8_longitudCtrlSetSpeed "设定速度";
CM_ SG_ 403 ADCS8_NNP_Scenarios "NNP所有场景显示提醒";
CM_ SG_ 403 ADCS8_longitudCtrlTakeOverReq "ADAS纵向控制接管请求";
CM_ SG_ 403 ADCS8_longitudCtrlSetDistance "设定时距";
CM_ SG_ 403 ADCS8_longitudCtrlTargetValidity "是否有目标";
CM_ SG_ 403 ADCS8_ACCSystemFaultStatus "This signal means the ACC system health.";
CM_ SG_ 403 ADCS8_AEB_SystemFaultStatus "AEB状态";
CM_ SG_ 403 ADCS8_AEB_SystemStatus "This signal means indication of AEB On/Off Status";
CM_ SG_ 403 ADCS8_FCWSystemFaultStatus "FCW系统故障";
CM_ SG_ 403 ADCS8_FCWStatus "FCW报警状态";
CM_ SG_ 403 ADCS8_FCWSensitiveLevel "FCW灵敏度反馈";
CM_ SG_ 403 ADCS8_FCW_State "FCW开关状态反馈";
CM_ SG_ 403 ADCS8_FCTA_State "FCTA开关状态反馈";
CM_ SG_ 403 ADCS8_AILampMode "AI灯语显示需求";
CM_ SG_ 403 ADCS8_CDCS_CertificateState2 "PKI证书状态(行车)";
CM_ SG_ 403 ADCS8_FCTA_SystemFaultStatus "FCTA故障状态";
CM_ SG_ 403 ADCS8_FCTAWarnObjType "FCTA报警类型";
CM_ SG_ 403 ADCS8_FCTARightActiveSt "FCTA右报警状态";
CM_ SG_ 403 ADCS8_FCTALeftActiveSt "FCTA左报警状态";
CM_ SG_ 403 ADCS8_RCTA_SystemFaultStatus "RCTA故障状态";
CM_ SG_ 403 ADCS8_RCTARightWarnSt "RCTA右报警状态";
CM_ SG_ 403 ADCS8_RCTALeftWarnSt "RCTA左报警状态";
CM_ SG_ 403 ADCS8_RCTA_State "RCTA开关状态反馈";
CM_ SG_ 403 ADCS8_DOW_State "DOW开关状态反馈";
CM_ SG_ 403 ADCS8_RCW_SystemFaultStatus "RCW故障状态";
CM_ SG_ 403 ADCS8_RCW_WarnState "RCW报警状态";
CM_ SG_ 403 ADCS8_RCW_State "RCW开关状态反馈";
CM_ SG_ 403 ADCS8_ADAS_IHBCStat "IHBC System Option Information";
CM_ SG_ 403 ADCS8_DOW_SystemFaultStatus "DOW故障状态";
CM_ SG_ 403 ADCS8_DOWRightWarnState "DOW Right报警状态（包括前后门）";
CM_ SG_ 403 ADCS8_DOWLeftWarnState "DOW Left报警状态（包括前后门）";
CM_ SG_ 403 ADCS8_LCAState "LCA开关状态反馈";
CM_ SG_ 403 ADCS8_HornReq "请求喇叭响(行车)";
CM_ SG_ 403 ADCS8_DoorUnlock "ADCS解锁车门指令";
CM_ SG_ 403 ADCS8_ADAS_HazardLampReq "RCW触发二级报警后，请求报警灯双闪";
CM_ SG_ 403 ADCS8_LKAActvSts "车道偏离辅助设置反馈信号";
CM_ SG_ 403 ADCS8_LCALeftWarnSt "LCA（BSD）左报警";
CM_ SG_ 403 ADCS8_LCARightWarnSt "LCA（BSD）右报警";
CM_ SG_ 403 ADCS8_ACCOnOffState "ADCS巡航开关信号反馈";
CM_ SG_ 403 ADCS8_TSR_SpeedSign "TSR限速标志";
CM_ SG_ 403 ADCS8_TSRState "TSR开关状态反馈";
CM_ SG_ 403 ADCS8_LCASystemFaultStatus "LCA故障状态";
CM_ SG_ 403 ADCS8_TSR_ForbiddenSign "TSR禁止标志";
CM_ SG_ 403 ADCS8_NNP_SOAAudioplay "障碍避让语音提醒";
CM_ SG_ 403 ADCS8_TSR_SLFStatefeedback "智能限速开关";
CM_ SG_ 403 ADCS8_TSR_SpeedWarnState "TSR限速报警";
CM_ SG_ 403 ADCS8_TSR_SystemFaultStatus "TSR故障状态";
CM_ SG_ 403 ADCS8_TSR_StrLightColor "TSR直行信号灯状态";
CM_ SG_ 403 ADCS8_TSR_RightLightColor "TSR右转信号灯状态";
CM_ SG_ 403 ADCS8_TSR_LeftLightColor "TSR左转信号灯状态";
CM_ SG_ 403 ADCS8_VoiceNotifFrequency_mode "导航播报模式反馈";
CM_ SG_ 403 ADCS8_NPilot_SystemFaultStatus "N-Pilot故障状态";
CM_ SG_ 403 ADCS8_NPilot_SysState "N-pilot System State";
CM_ SG_ 403 ADCS8_NNP_AutoOnOffSet "NNP自动开启开关（NNP设置项）";
CM_ SG_ 403 ADCS8_NNP_SystemFaultStatus "NNP故障状态";
CM_ SG_ 403 ADCS8_NNPSysState "NNP系统状态";
CM_ SG_ 403 ADCS8_DrvOffAlertState "起步提醒状态";
CM_ SG_ 403 ADCS8_DrvOffAlertSwitch "起步提醒开关反馈";
CM_ SG_ 403 ADCS8_DrvOffAlert_SystemFaultStatus "起步提醒系统故障状态";
CM_ SG_ 403 ADCS8_Lanechangeinfor "Lane change 提醒";
CM_ SG_ 403 ADCS8_DCLCSysState "DCLC开关状态";
CM_ SG_ 403 ADCS8_LaneChangeSystemFaultStatus "变道功能故障";
CM_ SG_ 403 ADCS8_LaneChangeWarning "变道危险报警（仪表显示）";
CM_ SG_ 403 ADCS8_ADAS_DriveOffPossilbe "前车起步提醒";
CM_ SG_ 403 ADCS8_SRR_FL_Fail "角雷达故障（FL）";
CM_ SG_ 403 ADCS8_FRS_Fail "前雷达故障";
CM_ SG_ 403 ADCS8_SRR_RL_Fail "角雷达故障（RL）";
CM_ SG_ 403 ADCS8_DriveOffinhibitionObjType "起步抑制的目标类型";
CM_ SG_ 403 ADCS8_SVC_RL_Fail "侧视摄像头故障（RL）";
CM_ SG_ 403 ADCS8_SVC_FL_Fail "侧视摄像头故障（FL）";
CM_ SG_ 403 ADCS8_SRR_RR_Fail "角雷达故障（RR）";
CM_ SG_ 403 ADCS8_SRR_FR_Fail "角雷达故障（FR）";
CM_ SG_ 403 ADCS8_TSR_OverspeedOnOffSet "超速报警开关";
CM_ SG_ 403 ADCS8_RVC_Fail "后视摄像头故障";
CM_ SG_ 403 ADCS8_VoiceMode "语音播报模式";
CM_ SG_ 403 ADCS8_ALC_mode "自动变道设置反馈";
CM_ SG_ 403 ADCS8_NNP_State "NNP总开关状态反馈";
CM_ SG_ 403 ADCS8_FVC_120_Fail "120°前视摄像头故障";
CM_ SG_ 403 ADCS8_Lanechangedirection "变道方向提示";
CM_ SG_ 403 ADCS8_ADSDriving_mode "自动驾驶风格选项设置反馈";
CM_ SG_ 403 ADCS8_FVC_30_Fail "30°前视摄像头故障";
CM_ SG_ 403 ADCS8_SVC_RR_Fail "侧视摄像头故障（RR）";
CM_ SG_ 403 ADCS8_SVC_FR_Fail "侧视摄像头故障（FR）";
CM_ SG_ 403 ADCS8_NNP_MRM_status "NNP_MRM（靠边停车）报警";
CM_ SG_ 403 ADCS8_NpilotOverride_State "NPilot_功能暂停";
CM_ SG_ 403 ADCS8_SystemFault "ADAS系统故障指示（行车）";
CM_ SG_ 403 ADCS8_LeftLidarFault "左激光雷达故障";
CM_ SG_ 403 ADCS8_RightlidarFault "右激光雷达故障";
CM_ SG_ 403 ADCS8_NNP_SpeedLimit "规控选取的限速值";
CM_ SG_ 403 ADCS8_TSR_LimitOverspeedSet "交通标志识别（TSR）的增加子功能用户可设置限定的超速值进行超速报警提醒";
CM_ SG_ 403 ADCS8_FLC_LDWLKAAid_OnOff_fbk "ELKS（LDW+LKA）
紧急车道保持系统设置反馈";
CM_ SG_ 403 ADCS8_DOWVoiceWarnSt "DOW功能声音报警与视觉报警解耦";
CM_ SG_ 403 ADCS8_Pilot_WorkMod "Pilot工作模式信号";
CM_ SG_ 403 ADCS8_HandShakeSts "脱手状态信号";
CM_ SG_ 403 ADCS8_DCLC_SubStatus "DCLC变道状态机信号";
CM_ SG_ 403 ADCS8_DCLC_AutChgLane "当前DCLC无变道执行状态信号";
CM_ SG_ 404 ADCS8_RPA_CheckListDispReq6 "自检条目清单中坡度状态";
CM_ SG_ 404 ADCS8_RPA_CheckListDispReq5 "自检条目清单中胎压状态";
CM_ SG_ 404 ADCS8_RPA_CheckListDispReq4 "自检条目清单中EPB状态";
CM_ SG_ 404 ADCS8_RPA_CheckListDispReq3 "自检条目清单中档位状态";
CM_ SG_ 404 ADCS8_RPA_CheckListDispReq2 "自检条目清单中车速状态";
CM_ SG_ 404 ADCS8_RPA_CheckListDispReq1 "自检条目清单中四门两盖状态";
CM_ SG_ 404 ADCS8_PA_warninginfo "RPA发送工作状态提示信息";
CM_ SG_ 404 ADCS8_PA_FPAS_SnsrObjWrnngZn_FLM "左前中目标障碍物报警区域";
CM_ SG_ 404 ADCS8_PA_FPAS_SnsrObjWrnngZn_FLC "左前目标障碍物报警区域";
CM_ SG_ 404 ADCS8_RPA_CheckListDispReq8 "自检条目清单中关联系统故障状态";
CM_ SG_ 404 ADCS8_RPA_CheckListDispReq7 "自检条目清单中RPA系统故障状态";
CM_ SG_ 404 ADCS8_PA_FPAS_SnsrObjWrnngZn_FRC "右前目标障碍物报警区域";
CM_ SG_ 404 ADCS8_PA_FPAS_SnsrObjWrnngZn_FRM "右前中目标障碍物报警区域";
CM_ SG_ 404 ADCS8_PA_FPAS_SnsrObjWrnngZn_RLM "左后中目标障碍物报警区域";
CM_ SG_ 404 ADCS8_PA_FPAS_SnsrObjWrnngZn_RLC "左后目标障碍物报警区域";
CM_ SG_ 404 ADCS8_PA_FPAS_SnsrObjWrnngZn_RRC "右后目标障碍物报警区域";
CM_ SG_ 404 ADCS8_PA_FPAS_SnsrObjWrnngZn_RRM "右后中目标障碍物报警区域";
CM_ SG_ 404 ADCS8_PA_FPAS_SnsrObjWrnngZn_SFR "右前侧目标障碍物报警区域";
CM_ SG_ 404 ADCS8_PA_FPAS_SnsrObjWrnngZn_SFL "左前侧目标障碍物报警区域";
CM_ SG_ 404 ADCS8_PA_FPAS_SnsrObjWrnngZn_SRR "右后侧目标障碍物报警区域";
CM_ SG_ 404 ADCS8_PA_FPAS_SnsrObjWrnngZn_SRL "左后侧目标障碍物报警区域";
CM_ SG_ 404 ADCS8_PA_FPAS_SnsrDist_FLC "左前超声波传感器障碍物距离";
CM_ SG_ 404 ADCS8_PA_FPAS_SnsrDist_FLM "左前中超声波传感器障碍物距离";
CM_ SG_ 404 ADCS8_PA_FPAS_SnsrDist_FRM "右前中超声波传感器障碍物距离";
CM_ SG_ 404 ADCS8_PA_FPAS_SnsrDist_FRC "右前超声波传感器障碍物距离";
CM_ SG_ 404 ADCS8_PA_FPAS_SnsrDist_RLC "左后超声波传感器障碍物距离";
CM_ SG_ 404 ADCS8_PA_FPAS_SnsrDist_RLM "左后中超声波传感器障碍物距离";
CM_ SG_ 404 ADCS8_PA_FPAS_SnsrDist_RRM "右后中超声波传感器障碍物距离";
CM_ SG_ 404 ADCS8_PA_FPAS_SnsrDist_RRC "右后超声波传感器障碍物距离";
CM_ SG_ 404 ADCS8_PA_FPAS_SnsrDist_SFL "左前侧超声波传感器障碍物距离";
CM_ SG_ 404 ADCS8_PA_FPAS_SnsrDist_SFR "右前侧超声波传感器障碍物距离";
CM_ SG_ 404 ADCS8_PA_FPAS_SnsrDist_SRL "左后侧超声波传感器障碍物距离";
CM_ SG_ 404 ADCS8_PA_FPAS_SnsrDist_SRR "右后侧超声波传感器障碍物距离";
CM_ SG_ 404 ADCS8_PA_FPAS_SensorFaultStsFRC "右前超声波传感器故障";
CM_ SG_ 404 ADCS8_PA_FPAS_SensorFaultStsFRM "右前中超声波传感器故障";
CM_ SG_ 404 ADCS8_PA_FPAS_SensorFaultStsFLM "左前中超声波传感器故障";
CM_ SG_ 404 ADCS8_PA_FPAS_SensorFaultStsFLC "左前超声波传感器故障";
CM_ SG_ 404 ADCS8_PA_RPAS_WorkSts "后超声波工作状态";
CM_ SG_ 404 ADCS8_PA_FPAS_WorkSts "前超声波工作状态";
CM_ SG_ 404 ADCS8_PA_RPAS_SensorFaultStsSRR "右后侧超声波传感器故障";
CM_ SG_ 404 ADCS8_PA_RPAS_SensorFaultStsSRL "左后侧超声波传感器故障";
CM_ SG_ 404 ADCS8_PA_FPAS_SensorFaultStsSFR "右前侧超声波传感器故障";
CM_ SG_ 404 ADCS8_PA_FPAS_SensorFaultStsSFL "左前侧超声波传感器故障";
CM_ SG_ 404 ADCS8_PA_RPAS_SensorFaultStsRRC "右后超声波传感器故障";
CM_ SG_ 404 ADCS8_PA_RPAS_SensorFaultStsRRM "右后中超声波传感器故障";
CM_ SG_ 404 ADCS8_PA_RPAS_SensorFaultStsRLM "左后中超声波传感器故障";
CM_ SG_ 404 ADCS8_PA_RPAS_SensorFaultStsRLC "左后超声波传感器故障";
CM_ SG_ 404 ADCS8_AudBpRate_R "后雷达声音报警频率";
CM_ SG_ 404 ADCS8_AudBpRate_F "前雷达声音报警频率";
CM_ SG_ 404 ADCS8_AVM_MODWarning "MOD报警音";
CM_ SG_ 404 ADCS8_AVM_RomoteAVMFeedBack "AVM远程启动状态反馈";
CM_ SG_ 404 ADCS8_PA_FPAS_SnsrObjWrnngZn_RSDW "侧翼保护报警区域信号";
CM_ SG_ 404 ADCS8_PA_FPAS_SnsrObjWrnngZn_LSDW "侧翼保护报警区域信号";
CM_ SG_ 404 ADCS8_PA_FPAS_SnsrObjWrnnglc_RSDW "侧翼保护报警位置信号";
CM_ SG_ 404 ADCS8_PA_FPAS_SnsrObjWrnnglc_LSDW "侧翼保护报警位置信号";
CM_ SG_ 404 ADCS8_Mod_Object_MovingDirection "MOD报警方位";
CM_ SG_ 1556 FLC_SourceNodeIdentifier "ECU节点标识符";
CM_ SG_ 1556 FLC_RepeatMessageRequest "Repeat Message请求";
CM_ SG_ 1556 FLC_Reserve1 "预留";
CM_ SG_ 1556 FLC_ActiveWakeup "激活唤醒，主动唤醒网络时置1，其他（包括被动唤醒节点）为0";
CM_ SG_ 1556 FLC_Reserve2 "预留";
CM_ SG_ 1556 FLC_WakeUp_KL15 "KL15 ON唤醒";
CM_ SG_ 1556 FLC_WakeUp_NM "NM报文唤醒";
CM_ SG_ 1556 FLC_WakeUpReason4 "网络唤醒原因4";
CM_ SG_ 1556 FLC_WakeUpReason5 "网络唤醒原因5";
CM_ SG_ 1556 FLC_WakeUpReason6 "网络唤醒原因6";
CM_ SG_ 1556 FLC_WakeUpReason7 "网络唤醒原因7";
CM_ SG_ 1556 FLC_WakeUpReason8 "网络唤醒原因8";
CM_ SG_ 1556 FLC_RNM_DOW "DOW功能，需整车延迟休眠3min";
CM_ SG_ 196 ACU2_LatAccSensorValueV "Lateral Acceleration Sensor Value Validity";
CM_ SG_ 196 ACU2_LatAccSensorValue "Lateral Acceleration Sensor Value";
CM_ SG_ 196 ACU2_VehicleDynYawRateV "Vehicle Dynamics Yaw Rate Validity";
CM_ SG_ 196 ACU2_Sensorcalibration "组合传感器零位是否标定
Sensor calibration or not";
CM_ SG_ 196 ACU2_LongAccSensorValueV "Longitude Acceleration Sensor Value Validity";
CM_ SG_ 196 ACU2_LongAccSensorValue "Longitude Acceleration Sensor Value";
CM_ SG_ 196 ACU2_VehicleDynYawRate "Vehicle Dynamics Yaw Rate";
CM_ SG_ 196 ACU2_MsgCounter "E2E Profile2-CRC8H2F，Counter：0-15";
CM_ SG_ 196 ACU2_Checksum "E2E Profile2-CRC8H2F
DataID List:#26 - 39 175 13 15 49 40 145 209 184 197 98 107 118 202 100 99";
CM_ SG_ 258 ACU1_Driver_Buckle "Driver Buckle status on CAN Bus
驾驶员安全带状态";
CM_ SG_ 258 ACU1_Passenger_Buckle "Passenger Buckle status on CAN Bus
副驾安全带状态";
CM_ SG_ 258 ACU1_Passenger_ODS "Passenger ODS  status on CAN Bus
副驾占位传感器状态";
CM_ SG_ 258 ACU1_CrashStatus "Crash status on CAN Bus
碰撞信号";
CM_ SG_ 258 ACU1_warningLight "Airbag System Fault
安全气囊故障警报灯";
CM_ SG_ 258 ACU1_Rear_Right_Buckle "Rear Right Buckle status on CAN Bus
后排右侧安全带状态";
CM_ SG_ 258 ACU1_Rear_Left_Buckle "Rear Left Buckle status on CAN Bus
后排左侧安全带状态";
CM_ SG_ 258 ACU1_Rear_Middle_Buckle "Rear Middle Buckle status on CAN Bus
后排中间安全带状态";
CM_ SG_ 258 ACU1_Rear_Left_ODS "Rear Left Passenger ODS status on CAN Bus后排左侧占位传感器状态";
CM_ SG_ 258 ACU1_Rear_Middle_ODS "Rear Left Passenger ODS status on CAN Bus后排中间侧占位传感器状态";
CM_ SG_ 258 ACU1_Rear_Right_ODS "Rear Left Passenger ODS status on CAN Bus
后排右侧占位传感器状态";
CM_ SG_ 258 ACU1_Rear_Left_BuckleSts_Logic "Rear Left Buckle status After Logic
后排左侧安全带状态(与占位开关逻辑后)";
CM_ SG_ 258 ACU1_Rear_Midlle_BuckleSts_Logic "Rear Middle Buckle status After Logic
后排中间侧安全带状态(与占位开关逻辑后)";
CM_ SG_ 258 ACU1_Rear_Right_BuckleSts_Logic "Rear Left Buckle status After Logic
后排右侧安全带状态(与占位开关逻辑后)";
CM_ SG_ 272 BDCS1_PowerMode "低压电源模式";
CM_ SG_ 272 BDCS1_PowerManageMode "低压电源管理模式";
CM_ SG_ 272 BDCS1_LowBeamSt "近光灯状态";
CM_ SG_ 272 BDCS1_HighBeamSt "远光灯状态";
CM_ SG_ 272 BDCS1_PositionLightSts "位置灯状态";
CM_ SG_ 272 BDCS1_BacklightStatus "整车背光灯状态";
CM_ SG_ 272 BDCS1_LeftTurnLightSt "左转向灯状态";
CM_ SG_ 272 BDCS1_RightTurnLightSt "右转向灯状态";
CM_ SG_ 272 BDCS1_FrontLampSt "前照灯开关";
CM_ SG_ 272 BDCS1_HazardLampSt "危险报警灯状态";
CM_ SG_ 272 BDCS1_HighBeamSW "远光灯开关状态";
CM_ SG_ 272 BDCS1_TurnLightSW "转向灯开关";
CM_ SG_ 272 BDCS1_HazardSwSt "危险报警灯开关状态";
CM_ SG_ 272 BDCS1_RearFogLampSt "后雾灯状态";
CM_ SG_ 272 BDCS1_FrontFogLampSt "前雾灯状态（预留）";
CM_ SG_ 272 BDCS1_TrunkLockSts "后背门锁状态（是否电动尾门，该信号均作为提示尾门是否开启）";
CM_ SG_ 272 BDCS1_HoodAjarSts "前舱盖开闭状态";
CM_ SG_ 272 BDCS1_MsgCounter "E2E Profile2-CRC8H2F，Counter：0-15";
CM_ SG_ 272 BDCS1_Checksum "E2E Profile2-CRC8H2F
DataID List:#60 - 174 124 106 58 47 154 237 220 98 37 173 212 59 125 101 188";
CM_ SG_ 274 BDCS3_RemoteAuthenSts "远程认证状态";
CM_ SG_ 274 BDCS3_BackDoorAjar "电动尾门位置状态";
CM_ SG_ 274 BDCS3_ADCSAuthenSts "与ADCS认证状态";
CM_ SG_ 276 CS1_FrontWiperMISTReqSt "前雨刮MIST请求状态";
CM_ SG_ 276 CS1_HighBeamFlashReqSt "超车灯信号";
CM_ SG_ 276 CS1_HighBeamReqSt "远光灯信号";
CM_ SG_ 276 CS1_TurnLightReqSt "转向灯";
CM_ SG_ 276 CS1_FrontWiperReqSt "前雨刮";
CM_ SG_ 276 CS1_FrontWiperWashReqSt "前洗涤";
CM_ SG_ 276 CS1_RearWiperReqSt_Reserved "后雨刮";
CM_ SG_ 276 CS1_RearWiperWashReqSt_Reserved "后洗涤";
CM_ SG_ 276 CS1_GearPositionReqSt "档位请求信号";
CM_ SG_ 276 CS1_GearPositionReqStInv "档位请求信号取反";
CM_ SG_ 276 CS1_GearPositionReqStValid "档位请求信号有效性";
CM_ SG_ 276 CS1_MsgCounter "E2E Profile2-CRC8H2F，Counter：0-15";
CM_ SG_ 276 CS1_Checksum "E2E Profile2-CRC8H2F
DataID List:#71 - 213 235 162 78 53 174 81 206 45 121 159 124 52 82 9 3";
CM_ SG_ 486 BDCS6_FrontWiperParkPos "前雨刮回位开关状态";
CM_ SG_ 486 BDCS6_FrontWiperSts "前雨刮工作状态";
CM_ SG_ 486 BDCS6_DayNightMode "白天夜晚模式";
CM_ SG_ 645 BDCS13_RLS_RQ_WiperSPD "雨刮速度";
CM_ SG_ 418 DDCU1_FL_WinPos "左前车窗位置信息(0%关闭100%全开)";
CM_ SG_ 418 DDCU1_RL_WinPos "左后车窗位置信息(0%关闭100%全开)";
CM_ SG_ 418 DDCU1_FLDoorAjar "左前车门开闭状态";
CM_ SG_ 418 DDCU1_RLDoorAjar "左后车门开闭状态";
CM_ SG_ 418 DDCU1_MirrorFoldSt "外后视镜折叠状态";
CM_ SG_ 419 PDCU1_FR_WinPos "右前车窗位置信息(0%关闭100%全开)";
CM_ SG_ 419 PDCU1_RR_WinPos "右后车窗位置信息(0%关闭100%全开)";
CM_ SG_ 419 PDCU1_FRDoorAjar "右前车门开闭状态";
CM_ SG_ 419 PDCU1_RRDoorAjar "右后车门开闭状态";
CM_ SG_ 320 CDCS3_ESCOffSw "ESC OFF开关";
CM_ SG_ 320 CDCS3_HDCSw "HDC开关";
CM_ SG_ 320 CDCS3_DriveModeSet "驾驶模式选择";
CM_ SG_ 320 CDCS3_Xcoordinate "IHU坐标X";
CM_ SG_ 320 CDCS3_Ycoordinate "IHU坐标Y";
CM_ SG_ 320 CDCS3_XGestureSpd "IHU坐标X速度";
CM_ SG_ 320 CDCS3_YGestureSpd "IHU坐标Y速度";
CM_ SG_ 320 CDCS3_TouchEvtTyp "触屏类型";
CM_ SG_ 442 CDCS10_WorK_status "CDCS工作状态";
CM_ SG_ 443 CDCS13_SwSmMode "CDCS周期性通知DDCU、PDCU和ADAS当前多功能方向盘控制功能所处的控制模式（默认模式/ARHUD模式/侧后视镜模式）";
CM_ SG_ 468 CDCS5_ResetAllSetup "重置设置的信号";
CM_ SG_ 468 CDCS5_FactoryReset "恢复出厂的信号";
CM_ SG_ 501 CDCS11_LKSSetspeed "速度设定反馈";
CM_ SG_ 501 CDCS11_LDW_OnOffSet "LKS开启/关闭设置";
CM_ SG_ 501 CDCS11_LowSpeedBSDSw "低速BSD功能开关";
CM_ SG_ 501 CDCS11_FCW_OnOffSet "FCW开启/关闭控制开关";
CM_ SG_ 501 CDCS11_AEB_OnOffSet "AEB开启/关闭控制开关";
CM_ SG_ 501 CDCS11_FCW_WarnTiming "FCW灵敏度设置";
CM_ SG_ 501 CDCS11_FCTA_OnOffSet "FCTA开启/关闭设置";
CM_ SG_ 501 CDCS11_RCTA_OnOffSet "RCTA开启/关闭设置";
CM_ SG_ 501 CDCS11_RCW_OnOffSet "RCW开启/关闭设置";
CM_ SG_ 501 CDCS11_DOW_OnOffSet "DOW开启/关闭设置";
CM_ SG_ 501 CDCS11_IHBC_SysSwState "IHBC mode switch request by driver
智能远光灯功能设置开关";
CM_ SG_ 501 CDCS11_LCA_OnOffSet "LCA开启/关闭设置";
CM_ SG_ 501 CDCS11_TSR_OnOffSet "TSR开启/关闭设置";
CM_ SG_ 501 CDCS11_AVM_3DRotate "3D旋转动画";
CM_ SG_ 501 CDCS11_AVM_Turnlightstart "转向灯开启全景";
CM_ SG_ 501 CDCS11_AVM_Steeringstart "转向角开启全景";
CM_ SG_ 501 CDCS11_AVM_Magnifiedview "自动放大视角开关";
CM_ SG_ 501 CDCS11_AVM_MODdetection "移动物体检测";
CM_ SG_ 501 CDCS11_GM_OnOffSet "哨兵模式开启/关闭设置";
CM_ SG_ 501 CDCS11_NNP_OnOffSet "NNP开启/关闭设置";
CM_ SG_ 501 CDCS11_DCLCSysState "DCLC开启/关闭设置";
CM_ SG_ 501 CDCS11_ALCSysState "ALC开启/关闭设置";
CM_ SG_ 501 CDCS11_DriveOffPossilbeswitch "前车起步提请状态";
CM_ SG_ 501 CDCS11_DriveOffinhibitionswitch "前车起步抑制";
CM_ SG_ 501 CDCS11_ADAS_SndCtrlOnOff "ADAS唤醒语音开关状态";
CM_ SG_ 501 CDCS11_AVM_auxiliaryline "辅助线";
CM_ SG_ 501 CDCS11_AVM_Raderdisplay "雷达显示";
CM_ SG_ 501 CDCS11_AVM_Transparentchassis "透明底盘";
CM_ SG_ 501 CDCS11_VoiceMode "语音播报模式";
CM_ SG_ 501 CDCS11_NNP_Active_OnOffSet "NNP快捷开关";
CM_ SG_ 501 CDCS11_ALC_mode "NNP_ALC自动变道设置";
CM_ SG_ 501 CDCS11_ADSDriving_mode "NNP_自动驾驶风格选项设置";
CM_ SG_ 501 CDCS11_TSR_OverspeedOnoffSet "超速报警开关";
CM_ SG_ 501 CDCS11_NNP_AutoOnOffSet "NNP快捷开关_开启关闭";
CM_ SG_ 501 CDCS11_SnCtrl_NNP_OnOff "NNP语音开启关闭控制";
CM_ SG_ 501 CDCS11_GM_VidedIn "哨兵模式";
CM_ SG_ 501 CDCS11_TSR_SLFOnOffSet "智能限速_开关";
CM_ SG_ 501 CDCS11_APA_FunctionMode "泊车功能模式";
CM_ SG_ 501 CDCS11_TrackreverseSW "循迹倒车开关";
CM_ SG_ 501 CDCS11_SetPathwaySW "路线管理开关";
CM_ SG_ 501 CDCS11_PA_changeLanguage "语言切换";
CM_ SG_ 501 CDCS11_LDP_OnOffSet "LDP开关设置";
CM_ SG_ 501 CDCS11_AVMSw "AVM软开关";
CM_ SG_ 501 CDCS11_tryHPP "记忆泊车试一试按键";
CM_ SG_ 501 CDCS11_RPASw "RPA软开关";
CM_ SG_ 501 CDCS11_SetSw "设置项开启";
CM_ SG_ 501 CDCS11_SoundCtrlSetReq "语音控制使能开关";
CM_ SG_ 501 CDCS11_location_sw "IHU发出APA定位开启信号";
CM_ SG_ 501 CDCS11_Pathrefresh "更新路线开关";
CM_ SG_ 501 CDCS11_HPAGuideSW "开关，用户选择是否尝试记忆泊车学习";
CM_ SG_ 501 CDCS11_HPAPathwaytoCloudSW "记忆泊车路线学习完成，是否上传开关";
CM_ SG_ 501 CDCS11_PathlearningSw "记忆泊车路线学习开关";
CM_ SG_ 501 CDCS11_PA_screenMd "大屏收到泊车系统状态";
CM_ SG_ 501 CDCS11_PASw "APA软开关";
CM_ SG_ 501 CDCS11_PA_Recover "IHU发出恢复泊车指令";
CM_ SG_ 501 CDCS_Lcsndrequest "语音变道";
CM_ SG_ 501 CDCS_Lcsndconfirm "主动变道驾驶员确认";
CM_ SG_ 501 CDCS_SpdAdaptComfirm "速度匹配确认信号";
CM_ SG_ 501 CDCS_PayModeConfirm "收费站匹配确认信号";
CM_ SG_ 501 CDCS11_SelectSlotID "车位选择信息";
CM_ SG_ 501 CDCS11_ParkingInReq "开始泊入开关";
CM_ SG_ 501 CDCS11_ParkingOutReq "开始泊出开关";
CM_ SG_ 501 CDCS11_AVM_ViewMode "视图显示模式";
CM_ SG_ 501 CDCS11_RPA_FunctionMode "遥控泊车功能模式";
CM_ SG_ 501 CDCS11_AVM_VideoOutputFail "视频输出信号";
CM_ SG_ 501 CDCS11_AVM_Initialization "初始化设置";
CM_ SG_ 501 CDCS11_AVM_bodySync "车身信息同步开关";
CM_ SG_ 501 CDCS11_AVM_licenseplateabbr "车牌照省会简称";
CM_ SG_ 501 CDCS11_AVM_SpeView "特殊视角";
CM_ SG_ 501 CDCS11_AVM_licenseplateArea "省内区域";
CM_ SG_ 501 CDCS11_AVM_StartMode "AVM启动模式设置";
CM_ SG_ 501 CDCS11_AVM_LicensePlateNO1 "车牌照第1位数字";
CM_ SG_ 501 CDCS11_ELK_OnOffSet "ELK开关设置";
CM_ SG_ 501 CDCS11_AVM_LicensePlateNO2 "车牌照第2位数字";
CM_ SG_ 501 CDCS11_DrvOffAlertSwitch "起步提醒开关";
CM_ SG_ 501 CDCS11_AVM_LicensePlateNO3 "车牌照第3位数字";
CM_ SG_ 501 CDCS11_DCWposition "开门预警设置";
CM_ SG_ 501 CDCS11_AVM_LicensePlateNO4 "车牌照第4位数字";
CM_ SG_ 501 CDCS11_AVM_LicensePlateNO5 "车牌照第5位数字";
CM_ SG_ 501 CDCS11_AVM_LicensePlateNO6 "车牌照第6位数字";
CM_ SG_ 501 CDCS11_DataUp_Trigger "数据上云请求";
CM_ SG_ 501 CDCS11_AVM_LicensePlateNO7 "车牌照第7位数字";
CM_ SG_ 501 CDCS11_AVM_LicensePlateNO8 "车牌照第8位数字";
CM_ SG_ 501 CDCS11_AVM_Powertype "车辆动力类型";
CM_ SG_ 501 CDCS11_AVM_Diaphaneity "透明度";
CM_ SG_ 501 CDCS11_AVM_DiaphaneitySw "透明度功能开关";
CM_ SG_ 501 CDCS11_LDWLKAAidSwSts "ELKS（LDW+LKA）
紧急车道保持系统(FLC-ME平台专用)";
CM_ SG_ 501 CDCS11_MOD_Sound_Sw "MOD报警设置开关";
CM_ SG_ 501 CDCS11_MOD_BSD_Sw "低速BSD功能";
CM_ SG_ 501 CDCS11_PA_FRS_OnOffSet "前雷达开关";
CM_ SG_ 501 CDCS11_PA_3D_OnOffSet "超声波雷达立体显示开关";
CM_ SG_ 501 CDCS11_PA_measure_OnOffSet "超声波雷达测距显示开关";
CM_ SG_ 501 CDCS11_MODSw "MOD低速动态物体识别设置开关";
CM_ SG_ 501 CDCS11_VoiceNotifFrequency_mode "导航播报模式";
CM_ SG_ 501 CDCS11_ACCOnOffSet "巡航开关信号";
CM_ SG_ 501 CDCS11_HPASw "开启记忆泊车开关";
CM_ SG_ 501 CDCS11_DeleteMapID "删除地图ID";
CM_ SG_ 501 CDCS11_UploadMapID "上传地图ID";
CM_ SG_ 501 CDCS11_HPAActiveConfirm "确认注意事项";
CM_ SG_ 501 CDCS11_HPApreparkingSw "记忆泊车快捷开关";
CM_ SG_ 501 CDCS11_HPAPathwaytoCloud_WorkSts "路线上传开关状态";
CM_ SG_ 501 CDCS11_HPA_ONPath_ID1 "CDCS反馈选中记忆泊车路线ID1信号";
CM_ SG_ 501 CDCS11_HPA_ONPath_ID2 "CDCS反馈选中记忆泊车路线ID2信号";
CM_ SG_ 501 CDCS11_HPA_ONPath_ID3 "CDCS反馈选中记忆泊车路线ID3信号";
CM_ SG_ 501 CDCS11_HPA_ONPath_ID4 "CDCS反馈选中记忆泊车路线ID4信号";
CM_ SG_ 501 CDCS11_HPA_Select_ID "选择HPA路线ID";
CM_ SG_ 501 CDCS11_PA_Select_ID "CDCS发送车端选择车位信息";
CM_ SG_ 501 CDCS11_learnpath_St "记忆泊车路线学习后用户操作状态";
CM_ SG_ 501 CDCS11_LKAActvReq "车道偏离辅助设置";
CM_ SG_ 501 CDCS11_TSR_LimitOverspeedSet "交通标志识别（TSR）增加用户可设置限定的超速值，进行超速报警提醒";
CM_ SG_ 501 CDCS11_ParkingoutSlot_Type "自选车位类型";
CM_ SG_ 501 CDCS11_ParkingoutSlot_Dire "自选车位方向";
CM_ SG_ 501 CDCS11_OptionalSlot_Type "自选车位类型";
CM_ SG_ 501 CDCS11_OptionalSlot_Dire "自选车位方向";
CM_ SG_ 501 CDCS11_OptionalSlotAngle "自选车位角度";
CM_ SG_ 501 CDCS11_OptionalSlotCoor_P0_X "自选车位功能四角坐标信息";
CM_ SG_ 501 CDCS11_OptionalSlotCoor_P0_Y "自选车位功能四角坐标信息";
CM_ SG_ 501 CDCS11_OptionalSlotCoor_P1_X "自选车位功能四角坐标信息";
CM_ SG_ 501 CDCS11_OptionalSlotCoor_P1_Y "自选车位功能四角坐标信息";
CM_ SG_ 501 CDCS11_OptionalSlotCoor_P2_X "自选车位功能四角坐标信息";
CM_ SG_ 501 CDCS11_OptionalSlotCoor_P2_Y "自选车位功能四角坐标信息";
CM_ SG_ 501 CDCS11_OptionalSlotCoor_P3_X "自选车位功能四角坐标信息";
CM_ SG_ 501 CDCS11_OptionalSlotCoor_P3_Y "自选车位功能四角坐标信息";
CM_ SG_ 515 CDCS15_NNP_DriverStatus "驾驶员状态信号（DMS）";
CM_ SG_ 515 CDCS15_Storage_St "CDCS内部空间信号，用于哨兵模式状态机监控";
CM_ SG_ 515 CDCS15_USB_St "CDCS USB不可用信号，用于哨兵模式状态机监控";
CM_ SG_ 515 CDCS15_UserSceneMode "情景模式信号";
CM_ SG_ 515 CDCS15_NNP_DriverFatigueStatus "DMS检测驾驶员疲劳状态传输给ADCS，用于NNP判断";
CM_ SG_ 515 CDCS15_NNP_DriverDistractedStatus "DMS检测驾驶员分心状态传输给ADCS，用于NNP判断";
CM_ SG_ 805 ICU2_Odometer "仪表显示总计里程";
CM_ SG_ 305 ICU1_VehicleSpdDisplayValid "仪表显示车速有效性";
CM_ SG_ 305 ICU1_VehicleSpdDisplay "仪表显示车速";
CM_ SG_ 992 CalendarYear "Calendar Year";
CM_ SG_ 992 CalendarMonth "Calendar Month";
CM_ SG_ 992 CalendarDay "Calendar Day";
CM_ SG_ 992 HourOfDay "Hour Of Day";
CM_ SG_ 992 MinuteOfHour "Minute Of Hour";
CM_ SG_ 992 SecsOfMinute "Seconds Of Minute";
CM_ SG_ 992 TimeDspFmt "Time Display Format";

BA_DEF_ SG_ "GenSigInvalidValue" HEX 0 0;
BA_DEF_ SG_ "GenSigStartValue" HEX 0 0;
BA_DEF_ SG_ "GenSigSendType" ENUM "Cycle","OnWrite","OnWriteWithRepetition","OnChange","OnChangeWithRepetition","IfActive","IfActiveWithRepetition","NoSigSendType","vector_leerstring";
BA_DEF_ BO_ "CANFD_BRS" ENUM "0","1";
BA_DEF_ BO_ "GenMsgSendType" ENUM "Cycle","NoMsgSendType","IfActive","Event","CA","CE";
BA_DEF_ BO_ "GenMsgNrOfRepetition" INT 0 0;
BA_DEF_ BO_ "GenMsgILSupport" ENUM "No","Yes";
BA_DEF_ BO_ "GenMsgDelayTime" INT 0 0;
BA_DEF_ BO_ "GenMsgCycleTimeFast" INT 0 0;
BA_DEF_ BO_ "GenMsgCycleTime" INT 0 0;
BA_DEF_ BO_ "NmMessage" ENUM "No","Yes";
BA_DEF_ BO_ "VFrameFormat" ENUM "StandardCAN","ExtendedCAN","reserved","J1939PG","reserved","reserved","reserved","reserved","reserved","reserved","reserved","reserved","reserved","reserved","StandardCAN_FD","ExtendedCAN_FD";
BA_DEF_ BU_ "NodeLayerModules" STRING ;
BA_DEF_ BU_ "NmCAN" INT 1 2;
BA_DEF_ BU_ "ILUsed" ENUM "No","Yes";
BA_DEF_ "NmType" STRING ;
BA_DEF_ "ProtocolType" STRING ;
BA_DEF_ "NmBaseAddress" HEX 0 2047;
BA_DEF_ "DBName" STRING ;
BA_DEF_ "BusType" STRING ;
BA_DEF_ "Baudrate" INT 0 1000000;
BA_DEF_DEF_ "GenSigInvalidValue" 0;
BA_DEF_DEF_ "GenSigStartValue" 0;
BA_DEF_DEF_ "GenSigSendType" "Cycle";
BA_DEF_DEF_ "CANFD_BRS" "1";
BA_DEF_DEF_ "GenMsgSendType" "Cycle";
BA_DEF_DEF_ "GenMsgNrOfRepetition" 0;
BA_DEF_DEF_ "GenMsgILSupport" "Yes";
BA_DEF_DEF_ "GenMsgDelayTime" 0;
BA_DEF_DEF_ "GenMsgCycleTimeFast" 0;
BA_DEF_DEF_ "GenMsgCycleTime" 0;
BA_DEF_DEF_ "NmMessage" "No";
BA_DEF_DEF_ "VFrameFormat" "StandardCAN";
BA_DEF_DEF_ "NodeLayerModules" "OSEKNM01.dll,CANoeILNLVector.dll";
BA_DEF_DEF_ "NmCAN" 2;
BA_DEF_DEF_ "ILUsed" "Yes";
BA_DEF_DEF_ "NmType" "OSEK";
BA_DEF_DEF_ "ProtocolType" "CAN";
BA_DEF_DEF_ "NmBaseAddress" 1024;
BA_DEF_DEF_ "DBName" "";
BA_DEF_DEF_ "BusType" "CAN FD";
BA_DEF_DEF_ "Baudrate" 500000;
BA_ "DBName" "EP32(E01)_CANFD_Matrix_V5.0_FLC_FD3";
BA_ "ProtocolType" "CAN FD";
BA_ "GenMsgCycleTime" BO_ 579 100;
BA_ "VFrameFormat" BO_ 579 14;
BA_ "GenMsgCycleTime" BO_ 347 50;
BA_ "VFrameFormat" BO_ 347 14;
BA_ "GenMsgCycleTime" BO_ 227 20;
BA_ "VFrameFormat" BO_ 227 14;
BA_ "GenMsgCycleTime" BO_ 264 20;
BA_ "VFrameFormat" BO_ 264 14;
BA_ "GenMsgCycleTime" BO_ 600 100;
BA_ "VFrameFormat" BO_ 600 14;
BA_ "GenMsgCycleTime" BO_ 170 10;
BA_ "VFrameFormat" BO_ 170 14;
BA_ "GenMsgCycleTime" BO_ 192 10;
BA_ "VFrameFormat" BO_ 192 14;
BA_ "GenMsgCycleTime" BO_ 197 10;
BA_ "VFrameFormat" BO_ 197 14;
BA_ "GenMsgCycleTime" BO_ 199 10;
BA_ "VFrameFormat" BO_ 199 14;
BA_ "GenMsgCycleTime" BO_ 201 10;
BA_ "VFrameFormat" BO_ 201 14;
BA_ "GenMsgCycleTime" BO_ 229 10;
BA_ "VFrameFormat" BO_ 229 14;
BA_ "GenMsgCycleTime" BO_ 289 20;
BA_ "VFrameFormat" BO_ 289 14;
BA_ "GenMsgCycleTime" BO_ 297 20;
BA_ "VFrameFormat" BO_ 297 14;
BA_ "GenMsgCycleTime" BO_ 299 20;
BA_ "VFrameFormat" BO_ 299 14;
BA_ "GenMsgCycleTime" BO_ 301 20;
BA_ "VFrameFormat" BO_ 301 14;
BA_ "GenMsgCycleTime" BO_ 302 20;
BA_ "VFrameFormat" BO_ 302 14;
BA_ "GenMsgCycleTime" BO_ 177 10;
BA_ "VFrameFormat" BO_ 177 14;
BA_ "GenMsgCycleTime" BO_ 178 10;
BA_ "VFrameFormat" BO_ 178 14;
BA_ "GenMsgCycleTime" BO_ 142 10;
BA_ "VFrameFormat" BO_ 142 14;
BA_ "GenMsgCycleTime" BO_ 143 10;
BA_ "VFrameFormat" BO_ 143 14;
BA_ "GenMsgNrOfRepetition" BO_ 310 3;
BA_ "GenMsgCycleTimeFast" BO_ 310 20;
BA_ "GenMsgSendType" BO_ 310 3;
BA_ "VFrameFormat" BO_ 310 14;
BA_ "GenMsgCycleTime" BO_ 403 50;
BA_ "VFrameFormat" BO_ 403 14;
BA_ "GenMsgCycleTime" BO_ 404 50;
BA_ "VFrameFormat" BO_ 404 14;
BA_ "GenMsgCycleTime" BO_ 1556 500;
BA_ "NmMessage" BO_ 1556 1;
BA_ "GenMsgCycleTime" BO_ 196 10;
BA_ "VFrameFormat" BO_ 196 14;
BA_ "GenMsgCycleTime" BO_ 258 20;
BA_ "VFrameFormat" BO_ 258 14;
BA_ "GenMsgCycleTime" BO_ 272 20;
BA_ "VFrameFormat" BO_ 272 14;
BA_ "GenMsgCycleTime" BO_ 274 20;
BA_ "VFrameFormat" BO_ 274 14;
BA_ "GenMsgCycleTime" BO_ 276 20;
BA_ "VFrameFormat" BO_ 276 14;
BA_ "GenMsgCycleTime" BO_ 486 50;
BA_ "VFrameFormat" BO_ 486 14;
BA_ "GenMsgCycleTime" BO_ 645 100;
BA_ "VFrameFormat" BO_ 645 14;
BA_ "GenMsgCycleTime" BO_ 418 50;
BA_ "VFrameFormat" BO_ 418 14;
BA_ "GenMsgCycleTime" BO_ 419 50;
BA_ "VFrameFormat" BO_ 419 14;
BA_ "GenMsgNrOfRepetition" BO_ 320 3;
BA_ "GenMsgCycleTimeFast" BO_ 320 20;
BA_ "GenMsgSendType" BO_ 320 3;
BA_ "VFrameFormat" BO_ 320 14;
BA_ "GenMsgCycleTime" BO_ 442 50;
BA_ "VFrameFormat" BO_ 442 14;
BA_ "GenMsgCycleTime" BO_ 443 100;
BA_ "VFrameFormat" BO_ 443 14;
BA_ "GenMsgNrOfRepetition" BO_ 468 3;
BA_ "GenMsgCycleTimeFast" BO_ 468 20;
BA_ "GenMsgSendType" BO_ 468 3;
BA_ "VFrameFormat" BO_ 468 14;
BA_ "GenMsgNrOfRepetition" BO_ 501 3;
BA_ "GenMsgCycleTimeFast" BO_ 501 20;
BA_ "GenMsgSendType" BO_ 501 3;
BA_ "VFrameFormat" BO_ 501 14;
BA_ "GenMsgCycleTime" BO_ 515 50;
BA_ "VFrameFormat" BO_ 515 14;
BA_ "GenMsgCycleTime" BO_ 805 500;
BA_ "VFrameFormat" BO_ 805 14;
BA_ "GenMsgCycleTime" BO_ 305 20;
BA_ "VFrameFormat" BO_ 305 14;
BA_ "GenMsgCycleTime" BO_ 992 1000;
BA_ "VFrameFormat" BO_ 992 14;
BA_ "GenSigStartValue" SG_ 264 VCU4_PA_TargetTrqValue 800;
BA_ "GenSigStartValue" SG_ 170 MCU1_CurrentTorque 8000;
BA_ "GenSigInvalidValue" SG_ 192 IDB2_FLWhlPulCnt 65535;
BA_ "GenSigInvalidValue" SG_ 192 IDB2_FRWhlPulCnt 65535;
BA_ "GenSigInvalidValue" SG_ 197 IDB3_MasterCylPressure 65535;
BA_ "GenSigStartValue" SG_ 197 IDB3_MasterCylPressure 3000;
BA_ "GenSigInvalidValue" SG_ 199 IDB4_FLWhlVelocity 16383;
BA_ "GenSigInvalidValue" SG_ 199 IDB4_FRWhlVelocity 16383;
BA_ "GenSigInvalidValue" SG_ 199 IDB4_RLWhlVelocity 16383;
BA_ "GenSigInvalidValue" SG_ 199 IDB4_RRWhlVelocity 16383;
BA_ "GenSigInvalidValue" SG_ 199 IDB4_RLWhlPulCnt 65535;
BA_ "GenSigInvalidValue" SG_ 199 IDB4_RRWhlPulCnt 65535;
BA_ "GenSigStartValue" SG_ 201 IDB10_ADAS_DrvTorque 32000;
BA_ "GenSigStartValue" SG_ 201 IDB10_ADAS_RegenTorque 32000;
BA_ "GenSigStartValue" SG_ 229 IDB1_BrakPedalDisp 400;
BA_ "GenSigStartValue" SG_ 229 IDB1_Brakestyle_Enabled 1;
BA_ "GenSigStartValue" SG_ 297 IDB5_ACC_ReferenceAccel 1023;
BA_ "GenSigInvalidValue" SG_ 177 EPS1_TorsionBarTorque 2047;
BA_ "GenSigInvalidValue" SG_ 177 EPS1_SteeringAngle 65535;
BA_ "GenSigInvalidValue" SG_ 177 EPS1_SteerAngleSpd 16383;
BA_ "GenSigInvalidValue" SG_ 178 EPS2_MotCntrl 2047;
BA_ "GenSigStartValue" SG_ 142 ADCS2_ADAS_EPSAngleReq 7200;
BA_ "GenSigStartValue" SG_ 142 ADCS2_AEBTargetDeceleration 127;
BA_ "GenSigSendType" SG_ 310 ADCS12_FCWWarnAudioplay 4;
BA_ "GenSigSendType" SG_ 310 ADCS12_RCTAWarnAudioplay 4;
BA_ "GenSigSendType" SG_ 310 ADCS12_FCTAWarnAudioplay 4;
BA_ "GenSigSendType" SG_ 310 ADCS12_SpeedWarnAudioplay 4;
BA_ "GenSigSendType" SG_ 310 ADCS12_DOWWarnAudioplay 4;
BA_ "GenSigSendType" SG_ 310 ADCS12_DCLCAudioplay 4;
BA_ "GenSigSendType" SG_ 310 ADCS12_PilotAudioPlay 4;
BA_ "GenSigSendType" SG_ 310 ADCS12_HandOffAudioplay 4;
BA_ "GenSigSendType" SG_ 310 ADCS12_NNPCancelAudioPlay 4;
BA_ "GenSigSendType" SG_ 310 ADCS12_RCWWarnAudioplay 4;
BA_ "GenSigSendType" SG_ 310 ADCS12_MRMAudioPlay 4;
BA_ "GenSigSendType" SG_ 310 ADCS12_NNP_ResumeAudioplay 4;
BA_ "GenSigSendType" SG_ 310 ADCS12_Lcsndrequest 4;
BA_ "GenSigSendType" SG_ 310 ADCS12_Lcsndrconfirm 4;
BA_ "GenSigSendType" SG_ 310 ADCS12_DriveOffBroadcast 4;
BA_ "GenSigSendType" SG_ 310 ADCS12_EyeOffBroadcast 4;
BA_ "GenSigSendType" SG_ 310 ADCS12_longitudDisableInfo 4;
BA_ "GenSigSendType" SG_ 310 ADCS12_SpeedAdaptComfirm 4;
BA_ "GenSigSendType" SG_ 310 ADCS12_PayModeConfirm 4;
BA_ "GenSigSendType" SG_ 310 ADCS12_longitudCtrlSysInfo 4;
BA_ "GenSigSendType" SG_ 310 ADCS12_ADAS_DriveOffinhibition 4;
BA_ "GenSigSendType" SG_ 310 ADCS12_P2N_State_Reminder 4;
BA_ "GenSigSendType" SG_ 310 ADCS12_NNP_State_Reminder 4;
BA_ "GenSigSendType" SG_ 310 ADCS12_NNP_LightRemind 4;
BA_ "GenSigSendType" SG_ 310 ADCS12_LaneChangePendingAlert 4;
BA_ "GenSigStartValue" SG_ 310 ADCS12_NPilotSysInfo 31;
BA_ "GenSigSendType" SG_ 310 ADCS12_NPilotSysInfo 4;
BA_ "GenSigSendType" SG_ 310 ADCS12_LCAudioPlay 4;
BA_ "GenSigSendType" SG_ 310 ADCS12_NNP_Scenarios_AudioPlay 4;
BA_ "GenSigSendType" SG_ 310 ADCS12_NNP_RINO 4;
BA_ "GenSigStartValue" SG_ 403 ADCS8_LKSSetspeed 55;
BA_ "GenSigStartValue" SG_ 403 ADCS8_ACCState 1;
BA_ "GenSigStartValue" SG_ 403 ADCS8_longitudCtrlSetSpeed 30;
BA_ "GenSigStartValue" SG_ 403 ADCS8_longitudCtrlSetDistance 3;
BA_ "GenSigStartValue" SG_ 403 ADCS8_AEB_SystemStatus 1;
BA_ "GenSigStartValue" SG_ 403 ADCS8_FCTA_State 2;
BA_ "GenSigStartValue" SG_ 403 ADCS8_CDCS_CertificateState2 1;
BA_ "GenSigStartValue" SG_ 403 ADCS8_RCTA_State 2;
BA_ "GenSigStartValue" SG_ 403 ADCS8_DOW_State 2;
BA_ "GenSigStartValue" SG_ 403 ADCS8_RCW_State 2;
BA_ "GenSigStartValue" SG_ 403 ADCS8_LCAState 2;
BA_ "GenSigStartValue" SG_ 403 ADCS8_TSRState 2;
BA_ "GenSigStartValue" SG_ 403 ADCS8_DrvOffAlertSwitch 1;
BA_ "GenSigStartValue" SG_ 403 ADCS8_TSR_OverspeedOnOffSet 1;
BA_ "GenSigStartValue" SG_ 403 ADCS8_ADSDriving_mode 1;
BA_ "GenSigStartValue" SG_ 403 ADCS8_NpilotOverride_State 1;
BA_ "GenSigStartValue" SG_ 403 ADCS8_TSR_LimitOverspeedSet 255;
BA_ "GenSigInvalidValue" SG_ 404 ADCS8_PA_FPAS_SnsrDist_FLC 255;
BA_ "GenSigInvalidValue" SG_ 404 ADCS8_PA_FPAS_SnsrDist_FLM 255;
BA_ "GenSigInvalidValue" SG_ 404 ADCS8_PA_FPAS_SnsrDist_FRM 255;
BA_ "GenSigInvalidValue" SG_ 404 ADCS8_PA_FPAS_SnsrDist_FRC 255;
BA_ "GenSigInvalidValue" SG_ 404 ADCS8_PA_FPAS_SnsrDist_RLC 255;
BA_ "GenSigInvalidValue" SG_ 404 ADCS8_PA_FPAS_SnsrDist_RLM 255;
BA_ "GenSigInvalidValue" SG_ 404 ADCS8_PA_FPAS_SnsrDist_RRM 255;
BA_ "GenSigInvalidValue" SG_ 404 ADCS8_PA_FPAS_SnsrDist_RRC 255;
BA_ "GenSigInvalidValue" SG_ 404 ADCS8_PA_FPAS_SnsrDist_SFL 511;
BA_ "GenSigInvalidValue" SG_ 404 ADCS8_PA_FPAS_SnsrDist_SFR 511;
BA_ "GenSigInvalidValue" SG_ 404 ADCS8_PA_FPAS_SnsrDist_SRL 511;
BA_ "GenSigInvalidValue" SG_ 404 ADCS8_PA_FPAS_SnsrDist_SRR 511;
BA_ "GenSigStartValue" SG_ 404 ADCS8_PA_RPAS_WorkSts 1;
BA_ "GenSigStartValue" SG_ 404 ADCS8_PA_FPAS_WorkSts 1;
BA_ "GenSigInvalidValue" SG_ 196 ACU2_LatAccSensorValue 2047;
BA_ "GenSigInvalidValue" SG_ 196 ACU2_LongAccSensorValue 2047;
BA_ "GenSigInvalidValue" SG_ 196 ACU2_VehicleDynYawRate 8191;
BA_ "GenSigStartValue" SG_ 276 CS1_GearPositionReqStInv 7;
BA_ "GenSigInvalidValue" SG_ 418 DDCU1_FL_WinPos 255;
BA_ "GenSigInvalidValue" SG_ 418 DDCU1_RL_WinPos 255;
BA_ "GenSigInvalidValue" SG_ 419 PDCU1_FR_WinPos 255;
BA_ "GenSigInvalidValue" SG_ 419 PDCU1_RR_WinPos 255;
BA_ "GenSigSendType" SG_ 320 CDCS3_ESCOffSw 2;
BA_ "GenSigSendType" SG_ 320 CDCS3_HDCSw 2;
BA_ "GenSigSendType" SG_ 320 CDCS3_DriveModeSet 2;
BA_ "GenSigStartValue" SG_ 320 CDCS3_Xcoordinate 65535;
BA_ "GenSigSendType" SG_ 320 CDCS3_Xcoordinate 2;
BA_ "GenSigStartValue" SG_ 320 CDCS3_Ycoordinate 65535;
BA_ "GenSigSendType" SG_ 320 CDCS3_Ycoordinate 2;
BA_ "GenSigStartValue" SG_ 320 CDCS3_XGestureSpd 255;
BA_ "GenSigSendType" SG_ 320 CDCS3_XGestureSpd 2;
BA_ "GenSigStartValue" SG_ 320 CDCS3_YGestureSpd 255;
BA_ "GenSigSendType" SG_ 320 CDCS3_YGestureSpd 2;
BA_ "GenSigSendType" SG_ 320 CDCS3_TouchEvtTyp 2;
BA_ "GenSigSendType" SG_ 468 CDCS5_ResetAllSetup 2;
BA_ "GenSigSendType" SG_ 468 CDCS5_FactoryReset 2;
BA_ "GenSigSendType" SG_ 501 CDCS11_LKSSetspeed 2;
BA_ "GenSigSendType" SG_ 501 CDCS11_LDW_OnOffSet 2;
BA_ "GenSigSendType" SG_ 501 CDCS11_LowSpeedBSDSw 2;
BA_ "GenSigSendType" SG_ 501 CDCS11_FCW_OnOffSet 2;
BA_ "GenSigSendType" SG_ 501 CDCS11_AEB_OnOffSet 2;
BA_ "GenSigSendType" SG_ 501 CDCS11_FCW_WarnTiming 2;
BA_ "GenSigSendType" SG_ 501 CDCS11_FCTA_OnOffSet 2;
BA_ "GenSigSendType" SG_ 501 CDCS11_RCTA_OnOffSet 2;
BA_ "GenSigSendType" SG_ 501 CDCS11_RCW_OnOffSet 2;
BA_ "GenSigSendType" SG_ 501 CDCS11_DOW_OnOffSet 2;
BA_ "GenSigSendType" SG_ 501 CDCS11_IHBC_SysSwState 2;
BA_ "GenSigSendType" SG_ 501 CDCS11_LCA_OnOffSet 2;
BA_ "GenSigSendType" SG_ 501 CDCS11_TSR_OnOffSet 2;
BA_ "GenSigSendType" SG_ 501 CDCS11_AVM_3DRotate 2;
BA_ "GenSigSendType" SG_ 501 CDCS11_AVM_Turnlightstart 2;
BA_ "GenSigSendType" SG_ 501 CDCS11_AVM_Steeringstart 2;
BA_ "GenSigSendType" SG_ 501 CDCS11_AVM_Magnifiedview 2;
BA_ "GenSigSendType" SG_ 501 CDCS11_AVM_MODdetection 2;
BA_ "GenSigSendType" SG_ 501 CDCS11_GM_OnOffSet 2;
BA_ "GenSigSendType" SG_ 501 CDCS11_NNP_OnOffSet 2;
BA_ "GenSigSendType" SG_ 501 CDCS11_DCLCSysState 2;
BA_ "GenSigSendType" SG_ 501 CDCS11_ALCSysState 2;
BA_ "GenSigSendType" SG_ 501 CDCS11_DriveOffPossilbeswitch 2;
BA_ "GenSigSendType" SG_ 501 CDCS11_DriveOffinhibitionswitch 2;
BA_ "GenSigSendType" SG_ 501 CDCS11_ADAS_SndCtrlOnOff 2;
BA_ "GenSigSendType" SG_ 501 CDCS11_AVM_auxiliaryline 2;
BA_ "GenSigSendType" SG_ 501 CDCS11_AVM_Raderdisplay 2;
BA_ "GenSigSendType" SG_ 501 CDCS11_AVM_Transparentchassis 2;
BA_ "GenSigSendType" SG_ 501 CDCS11_VoiceMode 2;
BA_ "GenSigSendType" SG_ 501 CDCS11_NNP_Active_OnOffSet 2;
BA_ "GenSigSendType" SG_ 501 CDCS11_ALC_mode 2;
BA_ "GenSigSendType" SG_ 501 CDCS11_ADSDriving_mode 2;
BA_ "GenSigSendType" SG_ 501 CDCS11_TSR_OverspeedOnoffSet 2;
BA_ "GenSigSendType" SG_ 501 CDCS11_NNP_AutoOnOffSet 2;
BA_ "GenSigSendType" SG_ 501 CDCS11_SnCtrl_NNP_OnOff 2;
BA_ "GenSigSendType" SG_ 501 CDCS11_GM_VidedIn 2;
BA_ "GenSigSendType" SG_ 501 CDCS11_TSR_SLFOnOffSet 2;
BA_ "GenSigSendType" SG_ 501 CDCS11_APA_FunctionMode 2;
BA_ "GenSigSendType" SG_ 501 CDCS11_TrackreverseSW 2;
BA_ "GenSigSendType" SG_ 501 CDCS11_SetPathwaySW 2;
BA_ "GenSigSendType" SG_ 501 CDCS11_PA_changeLanguage 2;
BA_ "GenSigSendType" SG_ 501 CDCS11_LDP_OnOffSet 2;
BA_ "GenSigSendType" SG_ 501 CDCS11_AVMSw 2;
BA_ "GenSigSendType" SG_ 501 CDCS11_tryHPP 2;
BA_ "GenSigSendType" SG_ 501 CDCS11_RPASw 2;
BA_ "GenSigSendType" SG_ 501 CDCS11_SetSw 2;
BA_ "GenSigSendType" SG_ 501 CDCS11_SoundCtrlSetReq 2;
BA_ "GenSigSendType" SG_ 501 CDCS11_location_sw 2;
BA_ "GenSigSendType" SG_ 501 CDCS11_Pathrefresh 2;
BA_ "GenSigSendType" SG_ 501 CDCS11_HPAGuideSW 2;
BA_ "GenSigSendType" SG_ 501 CDCS11_HPAPathwaytoCloudSW 2;
BA_ "GenSigSendType" SG_ 501 CDCS11_PathlearningSw 2;
BA_ "GenSigSendType" SG_ 501 CDCS11_PA_screenMd 2;
BA_ "GenSigSendType" SG_ 501 CDCS11_PASw 2;
BA_ "GenSigSendType" SG_ 501 CDCS11_PA_Recover 2;
BA_ "GenSigSendType" SG_ 501 CDCS_Lcsndrequest 2;
BA_ "GenSigSendType" SG_ 501 CDCS_Lcsndconfirm 2;
BA_ "GenSigSendType" SG_ 501 CDCS_SpdAdaptComfirm 2;
BA_ "GenSigSendType" SG_ 501 CDCS_PayModeConfirm 2;
BA_ "GenSigSendType" SG_ 501 CDCS11_SelectSlotID 2;
BA_ "GenSigSendType" SG_ 501 CDCS11_ParkingInReq 2;
BA_ "GenSigSendType" SG_ 501 CDCS11_ParkingOutReq 2;
BA_ "GenSigSendType" SG_ 501 CDCS11_AVM_ViewMode 2;
BA_ "GenSigSendType" SG_ 501 CDCS11_RPA_FunctionMode 2;
BA_ "GenSigSendType" SG_ 501 CDCS11_AVM_VideoOutputFail 2;
BA_ "GenSigSendType" SG_ 501 CDCS11_AVM_Initialization 2;
BA_ "GenSigSendType" SG_ 501 CDCS11_AVM_bodySync 2;
BA_ "GenSigSendType" SG_ 501 CDCS11_AVM_licenseplateabbr 2;
BA_ "GenSigSendType" SG_ 501 CDCS11_AVM_SpeView 2;
BA_ "GenSigSendType" SG_ 501 CDCS11_AVM_licenseplateArea 2;
BA_ "GenSigSendType" SG_ 501 CDCS11_AVM_StartMode 2;
BA_ "GenSigSendType" SG_ 501 CDCS11_AVM_LicensePlateNO1 2;
BA_ "GenSigSendType" SG_ 501 CDCS11_ELK_OnOffSet 2;
BA_ "GenSigSendType" SG_ 501 CDCS11_AVM_LicensePlateNO2 2;
BA_ "GenSigSendType" SG_ 501 CDCS11_DrvOffAlertSwitch 2;
BA_ "GenSigSendType" SG_ 501 CDCS11_AVM_LicensePlateNO3 2;
BA_ "GenSigSendType" SG_ 501 CDCS11_DCWposition 2;
BA_ "GenSigSendType" SG_ 501 CDCS11_AVM_LicensePlateNO4 2;
BA_ "GenSigSendType" SG_ 501 CDCS11_AVM_LicensePlateNO5 2;
BA_ "GenSigSendType" SG_ 501 CDCS11_AVM_LicensePlateNO6 2;
BA_ "GenSigSendType" SG_ 501 CDCS11_DataUp_Trigger 2;
BA_ "GenSigSendType" SG_ 501 CDCS11_AVM_LicensePlateNO7 2;
BA_ "GenSigSendType" SG_ 501 CDCS11_AVM_LicensePlateNO8 2;
BA_ "GenSigSendType" SG_ 501 CDCS11_AVM_Powertype 2;
BA_ "GenSigSendType" SG_ 501 CDCS11_AVM_Diaphaneity 2;
BA_ "GenSigSendType" SG_ 501 CDCS11_AVM_DiaphaneitySw 2;
BA_ "GenSigSendType" SG_ 501 CDCS11_LDWLKAAidSwSts 2;
BA_ "GenSigSendType" SG_ 501 CDCS11_MOD_Sound_Sw 2;
BA_ "GenSigSendType" SG_ 501 CDCS11_MOD_BSD_Sw 2;
BA_ "GenSigSendType" SG_ 501 CDCS11_PA_FRS_OnOffSet 2;
BA_ "GenSigSendType" SG_ 501 CDCS11_PA_3D_OnOffSet 2;
BA_ "GenSigSendType" SG_ 501 CDCS11_PA_measure_OnOffSet 2;
BA_ "GenSigSendType" SG_ 501 CDCS11_MODSw 2;
BA_ "GenSigSendType" SG_ 501 CDCS11_VoiceNotifFrequency_mode 2;
BA_ "GenSigSendType" SG_ 501 CDCS11_ACCOnOffSet 2;
BA_ "GenSigSendType" SG_ 501 CDCS11_HPASw 2;
BA_ "GenSigSendType" SG_ 501 CDCS11_DeleteMapID 2;
BA_ "GenSigSendType" SG_ 501 CDCS11_UploadMapID 2;
BA_ "GenSigSendType" SG_ 501 CDCS11_HPAActiveConfirm 2;
BA_ "GenSigSendType" SG_ 501 CDCS11_HPApreparkingSw 2;
BA_ "GenSigSendType" SG_ 501 CDCS11_HPAPathwaytoCloud_WorkSts 2;
BA_ "GenSigSendType" SG_ 501 CDCS11_HPA_ONPath_ID1 2;
BA_ "GenSigSendType" SG_ 501 CDCS11_HPA_ONPath_ID2 2;
BA_ "GenSigSendType" SG_ 501 CDCS11_HPA_ONPath_ID3 2;
BA_ "GenSigSendType" SG_ 501 CDCS11_HPA_ONPath_ID4 2;
BA_ "GenSigSendType" SG_ 501 CDCS11_HPA_Select_ID 2;
BA_ "GenSigSendType" SG_ 501 CDCS11_PA_Select_ID 2;
BA_ "GenSigSendType" SG_ 501 CDCS11_learnpath_St 2;
BA_ "GenSigSendType" SG_ 501 CDCS11_LKAActvReq 2;
BA_ "GenSigStartValue" SG_ 501 CDCS11_TSR_LimitOverspeedSet 255;
BA_ "GenSigSendType" SG_ 501 CDCS11_TSR_LimitOverspeedSet 2;
BA_ "GenSigSendType" SG_ 501 CDCS11_ParkingoutSlot_Type 2;
BA_ "GenSigSendType" SG_ 501 CDCS11_ParkingoutSlot_Dire 2;
BA_ "GenSigSendType" SG_ 501 CDCS11_OptionalSlot_Type 2;
BA_ "GenSigSendType" SG_ 501 CDCS11_OptionalSlot_Dire 2;
BA_ "GenSigSendType" SG_ 501 CDCS11_OptionalSlotAngle 2;
BA_ "GenSigSendType" SG_ 501 CDCS11_OptionalSlotCoor_P0_X 2;
BA_ "GenSigSendType" SG_ 501 CDCS11_OptionalSlotCoor_P0_Y 2;
BA_ "GenSigSendType" SG_ 501 CDCS11_OptionalSlotCoor_P1_X 2;
BA_ "GenSigSendType" SG_ 501 CDCS11_OptionalSlotCoor_P1_Y 2;
BA_ "GenSigSendType" SG_ 501 CDCS11_OptionalSlotCoor_P2_X 2;
BA_ "GenSigSendType" SG_ 501 CDCS11_OptionalSlotCoor_P2_Y 2;
BA_ "GenSigSendType" SG_ 501 CDCS11_OptionalSlotCoor_P3_X 2;
BA_ "GenSigSendType" SG_ 501 CDCS11_OptionalSlotCoor_P3_Y 2;
VAL_ 579 AICS2_OTAMode 15 "Reserved" 14 "Reserved" 13 "Reserved" 12 "Reserved" 11 "Reserved" 10 "Reserved" 9 "Reserved" 8 "Reserved" 7 "Reserved" 6 "Reserved" 5 "Reserved" 4 "Reserved" 3 "in OTA mode" 2 "enter OTA mode request" 1 "quit OTA mode request" 0 "No request";
VAL_ 579 AICS2_StopChargeing 15 "Reserved" 14 "Reserved" 13 "Reserved" 12 "Reserved" 11 "Reserved" 10 "Reserved" 9 "Reserved" 8 "Reserved" 7 "Reserved" 6 "Reserved" 5 "Reserved" 4 "Reserved" 3 "Reserved" 2 "Reserved" 1 "shutdown chargeing" 0 "No request";
VAL_ 579 AICS2_BootRequestHVShut 1 "Request" 0 "No request";
VAL_ 347 SWSM_A_CruiseDistance_Add 1 "Press" 0 "No Press";
VAL_ 347 SWSM_A_CruiseDistance_Minus 1 "Press" 0 "No Press";
VAL_ 347 SWSM_A_CruiseSpeed_Add 2 "Fast Slider" 1 "Slowly Slider" 0 "No Action";
VAL_ 347 SWSM_A_CruiseSpeed_Minus 2 "Fast Slider" 1 "Slowly Slider" 0 "No Action";
VAL_ 347 SWSM_A_SpeechInputSw 2 "Long Press" 1 "Short Press" 0 "No Press";
VAL_ 347 Region_A_SwError 1 "Error" 0 "No Error";
VAL_ 347 SWSM_A_CD_Add_Overtime 1 "Stucked _>60s" 0 "No Stuck";
VAL_ 347 SWSM_A_CD_Minus_Overtime 1 "Stucked _>60s" 0 "No Stuck";
VAL_ 227 VCU5_ActGear 7 "Invalid" 5 "S" 4 "Drive" 3 "Neutral" 2 "Reverse" 1 "Park" 0 "Default";
VAL_ 227 VCU5_ActGearValid 1 "Valid" 0 "Invalid";
VAL_ 227 VCU5_READYLightSts 1 "Lamp ON" 0 "Lamp OFF";
VAL_ 227 VCU5_PwrTrainFailureLevel 3 "Failure Stop" 2 "Failure Limit" 1 "Failure Slight" 0 "No Failure";
VAL_ 227 VCU5_HVReady 1 "Ready" 0 "Not Ready";
VAL_ 227 VCU5_EmuEngineSts 1 "Engine Running" 0 "Engine Stop";
VAL_ 227 VCU5_AccelPositionValid 1 "Valid" 0 "Invalid";
VAL_ 227 VCU5_DriveMode_fb 4 "LAUNCH" 3 "CONFORM" 2 "SPORT" 1 "ECO" 0 "Default";
VAL_ 227 VCU5_DriverOvertakeMode 1 "Active" 0 "Not Active";
VAL_ 264 VCU14_PAAvailable 1 "Not Available" 0 "Available";
VAL_ 264 VCU14_ACC_Ready 1 "Ready" 0 "Not ready";
VAL_ 264 VCU14_PAActive 1 "active" 0 "not active";
VAL_ 264 VCU14_PA_ParkingFnMd 5 "abort" 4 "suspend" 3 "Cruising_HPP Pro_Mod" 2 "Cruising_HPP_Mode" 1 "Parking Mode" 0 "Function Not Active";
VAL_ 264 VCU14_PA_FailCode 5 "Reserved" 4 "vehicle block（车辆无法移动）" 3 "Can not change gear" 2 "Driver interfervene" 1 "Over speed" 0 "Normal";
VAL_ 264 VCU14_Gear_PAActive 1 "active" 0 "not active";
VAL_ 264 VCU14_Gear_PAAvailable 1 "Not Available" 0 "Available";
VAL_ 264 VCU14_Gear_ErrorSts_M01 1 "Error" 0 "No Error";
VAL_ 264 VCU4_PA_DeceltorSts 1 "Not support" 0 "Support";
VAL_ 264 VCU4_PA_TargetTrqValueValidity 1 "Valid" 0 "Invalid";
VAL_ 264 VCU14_Gear_PACtrlAbortFeedback 4 "vehicle block（车辆无法移动）" 3 "Can not change gear" 2 "Driver intervene" 1 "Over speed" 0 "Normal";
VAL_ 600 BMS3_Charge_State 8 "Charge Achieved" 7 "Chager Fault" 6 "Charge Stop" 5 "Heat preservation" 4 "Heating while charging" 3 "Heating" 2 "Fast Charging" 1 "Slow Charging" 0 "Normal";
VAL_ 170 MCU1_CurrentTorqueValid 1 "Invalid" 0 "Valid";
VAL_ 192 IDB2_FRWhlPulCntValid 1 "Valid(有效)" 0 "Invalid(无效)";
VAL_ 192 IDB2_FLWhlPulCntValid 1 "Valid(有效)" 0 "Invalid(无效)";
VAL_ 197 IDB3_VehicleSpdValid 1 "Valid(有效)" 0 "Invalid(无效)";
VAL_ 197 IDB3_MasterCylPressureInvalid 1 "Valid(有效)" 0 "Invalid(无效)";
VAL_ 199 IDB4_FLWhlVelocityValid 1 "Valid(有效)" 0 "Invalid(无效)";
VAL_ 199 IDB4_FRWhlVelocityValid 1 "Valid(有效)" 0 "Invalid(无效)";
VAL_ 199 IDB4_RRWhlDir 3 "Error identifier" 2 "Backward direction" 1 "Forward direction" 0 "Unknown or stanstill";
VAL_ 199 IDB4_RLWhlDir 3 "Error identifier" 2 "Backward direction" 1 "Forward direction" 0 "Unknown or stanstill";
VAL_ 199 IDB4_FRWhlDir 3 "Error identifier" 2 "Backward direction" 1 "Forward direction" 0 "Unknown or stanstill";
VAL_ 199 IDB4_FLWhlDir 3 "Error identifier" 2 "Backward direction" 1 "Forward direction" 0 "Unknown or stanstill";
VAL_ 199 IDB4_RRWhlVelocityValid 1 "Valid(有效)" 0 "Invalid(无效)";
VAL_ 199 IDB4_RLWhlVelocityValid 1 "Valid(有效)" 0 "Invalid(无效)";
VAL_ 199 IDB4_RLWhlPulCntValid 1 "Valid(有效)" 0 "Invalid(无效)";
VAL_ 199 IDB4_RRWhlPulCntValid 1 "Valid(有效)" 0 "Invalid(无效)";
VAL_ 201 IDB10_ADAS_DrvTorqueReq 1 "Request" 0 "No Request";
VAL_ 201 IDB10_ADAS_RegenTorqueReq 1 "Request" 0 "No Request";
VAL_ 229 IDB1_BrakePedalApplied 1 "press( 制动踏板被踩下)" 0 "no press(( 制动踏板未被踩下)";
VAL_ 229 IDB1_BrakePedalAppliedV 1 "Valid(有效)" 0 "Invalid(无效)";
VAL_ 229 IDB1_BrakPedalDisp_Q 1 "Valid(有效)" 0 "Invalid(无效)";
VAL_ 229 IDB1_CSTFail 1 "Fail" 0 "Not fail";
VAL_ 229 IDB1_CSTAtive 1 "Active" 0 "Not active";
VAL_ 229 IDB1_CSTEnabled 1 "Enabled" 0 "Disabled";
VAL_ 229 IDB1_Brakestyle_Enabled 1 "Enabled" 0 "Disabled";
VAL_ 229 IDB1_Brakestyle_Fail 1 "Fail" 0 "Not fail";
VAL_ 229 IDB1_FailedState 6 "fault level 6" 5 "fault level 5" 4 "fault level 4" 3 "fault level 3" 2 "fault level 2" 1 "fault level 1" 0 "no fault";
VAL_ 297 IDB5_BrakeDiscTempSts 1 "Temperature too high" 0 "Not high";
VAL_ 297 IDB5_VehicleStanstill 3 "reserved" 2 "invalid (short unavailability, max 3min)" 1 "standstill" 0 "not standstill";
VAL_ 297 IDB5_JerkActive 1 "available" 0 "Not available";
VAL_ 297 IDB5_Jerkfail 1 "fail" 0 "no fail";
VAL_ 297 IDB5_ADAS_PrefillSts 1 "active" 0 "not active";
VAL_ 297 IDB5_ACC_ReqLim 3 "Deceleration Limit" 2 "Reserved" 1 "Reserved" 0 "No request";
VAL_ 297 IDB5_DBSavailable 1 "Available" 0 "Not Available";
VAL_ 297 IDB5_Prefillavailable 1 "Available" 0 "Not Available";
VAL_ 297 IDB5_ABAactive 1 "Active" 0 "No Active";
VAL_ 297 IDB5_AEB_Enable 3 "AEB Communication Error" 2 "Permanently not Available" 1 "Temporarily not Available" 0 "Available";
VAL_ 297 IDB5_ACC_Enable 3 "ACC Communication Error" 2 "Permanently not Available" 1 "Temporarily not Available" 0 "Available";
VAL_ 297 IDB5_ACC_Sta 1 "ready" 0 "no ready";
VAL_ 297 IDB5_AEBactive 1 "Active" 0 "No Active";
VAL_ 299 IDB6_EPBStatus 7 "Not Initialized (NEW)" 6 "Full Released完全释放" 5 "Dynamic braking via EPB动态驻车" 4 "Releasing in progress卡钳释放中" 3 "Clamping in progress卡钳夹紧中" 2 "Clamped卡钳夹紧" 1 "Released卡钳释放" 0 "Unknown未知";
VAL_ 299 IDB6_EPBAvailable 6 "EPB  failure" 5 "EPB Permanently Not Available" 4 "EPB Temporarily Not Available" 3 "EPB Diagnostic" 2 "EPB Initialization State" 1 "EPB No failure" 0 "Not valid";
VAL_ 301 IDB7_ESCFail 1 "Fail" 0 "Not fail";
VAL_ 301 IDB7_ESCActive 1 "Active" 0 "Inactive";
VAL_ 301 IDB7_ESCDisable 1 "ESC Function Disabled" 0 "ESC Function Enabled";
VAL_ 301 IDB7_ABSActive 1 "Active" 0 "Inactive";
VAL_ 301 IDB7_EBD_Fail 1 "fail" 0 "no fail";
VAL_ 301 IDB7_EBD_Active 1 "Active" 0 "Inactive";
VAL_ 301 IDB7_HBAActive 1 "Active" 0 "Inactive";
VAL_ 301 IDB7_HBAFail 1 "Fail" 0 "Not fail";
VAL_ 301 IDB7_DiagMode 1 "DiagnosticMode" 0 "NormalMode";
VAL_ 301 IDB7_TCSActive 1 "Active" 0 "Inactive";
VAL_ 301 IDB7_TCSDisable 1 "TCS Function Disabled" 0 "TCS Function Enabled";
VAL_ 301 IDB7_TCSFail 1 "Fail" 0 "Not fail";
VAL_ 301 IDB7_ROPACTIVE 1 "Active" 0 "No Active";
VAL_ 301 IDB7_ROPFailure 1 "Failure" 0 "No Failure";
VAL_ 301 IDB7_DynParkBrkByIDBActive 1 "Active" 0 "Inactive";
VAL_ 301 IDB7_DynParkBrkByIDBAvailable 1 "Available" 0 "Not Available";
VAL_ 301 IDB7_HSAActive 1 "Active" 0 "Inactive";
VAL_ 301 IDB7_HSAFail 1 "Fail" 0 "Not fail";
VAL_ 301 IDB7_HDCEnabled 1 "Enabled" 0 "Disabled";
VAL_ 301 IDB7_HDCFail 1 "Fail" 0 "Not fail";
VAL_ 301 IDB7_HDCAtive 1 "Active" 0 "Not active";
VAL_ 301 IDB7_ABSFail 1 "fail" 0 "no fail";
VAL_ 302 IDB12_AVHDispMSG 3 "AUTO HOLD cannot be activated Close Door" 2 "Press Brake Pedal to Release AUTO HOLD" 1 "AUTO HOLD to be deactivated Press Brake Pedal" 0 "AVH is off";
VAL_ 302 IDB12_AVHLampReq 3 "AVH READY" 2 "AVH ACTIVE(Green)" 1 "AVH failure(Yellow)" 0 "AVH Off";
VAL_ 302 IDB12_AVHStatus 2 "AVH being released" 1 "AVH Active" 0 "AVH Inactive";
VAL_ 302 IDB12_AVHEnabled 1 "Enabled" 0 "Disabled";
VAL_ 177 EPS1_SteeringAngleValid 1 "Valid" 0 "Invalid";
VAL_ 177 EPS1_SteerAngleSpdValid 1 "Valid" 0 "Invalid";
VAL_ 177 EPS1_HSTWCalibrated 1 "calibrated" 0 "not calibrated";
VAL_ 177 EPS1_WarningLampRed 1 "Function failure, lamp on" 0 "close";
VAL_ 177 EPS1_TorsionBarTorqueValid 1 "Valid" 0 "Invalid";
VAL_ 177 EPS1_WarningLampYellow 3 "Reserved" 2 "function limited, lamp on" 1 "angle not calibrated, lamp blink" 0 "close";
VAL_ 178 EPS2_ADAS_Available 1 "Available" 0 "Not  Available";
VAL_ 178 EPS2_ADAS_Active 1 "active" 0 "not active";
VAL_ 178 EPS2_AssistPraSwitchToDAS 3 "Reserved" 2 "APA mode" 1 "ADAS mode" 0 "not in ADAS mode";
VAL_ 178 EPS2_ADAS_CtrlAbortFeedback 10 "Parking interruption" 9 "ADAS activation request error" 8 "Request Value over range" 7 "Request Slope over range" 6 "ADAS transmition signal error" 5 "EPS Temporary error" 4 "EPS Permanently error" 3 "Over speed" 2 "Vehicle Speed Invalid" 1 "Driver  override" 0 "No error";
VAL_ 178 EPS2_PA_Available 1 "Available" 0 "Not Available";
VAL_ 178 EPS2_PA_Active 1 "active" 0 "not active";
VAL_ 178 EPS2_MotCntrlValid 1 "Valid" 0 "Invalid";
VAL_ 178 EPS2_PA_CtrlAbortFeedback 9 "Parking activation error" 8 "Request Value over range" 7 "Request Slope over range" 6 "APA transmition signal error" 5 "EPS Temporary error" 4 "EPS Permanently error" 3 "Over speed" 2 "Vehicle Speed Invalid" 1 "Driver override" 0 "No error";
VAL_ 142 ADCS2_ADAS_EPSAngleReqSt 1 "Requested" 0 "No Request";
VAL_ 142 ADCS2_EPS_LDPState 4 "LDP passive" 3 "LDP Fail" 2 "LDP Active" 1 "LDP Standby" 0 "Off";
VAL_ 142 ADCS2_NNP_SystemFaultStatus 3 "Service Required" 2 "System Temporary Unvailable" 1 "Performance Degradation" 0 "No Error";
VAL_ 142 ADCS_Pilot_SystemFaultStatus 3 "Service Required" 2 "System Temporary Unvailable" 1 "Performance Degradation" 0 "No Error";
VAL_ 142 ADCS2_ADAS_EPSLateralCtrlType 7 "Reserved" 6 "Reserved" 5 "Reserved" 4 "ELK Mode" 3 "NNP Mode" 2 "Pilot Mode" 1 "LDP Mode" 0 "None";
VAL_ 142 ADCS2_ADAS_IHBCSysState 4 "System Failure" 3 "IHBC On & High Beam On" 2 "IHBC On & High Beam Off" 1 "Standby&passive" 0 "IHBC Off";
VAL_ 142 ADCS2_ALCDirection 4 "Warning Light" 3 "Shutdown" 2 "Right" 1 "Left" 0 "Off";
VAL_ 142 ADCS2_ACC_EpbReq 3 "Reserve" 2 "apply request" 1 "Release request" 0 "No request";
VAL_ 142 ADCS2_EPS_ELKState 4 "ELK Fail" 3 "ELK Active" 2 "ELK Standby" 1 "ELK passive" 0 "Off";
VAL_ 142 ADCS2_AEBVehicleHoldReq 1 "Requested" 0 "No Request";
VAL_ 142 ADCS2_AEBFullBrake 1 "Requested" 0 "No Request";
VAL_ 142 ADCS2_AEBPartialBrake 1 "Requested" 0 "No Request";
VAL_ 142 ADCS2_AEB_DBSLevel 3 "DBS level 3" 2 "DBS level 2" 1 "DBS level 1" 0 "No activation";
VAL_ 142 ADCS2_AEBPrefillReq 1 "Requested" 0 "No Request";
VAL_ 142 ADCS2_AEB_JerkReq 1 "Request" 0 "No request";
VAL_ 142 ADCS2_longitudCtrlType 3 "NNP Mode" 2 "NPilot Mode" 1 "ACC Mode" 0 "None";
VAL_ 142 ADCS2_LongitudCtrlDecToStopReq 1 "Requested" 0 "No Request";
VAL_ 142 ADCS2_LongitudCtrlDriveOff 1 "Requested" 0 "No Request";
VAL_ 142 ADCS2_AEB_JerkLevel 3 "Jerk level 3" 2 "Jerk level 2" 1 "Jerk level 1" 0 "No activation";
VAL_ 142 ADCS2_LongitudCtrlAccelCtrlReq 1 "Requested" 0 "No Request";
VAL_ 143 ADCS11_Parking_WorkSts 15 "Invalid" 11 "Cruising（HPP Pro）" 10 "Failure" 9 "Abort" 8 "Suspend" 7 "Complete" 6 "Localization" 5 "Map building" 4 "Cruising（HPP）" 3 "Parking" 2 "TBA standby" 1 "Standby(通过开关进入PA)" 0 "off";
VAL_ 310 ADCS12_FCWWarnAudioplay 1 "Warning Play" 0 "None";
VAL_ 310 ADCS12_RCTAWarnAudioplay 2 "Right Warning play" 1 "Left Warning play" 0 "None";
VAL_ 310 ADCS12_FCTAWarnAudioplay 2 "Right Warning play" 1 "Left Warning play" 0 "None";
VAL_ 310 ADCS12_SpeedWarnAudioplay 1 "Warning Play" 0 "None";
VAL_ 310 ADCS12_DOWWarnAudioplay 1 "Warning Play" 0 "None";
VAL_ 310 ADCS12_DCLCAudioplay 7 "Alert 4 broadcast" 6 "Alert 3 broadcast" 5 "Alert 2 broadcast" 4 "Alert 1 broadcast" 3 "Cancel broadcast" 2 "right broadcast" 1 "Left broadcast" 0 "None";
VAL_ 310 ADCS12_PilotAudioPlay 3 "Pilot cancel" 2 "Pilot resumed" 1 "Pilot Override" 0 "None";
VAL_ 310 ADCS12_HandOffAudioplay 3 "EM takeover broadcast" 2 "takeover braodcast" 1 "Handsoff warning broadcast" 0 "None";
VAL_ 310 ADCS12_NNPCancelAudioPlay 1 "NNP Cancel play" 0 "None";
VAL_ 310 ADCS12_RCWWarnAudioplay 1 "Warning Play" 0 "None";
VAL_ 310 ADCS12_MRMAudioPlay 3 "Finish broadcast" 2 "EM Warning broadcast" 1 "MRM Warning broadcast" 0 "None";
VAL_ 310 ADCS12_NNP_ResumeAudioplay 2 "Resume reminder" 1 "Suspended" 0 "None";
VAL_ 310 ADCS12_Lcsndrequest 2 "Request inactive" 1 "Request active" 0 "None";
VAL_ 310 ADCS12_Lcsndrconfirm 2 "Confirm inactive" 1 "Confirm active" 0 "None";
VAL_ 310 ADCS12_DriveOffBroadcast 1 "Requested" 0 "No Request";
VAL_ 310 ADCS12_EyeOffBroadcast 1 "Broadcast request" 0 "None";
VAL_ 310 ADCS12_longitudDisableInfo 15 "reason 4" 14 "reason 3" 13 "reason 2" 12 "reason 1" 11 "竞速模式" 10 "开关未开" 9 "无法开启" 8 "底盘(预留)" 7 "EPB拉起" 6 "前舱盖" 5 "后备箱" 4 "door open" 3 "seatbelt untied" 2 "braking" 1 "speed not satisfied" 0 "None";
VAL_ 310 ADCS12_SpeedAdaptComfirm 1 "request" 0 "No request";
VAL_ 310 ADCS12_PayModeConfirm 1 "Request" 0 "No request";
VAL_ 310 ADCS12_longitudCtrlSysInfo 11 "override提示" 10 "ACC lost arbitration" 9 "ACC is cancelled" 8 "Display HDC Request" 7 "Display Takeover Request" 6 "Display Disable to engage ACC" 5 "Display ACC disengaged" 4 "Display Available to resume acceleration control" 3 "Display Object disappeared" 2 "Display  ACC fault unavaliable" 1 "Display ACC on" 0 "Default";
VAL_ 310 ADCS12_ADAS_DriveOffinhibition 1 "Requested" 0 "No Request";
VAL_ 310 ADCS12_P2N_State_Reminder 7 "NNP unable to active by sound" 6 "degrad to Pilot Reminder" 5 "NNP Pre-degrade Reminder II" 4 "NNP Pre-degrade Reminder" 3 "NNP Active Reminder" 2 "Pilot pre-upgrade Reminder II" 1 "Pilot Pre-upgrade Reminder" 0 "No";
VAL_ 310 ADCS12_NNP_State_Reminder 7 "NNP_fault reminder" 6 "NNP dropped-out" 5 "NNP Pre-cancel Reminder III" 4 "NNP Pre-cancel Reminder II" 3 "NNP Pre-cancel Reminder" 2 "NNP activated Reminder" 1 "NNP ready to activate Reminder" 0 "No";
VAL_ 310 ADCS12_NNP_LightRemind 1 "Light not off" 0 "Not Used";
VAL_ 310 ADCS12_LaneChangePendingAlert 1 "Request" 0 "No Request";
VAL_ 310 ADCS12_NPilotSysInfo 31 "Reserved" 30 "Reserved" 29 "Reserved" 28 "Reserved" 27 "Reserved" 26 "Reserved" 25 "Reserved" 24 "Reserved" 23 "Reserved" 22 "Reserved" 21 "reason 5" 20 "reason 4" 19 "reason 3" 18 "reason 2" 17 "reason 1" 16 "开关关闭" 15 "不在ODD内" 14 "GPS信号差" 13 "无法开启" 12 "Racing mode" 11 "EPB拉起" 10 "前舱盖" 9 "后备箱" 8 "door open" 7 "reservedseatbelt untied" 6 "Disable to engage NPilot Cuz lane" 5 "Disable to engage NPilot Cuz braking" 4 "Disable to engage NPilot Cuz speed" 3 "Disable to engage NPilot cuz fault" 2 "NPilot Off" 1 "NPilot On" 0 "Disable to engage NPilot";
VAL_ 310 ADCS12_LCAudioPlay 2 "Right LaneChange active" 1 "Left Lane Change active" 0 "None";
VAL_ 310 ADCS12_NNP_Scenarios_AudioPlay 11 "Best Path Tracing" 10 "Oncoming Vehicle" 9 "Oversized Vehicle One Side" 8 "Oversized Vehicle Both Side" 7 "SpeedAdapt" 6 "Narrow Lane" 5 "Lane  Reduce" 4 "PayModeConfirm" 3 "Pedastrian Walk" 2 "TFL" 1 "Static Obstacle" 0 "None";
VAL_ 310 ADCS12_NNP_RINO 7 "Exit Missed" 6 "Navigation Task Take Over Request" 5 "Ramp Out DONE" 4 "Ramp Out Start" 3 "Ramp Out Heavy Traffic" 2 "Ramp In DONE" 1 "Ramp In Start" 0 "No Request";
VAL_ 403 ADCS8_LDWState 7 "Reserved" 6 "Reserved" 5 "Reserved" 4 "LDW passive" 3 "LDW Fail" 2 "LDW Active" 1 "LDW Standby" 0 "Off";
VAL_ 403 ADCS8_LDWWarnState 5 "Reserved" 4 "Right Warning leve2" 3 "Right Warning leve1" 2 "Left Warning leve2" 1 "Left Warning leve1" 0 "No Warning";
VAL_ 403 ADCS8_ELKMode 1 "On" 0 "Off";
VAL_ 403 ADCS8_LDPELKWarnState 3 "Reserved" 2 "Right Warning" 1 "Left Warning" 0 "No Warning";
VAL_ 403 ADCS8_lateralCtrHandsEyesOffWarning 3 "eyes off Warning" 2 "Automatic-Off Warning(Display)" 1 "Hands-off Warning(Display)" 0 "No Warning";
VAL_ 403 ADCS8_MissingExitAlert 3 "Reserved" 2 "Exit Missed" 1 "Navigation Task Take Over Request" 0 "No Warning";
VAL_ 403 ADCS8_ACCState 7 "Passive" 6 "Fault" 5 "Standstill Wait" 4 "Standstill Active" 3 "Override" 2 "Active" 1 "Standby" 0 "Off";
VAL_ 403 ADCS8_lateralCtrtakeover 1 "Requested" 0 "No request";
VAL_ 403 ADAS8_LateralCtrHandOffReleasewarning 1 "Requested" 0 "No request";
VAL_ 403 ADCS8_LDPELKtakeoverWarningstate 2 "Lever 2" 1 "Lever 1" 0 "No warning";
VAL_ 403 ADCS8_NNP_Scenarios 11 "Best Path Tracing" 10 "Oncoming Vehicle" 9 "Oversized Vehicle One Side" 8 "Oversized Vehicle Both Side" 7 "SpeedAdapt" 6 "Narrow Lane" 5 "Lane  Reduce" 4 "PayModeConfirm" 3 "Pedastrian Walk" 2 "TFL" 1 "Static Obstacle" 0 "None";
VAL_ 403 ADCS8_longitudCtrlTakeOverReq 1 "Requested" 0 "No Request";
VAL_ 403 ADCS8_longitudCtrlSetDistance 7 "Reserved2" 6 "Reserved1" 5 "Level#5" 4 "Level#4" 3 "Level#3" 2 "Level#2" 1 "Level#1" 0 "No time gap set";
VAL_ 403 ADCS8_longitudCtrlTargetValidity 1 "Valid target vehicle" 0 "No target vehicle";
VAL_ 403 ADCS8_ACCSystemFaultStatus 3 "Service Required" 2 "System Temporary Unvailable" 1 "Performance Degradation" 0 "No Error";
VAL_ 403 ADCS8_AEB_SystemFaultStatus 3 "Service Required" 2 "System Temporary Unvailable" 1 "Performance Degradation" 0 "No Error";
VAL_ 403 ADCS8_AEB_SystemStatus 1 "On" 0 "Off";
VAL_ 403 ADCS8_FCWSystemFaultStatus 3 "Service required" 2 "System temperary unavailable" 1 "Performance degrade" 0 "No error";
VAL_ 403 ADCS8_FCWStatus 3 "Reserved" 2 "Warning level2" 1 "Warning level1" 0 "No request";
VAL_ 403 ADCS8_FCWSensitiveLevel 2 "Early" 1 "Normal" 0 "Late";
VAL_ 403 ADCS8_FCW_State 1 "On" 0 "Off";
VAL_ 403 ADCS8_FCTA_State 1 "On" 0 "Off";
VAL_ 403 ADCS8_AILampMode 15 "Reserved" 14 "Reserved" 13 "GreenRightTurn" 12 "GreenLeftTurn" 11 "GreenBreathing" 10 "GreenBlinkIntermittent" 9 "GreenBlink1Hz" 8 "RedBlink2Hz" 7 "RedBink1Hz" 6 "YellowBli" 5 "BlueStayON" 4 "BlueRightTurn2Hz" 3 "BlueRightTurn1Hz" 2 "BlueLeftTurn2Hz" 1 "BlueLeftTurn1Hz" 0 "Default";
VAL_ 403 ADCS8_CDCS_CertificateState2 1 "有效" 0 "无效";
VAL_ 403 ADCS8_FCTA_SystemFaultStatus 3 "Service required" 2 "System temperary unavailable" 1 "Performance degrade" 0 "No error";
VAL_ 403 ADCS8_FCTAWarnObjType 3 "Reserved" 2 "Unknown" 1 "Vehicle" 0 "No Object";
VAL_ 403 ADCS8_FCTARightActiveSt 3 "Reserved" 2 "Level 2" 1 "Level 1" 0 "No Warning";
VAL_ 403 ADCS8_FCTALeftActiveSt 3 "Reserved" 2 "Level 2" 1 "Level 1" 0 "No Warning";
VAL_ 403 ADCS8_RCTA_SystemFaultStatus 3 "Service required" 2 "System temperary unavailable" 1 "Performance degrade" 0 "No error";
VAL_ 403 ADCS8_RCTARightWarnSt 3 "Reserved" 2 "Level 2" 1 "Level 1" 0 "No Warning";
VAL_ 403 ADCS8_RCTALeftWarnSt 3 "Reserved" 2 "Level 2" 1 "Level 1" 0 "No Warning";
VAL_ 403 ADCS8_RCTA_State 1 "On" 0 "Off";
VAL_ 403 ADCS8_DOW_State 1 "On" 0 "Off";
VAL_ 403 ADCS8_RCW_SystemFaultStatus 3 "Service required" 2 "System temperary unavailable" 1 "Performance degrade" 0 "No error";
VAL_ 403 ADCS8_RCW_WarnState 3 "Reserved" 2 "Level 2" 1 "Level 1" 0 "No Warning";
VAL_ 403 ADCS8_RCW_State 1 "On" 0 "Off";
VAL_ 403 ADCS8_ADAS_IHBCStat 1 "On" 0 "Off";
VAL_ 403 ADCS8_DOW_SystemFaultStatus 3 "Service required" 2 "System temperary unavailable" 1 "Performance degrade" 0 "No error";
VAL_ 403 ADCS8_DOWRightWarnState 3 "Level 3" 2 "Level 2" 1 "Level 1" 0 "No Warning";
VAL_ 403 ADCS8_DOWLeftWarnState 3 "Level 3" 2 "Level 2" 1 "Level 1" 0 "No Warning";
VAL_ 403 ADCS8_LCAState 1 "On" 0 "Off";
VAL_ 403 ADCS8_HornReq 1 "Request" 0 "No Request";
VAL_ 403 ADCS8_DoorUnlock 1 "Requested" 0 "No Request";
VAL_ 403 ADCS8_ADAS_HazardLampReq 1 "Request" 0 "No Request";
VAL_ 403 ADCS8_LKAActvSts 7 "Reserved" 6 "Reserved" 5 "Reserved" 4 "Reserved" 3 "LDP+LDW ON" 2 "LDP  ON（仅国外）" 1 "LDW ON" 0 "OFF";
VAL_ 403 ADCS8_LCALeftWarnSt 3 "Reserved" 2 "LV2 Warning(LCA)" 1 "LV1 Warning(BSD)" 0 "No warning";
VAL_ 403 ADCS8_LCARightWarnSt 3 "Reserved" 2 "LV2 Warning(LCA)" 1 "LV1 Warning(BSD)" 0 "No warning";
VAL_ 403 ADCS8_ACCOnOffState 1 "On" 0 "Off";
VAL_ 403 ADCS8_TSR_SpeedSign 15 "限速120km/h" 14 "限速110km/h" 13 "限速100km/h" 12 "限速90km/h" 11 "限速80km/h" 10 "限速70km/h" 9 "限速60km/h" 8 "限速50km/h" 7 "限速40km/h" 6 "限速35km/h" 5 "限速30km/h" 4 "限速20km/h" 3 "限速15km/h" 2 "限速10km/h" 1 "限速5km/h" 0 "No traffic limit speed";
VAL_ 403 ADCS8_TSRState 1 "On" 0 "Off";
VAL_ 403 ADCS8_LCASystemFaultStatus 3 "Service required" 2 "System temperary unavailable" 1 "Performance degrade" 0 "No error";
VAL_ 403 ADCS8_TSR_ForbiddenSign 15 "Reserved" 14 "Reserved" 13 "Reserved" 12 "Reserved" 11 "Reserved" 10 "Reserved" 9 "Reserved" 8 "No passing（禁止通行）" 7 "No turning back（禁止掉头）" 6 "No entry（禁止驶入）" 5 "No parking（禁止停车）" 4 "No turning（禁止转弯）" 3 "No straight（禁止直行）" 2 "No turning right（禁止右转）" 1 "No turning left（禁止左转）" 0 "No sign";
VAL_ 403 ADCS8_NNP_SOAAudioplay 1 "SOA Audiobroadcast" 0 "None";
VAL_ 403 ADCS8_TSR_SLFStatefeedback 1 "On" 0 "Off";
VAL_ 403 ADCS8_TSR_SpeedWarnState 1 "Warning" 0 "No Warning";
VAL_ 403 ADCS8_TSR_SystemFaultStatus 3 "Service required" 2 "System temperary unavailable" 1 "Performance degrade" 0 "No error";
VAL_ 403 ADCS8_TSR_StrLightColor 3 "Green" 2 "Yellow" 1 "Red" 0 "No signal";
VAL_ 403 ADCS8_TSR_RightLightColor 3 "Green" 2 "Yellow" 1 "Red" 0 "No signal";
VAL_ 403 ADCS8_TSR_LeftLightColor 3 "Green" 2 "Yellow" 1 "Red" 0 "No signal";
VAL_ 403 ADCS8_VoiceNotifFrequency_mode 2 "Detailed" 1 "Simple" 0 "Basic";
VAL_ 403 ADCS8_NPilot_SystemFaultStatus 3 "Service Required" 2 "System Temporary Unvailable" 1 "Performance Degradation" 0 "No Error";
VAL_ 403 ADCS8_NPilot_SysState 5 "passive" 4 "Fault" 3 "suspend" 2 "Active" 1 "Standby" 0 "OFF";
VAL_ 403 ADCS8_NNP_AutoOnOffSet 1 "On" 0 "Off";
VAL_ 403 ADCS8_NNP_SystemFaultStatus 3 "Service Required" 2 "System Temporary Unvailable" 1 "Performance Degradation" 0 "No Error";
VAL_ 403 ADCS8_NNPSysState 6 "Fault" 5 "Pilot" 4 "Suspend" 3 "TO_transition" 2 "Active" 1 "standby" 0 "Off and not avaliable and Passive";
VAL_ 403 ADCS8_DrvOffAlertState 3 "reserved" 2 "DrvOff Traffic light" 1 "DrvOff Object" 0 "Inactive";
VAL_ 403 ADCS8_DrvOffAlertSwitch 1 "ON" 0 "OFF";
VAL_ 403 ADCS8_DrvOffAlert_SystemFaultStatus 3 "Service Required" 2 "System Temporary unavailable" 1 "Performance Degradation" 0 "No Error";
VAL_ 403 ADCS8_Lanechangeinfor 7 "solid lane type" 6 "Lane change ongoing" 5 "Lane change pending" 4 "Lane change cancel" 3 "Lane change end" 2 "Lane change start" 1 "Vehicle Speed too low" 0 "None";
VAL_ 403 ADCS8_DCLCSysState 1 "On" 0 "Off";
VAL_ 403 ADCS8_LaneChangeSystemFaultStatus 3 "Service Required" 2 "System Temporary Unvailable" 1 "Performance Degradation" 0 "No Error";
VAL_ 403 ADCS8_LaneChangeWarning 3 "Reserved" 2 "Right Warning" 1 "Left Warning" 0 "No Warning";
VAL_ 403 ADCS8_ADAS_DriveOffPossilbe 1 "Requested" 0 "No Request";
VAL_ 403 ADCS8_SRR_FL_Fail 2 "Radar Fault" 1 "Radar Blocked" 0 "Radar is Working";
VAL_ 403 ADCS8_FRS_Fail 2 "Radar Fault" 1 "Radar Blocked" 0 "Radar is Working";
VAL_ 403 ADCS8_SRR_RL_Fail 2 "Radar Fault" 1 "Radar Blocked" 0 "Radar is Working";
VAL_ 403 ADCS8_DriveOffinhibitionObjType 4 "Unknown" 3 "Cyelist" 2 "Vehicle" 1 "Pedestrian" 0 "No Object";
VAL_ 403 ADCS8_SVC_RL_Fail 2 "Sensor Fault" 1 "Blocked" 0 "Normal";
VAL_ 403 ADCS8_SVC_FL_Fail 2 "Sensor Fault" 1 "Blocked" 0 "Normal";
VAL_ 403 ADCS8_SRR_RR_Fail 2 "Radar Fault" 1 "Radar Blocked" 0 "Radar is Working";
VAL_ 403 ADCS8_SRR_FR_Fail 2 "Radar Fault" 1 "Radar Blocked" 0 "Radar is Working";
VAL_ 403 ADCS8_TSR_OverspeedOnOffSet 1 "On" 0 "Off";
VAL_ 403 ADCS8_RVC_Fail 2 "Sensor Fault" 1 "Blocked" 0 "Normal";
VAL_ 403 ADCS8_VoiceMode 1 "More tips" 0 "Simple";
VAL_ 403 ADCS8_ALC_mode 1 "Automated LC" 0 "Voice allowed LC + Lever allowed LC";
VAL_ 403 ADCS8_NNP_State 1 "ON（开启）" 0 "OFF（关闭）";
VAL_ 403 ADCS8_FVC_120_Fail 3 "Over temp" 2 "Sensor Fault" 1 "Blocked" 0 "Normal";
VAL_ 403 ADCS8_Lanechangedirection 2 "right" 1 "left" 0 "None";
VAL_ 403 ADCS8_ADSDriving_mode 3 "Radical" 2 "Normal" 1 "Basic";
VAL_ 403 ADCS8_FVC_30_Fail 2 "Sensor Fault" 1 "Blocked" 0 "Normal";
VAL_ 403 ADCS8_SVC_RR_Fail 2 "Sensor Fault" 1 "Blocked" 0 "Normal";
VAL_ 403 ADCS8_SVC_FR_Fail 2 "Sensor Fault" 1 "Blocked" 0 "Normal";
VAL_ 403 ADCS8_NNP_MRM_status 4 "Stand&Warning" 3 "Finshied" 2 "MRM Ongoing" 1 "EM Ongoing" 0 "No";
VAL_ 403 ADCS8_NpilotOverride_State 3 "Not used" 2 "Resumed" 1 "Overriding" 0 "No";
VAL_ 403 ADCS8_SystemFault 3 "reserved" 2 "Service Required" 1 "System temporary Unavaliable" 0 "System Normal";
VAL_ 403 ADCS8_LeftLidarFault 2 "Sensor Fault" 1 "Blocked" 0 "Normal";
VAL_ 403 ADCS8_RightlidarFault 2 "Sensor Fault" 1 "Blocked" 0 "Normal";
VAL_ 403 ADCS8_NNP_SpeedLimit 0 "No traffic limit speed";
VAL_ 403 ADCS8_TSR_LimitOverspeedSet 255 "No Action";
VAL_ 403 ADCS8_FLC_LDWLKAAid_OnOff_fbk 7 "Reserved" 6 "Reserved" 5 "Reserved" 4 "LKA" 3 "LDW+LKA" 2 "LDW" 1 "OFF" 0 "No Request";
VAL_ 403 ADCS8_DOWVoiceWarnSt 3 "Reserved" 2 "Level 2" 1 "Level 1" 0 "No Warning";
VAL_ 403 ADCS8_Pilot_WorkMod 3 "FollowMode" 2 "LCCMode" 1 "ACCMode" 0 "OFF";
VAL_ 403 ADCS8_HandShakeSts 4 "Reserved" 3 "Invalid" 2 "Hands-on" 1 "Hands-off" 0 "No Detection";
VAL_ 403 ADCS8_DCLC_SubStatus 3 "Active" 2 "Standby" 1 "Passive" 0 "Inactive";
VAL_ 403 ADCS8_DCLC_SystemSts 3 "Reserved" 2 "Failure" 1 "ON" 0 "off";
VAL_ 403 ADCS8_DCLC_AutChgLane 6 "Cancel" 5 "Success" 4 "Right Change Lane Ongoing" 3 "Left Change Lane Ongoing" 2 "Right Change Lane Waiting" 1 "Left Change Lane Waiting" 0 "No Active";
VAL_ 403 ADCS8_HandsOffWarning 3 "reserved" 2 "Level 2 Warning" 1 "Level 1 Warning" 0 "No Warning";
VAL_ 404 ADCS8_RPA_CheckListDispReq6 1 "Not Satisfied" 0 "Slope is satisfied";
VAL_ 404 ADCS8_RPA_CheckListDispReq5 1 "Not Satisfied" 0 "Tire Pressure is satisfied";
VAL_ 404 ADCS8_RPA_CheckListDispReq4 1 "Not Satisfied" 0 "EPB is satisfied";
VAL_ 404 ADCS8_RPA_CheckListDispReq3 1 "Not Satisfied" 0 "Gear Conditions are satisfied";
VAL_ 404 ADCS8_RPA_CheckListDispReq2 1 "Not Satisfied" 0 "Vehicle is stanstill";
VAL_ 404 ADCS8_RPA_CheckListDispReq1 1 "Not Satisfied" 0 "Doors are all closed";
VAL_ 404 ADCS8_PA_warninginfo 96 "安全带未系，记忆泊车即将退出" 95 "坡度过大，记忆泊车暂不可用" 94 "检测到溜车,记忆泊车即将退出" 93 "环境异常,记忆泊车即将退出" 92 "车辆受阻,记忆泊车即将退出" 91 "坡度过大，记忆泊车即将退出" 90 "泊车超速，记忆泊车即将退出" 89 "发生碰撞，记忆泊车即将退出" 88 "EPB干预，记忆泊车即将退出" 87 "关联系统受限，功能无法开启" 86 "请在地下停车场使用记忆泊车" 85 "Reserved" 84 "松开刹车后，继续记忆泊车" 83 "请先挂D挡" 82 "请从地面回到地库，再开始学习" 81 "请保持车辆静止" 80 "记忆泊车暂不可用（笼统提示）" 79 "请立即接管车辆" 78 "请不要加速" 77 "记忆泊车即将退出（笼统提示）" 76 "关联系统受限，功能即将退出" 75 "系统受限，功能即将退出" 74 "用户干预挡位，记忆泊车即将退出" 73 "用户干预方向盘，记忆泊车即将退出" 72 "我没学会，重新再试试吧" 71 "关联系统受限，路线学习失败" 70 "系统受限，路线学习失败" 69 "车辆掉头，路线学习失败" 68 "倒车行驶，路线学习失败" 67 "坡度过大，路线学习失败" 66 "已超过最大学习里程，路线学习失败" 65 "速度过快，路线学习失败" 64 "路线重叠，路线学习失败" 63 "机舱盖打开，路线学习失败" 62 "行李箱打开，路线学习失败" 61 "车门打开，路线学习失败" 60 "遥控设备电量低" 59 "操作超时，请接管车辆" 58 "无法预期完成泊车，请稍后再试" 57 "请踩住刹车再选择车位" 56 "请在60s内连接蓝牙" 55 "车位搜索超时，功能中止，3s后退出" 54 "记忆泊?已暂停，请在30s内返回??继续泊?（手机）" 53 "导航地图不可用（手机）,功能无法开启" 52 "与车辆距离过远（手机）,功能无法开启" 51 "GPS或手机信号异常（手机）,功能无法开启" 50 "GPS或手机信号异常，功能终止，请前往处理" 49 "非封闭园区（手机）,功能无法开启" 48 "非停车场区域，功能无法开启" 47 "环境异常，功能终止，3S后退出（车端）/请前往处理（手机）" 46 "道路信息无法满足路线学习要求，记忆泊车已退出，已学习路线将删除" 45 "车辆掉头，记忆泊车已退出，已学习路线将删除" 44 "车辆受阻，功能终止，3S后退出（车端）/请前往处理（手机）" 43 "发生碰撞，功能终止，3S后退出（车端）/请前往处理（手机）" 42 "地图创建失败，功能终止，3S后退出（车端）/请前往处理（手机）" 41 "移动网络通讯差，功能终止，3S后退出（车端）/请前往处理（手机）" 40 "初始化定位失败，功能终止，3S后退出（车端）/请前往处理（手机）" 39 "路线学习失败，记忆泊车已退出，已学习路线将删除" 38 "系统错误，记忆泊车已退出，已学习路线将删除" 37 "泊车失败，记忆泊车已退出，已学习路线将删除" 36 "位置信息丢失，记忆泊车已退出，已学习路线将删除" 35 "跨层受限，记忆泊车已退出，已学习路线将删除" 34 "环境异常，记忆泊车已退出，已学习路线将删除" 33 "挂入R档，记忆泊车已退出，已学习路线将删除" 32 "已超过最大学习里程，记忆泊车已退出，已学习路线将删除" 31 "机舱盖打开，记忆泊车已退出，已学习路线将删除" 30 "行李箱打开，记忆泊车已退出，已学习路线将删除" 29 "车门打开，记忆泊车已退出，已学习路线将删除" 28 "胎压报警，功能终止，3S后退出（车端）/请前往处理（手机）" 27 "功能终止，系统3S后退出（车端）/请前往处理（手机）" 26 "遥控泊车按键松开，泊车暂停" 25 "蓝牙连接故障，请连接蓝牙后重试" 24 "后视镜被折叠，功能终止，3S后退出（车端）/请前往处理（手机）" 23 "泊车空间不足，功能终止，3S后退出（车端）/请前往处理（手机" 22 "电量不足，功能终止，3S后退出（车端）/请前往处理（手机）" 21 "雨量过大，功能终止，3S后退出（车端）/请前往处理（手机）" 20 "坡度过大，功能终止，3S后退出（车端）/请前往处理（手机）" 19 "NNP功能激活，功能终止，3S后退出（车端）/请前往处理（手机）" 18 "驾驶员干预，功能终止，3S后退出（车端）/请前往处理（手机）" 17 "泊车超步，功能终止，3S后退出（车端）/请前往处理（手机）" 16 "泊车超时，功能终止，3S后退出（车端）/请前往处理（手机）" 15 "泊车超速，功能终止，3S后退出（车端）/请前往处理（手机）" 14 "泊车系统故障，功能终止，3S后退出（车端）/请前往处理（手机）" 13 "关联系统故障，功能终止，3S后退出（车端）/请前往处理（手机）" 12 "中断时间超时，功能终止，3S后退出（车端）/请前往处理（手机）" 11 "中断次数超限，功能终止，3S后退出（车端）/请前往处理（手机）" 10 "轨迹内有障碍物，请处理后重试" 9 "系统检测到刹车，功能中断，松开刹车后，泊车继续" 8 "安全带未系，请系上安全带后重试" 7 "机舱盖开启，请关闭后重试" 6 "行李箱门开启，请关闭后重试" 5 "车门被打开，请关闭后重试" 4 "请系好安全带" 3 "请关闭机舱盖开启" 2 "请关闭行李箱门" 1 "请关闭车门" 0 "Normal";
VAL_ 404 ADCS8_PA_FPAS_SnsrObjWrnngZn_FLM 4 "Zone4" 3 "Zone3" 2 "Zone2" 1 "Zone1" 0 "No Object";
VAL_ 404 ADCS8_PA_FPAS_SnsrObjWrnngZn_FLC 4 "Zone4" 3 "Zone3" 2 "Zone2" 1 "Zone1" 0 "No Object";
VAL_ 404 ADCS8_RPA_CheckListDispReq8 1 "Not Satisfied" 0 "System is normal";
VAL_ 404 ADCS8_RPA_CheckListDispReq7 1 "Not Satisfied" 0 "System is normal";
VAL_ 404 ADCS8_PA_FPAS_SnsrObjWrnngZn_FRC 4 "Zone4" 3 "Zone3" 2 "Zone2" 1 "Zone1" 0 "No Object";
VAL_ 404 ADCS8_PA_FPAS_SnsrObjWrnngZn_FRM 4 "Zone4" 3 "Zone3" 2 "Zone2" 1 "Zone1" 0 "No Object";
VAL_ 404 ADCS8_PA_FPAS_SnsrObjWrnngZn_RLM 4 "Zone4" 3 "Zone3" 2 "Zone2" 1 "Zone1" 0 "No Object";
VAL_ 404 ADCS8_PA_FPAS_SnsrObjWrnngZn_RLC 4 "Zone4" 3 "Zone3" 2 "Zone2" 1 "Zone1" 0 "No Object";
VAL_ 404 ADCS8_PA_FPAS_SnsrObjWrnngZn_RRC 4 "Zone4" 3 "Zone3" 2 "Zone2" 1 "Zone1" 0 "No Object";
VAL_ 404 ADCS8_PA_FPAS_SnsrObjWrnngZn_RRM 4 "Zone4" 3 "Zone3" 2 "Zone2" 1 "Zone1" 0 "No Object";
VAL_ 404 ADCS8_PA_FPAS_SnsrObjWrnngZn_SFR 4 "Zone4" 3 "Zone3" 2 "Zone2" 1 "Zone1" 0 "No Object";
VAL_ 404 ADCS8_PA_FPAS_SnsrObjWrnngZn_SFL 4 "Zone4" 3 "Zone3" 2 "Zone2" 1 "Zone1" 0 "No Object";
VAL_ 404 ADCS8_PA_FPAS_SnsrObjWrnngZn_SRR 4 "Zone4" 3 "Zone3" 2 "Zone2" 1 "Zone1" 0 "No Object";
VAL_ 404 ADCS8_PA_FPAS_SnsrObjWrnngZn_SRL 4 "Zone4" 3 "Zone3" 2 "Zone2" 1 "Zone1" 0 "No Object";
VAL_ 404 ADCS8_PA_FPAS_SnsrDist_FLC 255 "Invalid";
VAL_ 404 ADCS8_PA_FPAS_SnsrDist_FLM 255 "Invalid";
VAL_ 404 ADCS8_PA_FPAS_SnsrDist_FRM 255 "Invalid";
VAL_ 404 ADCS8_PA_FPAS_SnsrDist_FRC 255 "Invalid";
VAL_ 404 ADCS8_PA_FPAS_SnsrDist_RLC 255 "Invalid";
VAL_ 404 ADCS8_PA_FPAS_SnsrDist_RLM 255 "Invalid";
VAL_ 404 ADCS8_PA_FPAS_SnsrDist_RRM 255 "Invalid";
VAL_ 404 ADCS8_PA_FPAS_SnsrDist_RRC 255 "Invalid";
VAL_ 404 ADCS8_PA_FPAS_SnsrDist_SFL 511 "Invalid";
VAL_ 404 ADCS8_PA_FPAS_SnsrDist_SFR 511 "Invalid";
VAL_ 404 ADCS8_PA_FPAS_SnsrDist_SRL 511 "Invalid";
VAL_ 404 ADCS8_PA_FPAS_SnsrDist_SRR 511 "Invalid";
VAL_ 404 ADCS8_PA_FPAS_SensorFaultStsFRC 1 "Sensor fault" 0 "Sensor normal";
VAL_ 404 ADCS8_PA_FPAS_SensorFaultStsFRM 1 "Sensor fault" 0 "Sensor normal";
VAL_ 404 ADCS8_PA_FPAS_SensorFaultStsFLM 1 "Sensor fault" 0 "Sensor normal";
VAL_ 404 ADCS8_PA_FPAS_SensorFaultStsFLC 1 "Sensor fault" 0 "Sensor normal";
VAL_ 404 ADCS8_PA_RPAS_WorkSts 3 "Failed" 2 "Active" 1 "Standby" 0 "Disabled";
VAL_ 404 ADCS8_PA_FPAS_WorkSts 3 "Failed" 2 "Active" 1 "Standby" 0 "Disabled";
VAL_ 404 ADCS8_PA_RPAS_SensorFaultStsSRR 1 "Sensor fault" 0 "Sensor normal";
VAL_ 404 ADCS8_PA_RPAS_SensorFaultStsSRL 1 "Sensor fault" 0 "Sensor normal";
VAL_ 404 ADCS8_PA_FPAS_SensorFaultStsSFR 1 "Sensor fault" 0 "Sensor normal";
VAL_ 404 ADCS8_PA_FPAS_SensorFaultStsSFL 1 "Sensor fault" 0 "Sensor normal";
VAL_ 404 ADCS8_PA_RPAS_SensorFaultStsRRC 1 "Sensor fault" 0 "Sensor normal";
VAL_ 404 ADCS8_PA_RPAS_SensorFaultStsRRM 1 "Sensor fault" 0 "Sensor normal";
VAL_ 404 ADCS8_PA_RPAS_SensorFaultStsRLM 1 "Sensor fault" 0 "Sensor normal";
VAL_ 404 ADCS8_PA_RPAS_SensorFaultStsRLC 1 "Sensor fault" 0 "Sensor normal";
VAL_ 404 ADCS8_AudBpRate_R 6 "Warning Level 4_R" 5 "Warning Level 3_R" 4 "Warning Level 2_R" 3 "Warning Level 1_R" 2 "SyStem fault" 1 "System normal" 0 "No Request";
VAL_ 404 ADCS8_AudBpRate_F 6 "Warning Level 4_F" 5 "Warning Level 3_F" 4 "Warning Level 2_F" 3 "Warning Level 1_F" 2 "SyStem fault" 1 "System normal" 0 "No Request";
VAL_ 404 ADCS8_AVM_MODWarning 1 "Warning" 0 "No warning";
VAL_ 404 ADCS8_AVM_RomoteAVMFeedBack 1 "On" 0 "Off";
VAL_ 404 ADCS8_PA_FPAS_SnsrObjWrnngZn_RSDW 4 "Zone4" 3 "Zone3" 2 "Zone2" 1 "Zone1" 0 "No Object";
VAL_ 404 ADCS8_PA_FPAS_SnsrObjWrnngZn_LSDW 4 "Zone4" 3 "Zone3" 2 "Zone2" 1 "Zone1" 0 "No Object";
VAL_ 404 ADCS8_PA_FPAS_SnsrObjWrnnglc_RSDW 3 "Air3" 2 "Air2" 1 "Air1" 0 "Norequst";
VAL_ 404 ADCS8_PA_FPAS_SnsrObjWrnnglc_LSDW 3 "Air3" 2 "Air2" 1 "Air1" 0 "Norequst";
VAL_ 404 ADCS8_Mod_Object_MovingDirection 15 "Reserve" 9 "Reserve" 8 "Right Rear Side" 7 "Right Side" 6 "Right Front Side" 5 "Front Side" 4 "Left Front Side" 3 "Left Side" 2 "Left Rear Side" 1 "Rear Side" 0 "No Object";
VAL_ 1556 FLC_RepeatMessageRequest 1 "Repeat message request" 0 "No repeat message request";
VAL_ 1556 FLC_ActiveWakeup 1 "Wakeup" 0 "No wakeup";
VAL_ 1556 FLC_WakeUp_KL15 1 "KL15 ON Wakeup" 0 "No Request";
VAL_ 1556 FLC_WakeUp_NM 1 "NM Wakeup" 0 "No Request";
VAL_ 1556 FLC_WakeUpReason4 1 "Wakeup Requrst" 0 "No Request";
VAL_ 1556 FLC_WakeUpReason5 1 "Wakeup Requrst" 0 "No Request";
VAL_ 1556 FLC_WakeUpReason6 1 "Wakeup Requrst" 0 "No Request";
VAL_ 1556 FLC_WakeUpReason7 1 "Wakeup Requrst" 0 "No Request";
VAL_ 1556 FLC_WakeUpReason8 1 "Wakeup Requrst" 0 "No Request";
VAL_ 1556 FLC_RepeatFromSleep 1 "occur;" 0 "not occur;";
VAL_ 1556 FLC_RepeatFromPrepare 1 "occur;" 0 "not occur;";
VAL_ 1556 FLC_NormalFromRepeat 1 "occur;" 0 "not occur;";
VAL_ 1556 FLC_NormalFromReady 1 "occur;" 0 "not occur;";
VAL_ 1556 FLC_RepeatFromReady 1 "occur;" 0 "not occur;";
VAL_ 1556 FLC_RepeatFromNormal 1 "occur;" 0 "not occur;";
VAL_ 1556 FLC_RNM_DOW 1 "DOW" 0 "default";
VAL_ 196 ACU2_LatAccSensorValueV 1 "Valid(有效)" 0 "Invalid(无效)";
VAL_ 196 ACU2_VehicleDynYawRateV 1 "Valid(有效)" 0 "Invalid(无效)";
VAL_ 196 ACU2_Sensorcalibration 1 "calibration(已标定)" 0 "No calibration(未标定)";
VAL_ 196 ACU2_LongAccSensorValueV 1 "Valid(有效)" 0 "Invalid(无效)";
VAL_ 258 ACU1_Driver_Buckle 3 "Not Avaliable(安全带未配置)" 2 "Fault(安全带有错)" 1 "Unbuckled(安全带未系上)" 0 "Buckled(安全带系上)";
VAL_ 258 ACU1_Passenger_Buckle 3 "Not Avaliable(安全带未配置)" 2 "Fault(安全带有错)" 1 "Unbuckled(安全带未系上)" 0 "Buckled(安全带系上)";
VAL_ 258 ACU1_Passenger_ODS 3 "Not Avaliable(安全带未配置)" 2 "Fault(安全带有错)" 1 "Unoccupied（无人）" 0 "Occupied（有人）";
VAL_ 258 ACU1_CrashStatus 1 "Crash happened（有碰撞事件）" 0 "Crash not happened（没有碰撞事件）";
VAL_ 258 ACU1_warningLight 3 "Reserved" 2 "AWL Flashing（警报灯闪）" 1 "AWL ON（警报灯亮）" 0 "AWL OFF（警报灯灭）";
VAL_ 258 ACU1_Rear_Right_Buckle 7 "Reserved" 6 "Reserved" 5 "Reserved" 4 "Reserved" 3 "Not Avaliable(锁扣未配置）" 2 "Fault(锁扣有错)" 1 "Unbuckled" 0 "Buckled";
VAL_ 258 ACU1_Rear_Left_Buckle 7 "Reserved" 6 "Reserved" 5 "Reserved" 4 "Reserved" 3 "Not Avaliable(锁扣未配置）" 2 "Fault(锁扣有错)" 1 "Unbuckled" 0 "Buckled";
VAL_ 258 ACU1_Rear_Middle_Buckle 7 "Reserved" 6 "Reserved" 5 "Reserved" 4 "Reserved" 3 "Not Avaliable(锁扣未配置）" 2 "Fault(锁扣有错)" 1 "Unbuckled" 0 "Buckled";
VAL_ 258 ACU1_Rear_Left_ODS 3 "Not Avaliable(未配置)" 2 "Fault(故障)" 1 "Unoccupied（无人）" 0 "Occupied（有人）";
VAL_ 258 ACU1_Rear_Middle_ODS 3 "Not Avaliable(未配置)" 2 "Fault(故障)" 1 "Unoccupied（无人）" 0 "Occupied（有人）";
VAL_ 258 ACU1_Rear_Right_ODS 3 "Not Avaliable(未配置)" 2 "Fault(故障)" 1 "Unoccupied（无人）" 0 "Occupied（有人）";
VAL_ 258 ACU1_Rear_Left_BuckleSts_Logic 7 "Reserved" 6 "Reserved" 5 "Unbuckled（无ODS）" 4 "Buckled（无ODS）" 3 "Not Avaliable(锁扣未配置)" 2 "Fault(安全带有错)" 1 "Occupied and Unbuckled（有人未系）" 0 "Buckled Or unOccupied（安全带系上或者无人）";
VAL_ 258 ACU1_Rear_Midlle_BuckleSts_Logic 7 "Reserved" 6 "Reserved" 5 "Unbuckled（无ODS）" 4 "Buckled（无ODS）" 3 "Not Avaliable(锁扣未配置)" 2 "Fault(安全带有错)" 1 "Occupied and Unbuckled（有人未系）" 0 "Buckled Or unOccupied（安全带系上或者无人）";
VAL_ 258 ACU1_Rear_Right_BuckleSts_Logic 7 "Reserved" 6 "Reserved" 5 "Unbuckled（无ODS）" 4 "Buckled（无ODS）" 3 "Not Avaliable(锁扣未配置)" 2 "Fault(安全带有错)" 1 "Occupied and Unbuckled（有人未系）" 0 "Buckled Or unOccupied（安全带系上或者无人）";
VAL_ 272 BDCS1_PowerMode 3 "Crank" 2 "ON" 1 "ACC" 0 "OFF";
VAL_ 272 BDCS1_PowerManageMode 15 "Reserved" 14 "Reserved" 13 "Reserved" 12 "Reserved" 11 "ON(Not Power OFF)" 10 "ON(Biological)" 9 "ON(Guard)" 8 "RUNNING" 7 "CRANK" 6 "ON(Remote)" 5 "ON(OTA)" 4 "ON(PetToLookAfter)" 3 "ON(120min)" 2 "ON(5min)" 1 "ON(Factory)" 0 "OFF";
VAL_ 272 BDCS1_LowBeamSt 1 "Active" 0 "Inactive";
VAL_ 272 BDCS1_HighBeamSt 1 "Active" 0 "Inactive";
VAL_ 272 BDCS1_PositionLightSts 1 "Active" 0 "Inactive";
VAL_ 272 BDCS1_BacklightStatus 1 "Active" 0 "Inactive";
VAL_ 272 BDCS1_LeftTurnLightSt 1 "Active" 0 "Inactive";
VAL_ 272 BDCS1_RightTurnLightSt 1 "Active" 0 "Inactive";
VAL_ 272 BDCS1_FrontLampSt 3 "LowBeam" 2 "PositionLamp" 1 "Auto" 0 "OFF";
VAL_ 272 BDCS1_HazardLampSt 1 "Active" 0 "Inactive";
VAL_ 272 BDCS1_HighBeamSW 3 "Reserved" 2 "HighBeam" 1 "Flash" 0 "OFF";
VAL_ 272 BDCS1_TurnLightSW 3 "Reserved" 2 "Right" 1 "Left" 0 "OFF";
VAL_ 272 BDCS1_HazardSwSt 1 "Active" 0 "Inactive";
VAL_ 272 BDCS1_RearFogLampSt 1 "Active" 0 "Inactive";
VAL_ 272 BDCS1_FrontFogLampSt 1 "Active" 0 "Inactive";
VAL_ 272 BDCS1_TrunkLockSts 1 "Locked" 0 "Unlocked";
VAL_ 272 BDCS1_HoodAjarSts 1 "Open" 0 "Closed";
VAL_ 274 BDCS3_RemoteAuthenSts 3 "Reserved" 2 "Authentication Failed" 1 "Authentication Successed" 0 "Default";
VAL_ 274 BDCS3_BackDoorAjar 7 "Unknow" 6 "Reserved" 5 "Reserved" 4 "Cannot Close Area" 3 "Fully Open" 2 "Open to Custon Height" 1 "Not Closed" 0 "Fully Closed";
VAL_ 274 BDCS3_ADCSAuthenSts 3 "Reserved" 2 "Authentication Failed" 1 "Authentication Successed" 0 "Default";
VAL_ 276 CS1_FrontWiperMISTReqSt 1 "Active" 0 "Inactive";
VAL_ 276 CS1_HighBeamFlashReqSt 1 "Active" 0 "Inactive";
VAL_ 276 CS1_HighBeamReqSt 1 "Active" 0 "Inactive";
VAL_ 276 CS1_TurnLightReqSt 7 "Error" 4 "TurnLeftStatus" 3 "左变道" 2 "TurnRightStatus" 1 "右变道" 0 "No request";
VAL_ 276 CS1_FrontWiperReqSt 7 "Error" 5 "AUTO 2" 4 "AUTO 1" 3 "HI" 2 "LOW" 1 "MIST（Reserved）" 0 "OFF";
VAL_ 276 CS1_FrontWiperWashReqSt 1 "Active" 0 "Inactive";
VAL_ 276 CS1_RearWiperReqSt_Reserved 1 "Active" 0 "Inactive";
VAL_ 276 CS1_RearWiperWashReqSt_Reserved 1 "Active" 0 "Inactive";
VAL_ 276 CS1_GearPositionReqSt 7 "Gear hold（Reserved）" 6 "S（Reserved）" 5 "D" 4 "N2" 3 "N1" 2 "R" 1 "P（Reserved）" 0 "No request";
VAL_ 276 CS1_GearPositionReqStInv 7 "No request" 6 "P(Reserved)" 5 "R" 4 "N1" 3 "N2" 2 "D" 1 "S(Reserved)" 0 "Gear Hold(Reserved)";
VAL_ 276 CS1_GearPositionReqStValid 1 "Valid" 0 "Invalid";
VAL_ 486 BDCS6_FrontWiperParkPos 1 "Park" 0 "Not park";
VAL_ 486 BDCS6_FrontWiperSts 7 "Reserved3" 6 "Reserved2" 5 "Reserved1" 4 "Reserved0" 3 "Reserved" 2 "High" 1 "Low" 0 "OFF";
VAL_ 486 BDCS6_DayNightMode 2 "Night mode" 1 "Day mode" 0 "Default";
VAL_ 645 BDCS13_RLS_RQ_WiperSPD 3 "Not used" 2 "High Speed" 1 "Low Speed" 0 "No wiping";
VAL_ 418 DDCU1_FLDoorAjar 3 "Unknow" 2 "Open" 1 "Secondary" 0 "Closed";
VAL_ 418 DDCU1_RLDoorAjar 3 "Unknow" 2 "Open" 1 "Secondary" 0 "Closed";
VAL_ 418 DDCU1_MirrorFoldSt 1 "Fold" 0 "Unfold";
VAL_ 419 PDCU1_FRDoorAjar 3 "Unknow" 2 "Open" 1 "Secondary" 0 "Closed";
VAL_ 419 PDCU1_RRDoorAjar 3 "Unknow" 2 "Open" 1 "Secondary" 0 "Closed";
VAL_ 320 CDCS3_ESCOffSw 3 "Reserved" 2 "OFF" 1 "ON" 0 "No Action";
VAL_ 320 CDCS3_HDCSw 3 "Reserved" 2 "OFF" 1 "ON" 0 "No Action";
VAL_ 320 CDCS3_DriveModeSet 4 "LAUNCH" 3 "CONFORM" 2 "SPORT" 1 "ECO" 0 "No Action";
VAL_ 320 CDCS3_Xcoordinate 0 "No Action";
VAL_ 320 CDCS3_Ycoordinate 0 "No Action";
VAL_ 320 CDCS3_XGestureSpd 0 "No Action";
VAL_ 320 CDCS3_YGestureSpd 0 "No Action";
VAL_ 320 CDCS3_TouchEvtTyp 10 "Rotate" 9 "Zoom out" 8 "Zoom in" 7 "One finger swipe" 6 "One finger moving" 5 "One finger long press" 4 "One finger double click" 3 "One finger single click" 2 "One finger up" 1 "One finger down" 0 "No Action";
VAL_ 442 CDCS10_WorK_status 3 "Reserved" 2 "Error" 1 "Ready" 0 "NotReady";
VAL_ 443 CDCS13_SwSmMode 3 "Reserved" 2 "BDCS-外后视镜" 1 "ARHUD" 0 "Default";
VAL_ 468 CDCS5_ResetAllSetup 1 "Reset" 0 "No Action";
VAL_ 468 CDCS5_FactoryReset 1 "Reset" 0 "No Action";
VAL_ 501 CDCS11_LKSSetspeed 0 "No action";
VAL_ 501 CDCS11_LDW_OnOffSet 3 "reserved" 2 "OFF" 1 "ON" 0 "No action";
VAL_ 501 CDCS11_LowSpeedBSDSw 3 "reserved" 2 "OFF" 1 "ON" 0 "No action";
VAL_ 501 CDCS11_FCW_OnOffSet 3 "reserved" 2 "OFF" 1 "ON" 0 "No action";
VAL_ 501 CDCS11_AEB_OnOffSet 3 "reserved" 2 "OFF" 1 "ON" 0 "No action";
VAL_ 501 CDCS11_FCW_WarnTiming 3 "Early" 2 "Normal" 1 "Late" 0 "No action";
VAL_ 501 CDCS11_FCTA_OnOffSet 3 "reserved" 2 "OFF" 1 "ON" 0 "No action";
VAL_ 501 CDCS11_RCTA_OnOffSet 3 "reserved" 2 "OFF" 1 "ON" 0 "No action";
VAL_ 501 CDCS11_RCW_OnOffSet 3 "reserved" 2 "OFF" 1 "ON" 0 "No action";
VAL_ 501 CDCS11_DOW_OnOffSet 3 "reserved" 2 "OFF" 1 "ON" 0 "No action";
VAL_ 501 CDCS11_IHBC_SysSwState 3 "reserved" 2 "OFF" 1 "ON" 0 "No action";
VAL_ 501 CDCS11_LCA_OnOffSet 3 "reserved" 2 "OFF" 1 "ON" 0 "No action";
VAL_ 501 CDCS11_TSR_OnOffSet 3 "reserved" 2 "OFF" 1 "ON" 0 "No action";
VAL_ 501 CDCS11_AVM_3DRotate 3 "reserved" 2 "OFF" 1 "ON" 0 "No action";
VAL_ 501 CDCS11_AVM_Turnlightstart 3 "reserved" 2 "OFF" 1 "ON" 0 "No action";
VAL_ 501 CDCS11_AVM_Steeringstart 3 "reserved" 2 "OFF" 1 "ON" 0 "No action";
VAL_ 501 CDCS11_AVM_Magnifiedview 3 "reserved" 2 "OFF" 1 "ON" 0 "No action";
VAL_ 501 CDCS11_AVM_MODdetection 3 "reserved" 2 "OFF" 1 "ON" 0 "No action";
VAL_ 501 CDCS11_GM_OnOffSet 3 "reserved" 2 "OFF" 1 "ON" 0 "No action";
VAL_ 501 CDCS11_NNP_OnOffSet 3 "reserved" 2 "OFF" 1 "ON" 0 "No action";
VAL_ 501 CDCS11_DCLCSysState 3 "reserved" 2 "OFF" 1 "ON" 0 "No action";
VAL_ 501 CDCS11_ALCSysState 3 "reserved" 2 "OFF" 1 "ON" 0 "No action";
VAL_ 501 CDCS11_DriveOffPossilbeswitch 3 "reserved" 2 "OFF" 1 "ON" 0 "No action";
VAL_ 501 CDCS11_DriveOffinhibitionswitch 3 "reserved" 2 "OFF" 1 "ON" 0 "No action";
VAL_ 501 CDCS11_ADAS_SndCtrlOnOff 3 "reserved" 2 "OFF" 1 "ON" 0 "No action";
VAL_ 501 CDCS11_AVM_auxiliaryline 3 "reserved" 2 "OFF" 1 "ON" 0 "No action";
VAL_ 501 CDCS11_AVM_Raderdisplay 3 "reserved" 2 "OFF" 1 "ON" 0 "No action";
VAL_ 501 CDCS11_AVM_Transparentchassis 3 "reserved" 2 "OFF" 1 "ON" 0 "No action";
VAL_ 501 CDCS11_VoiceMode 3 "Reserved" 2 "More Tips" 1 "Simple" 0 "no action";
VAL_ 501 CDCS11_NNP_Active_OnOffSet 3 "Reserved" 2 "ON（开启）" 1 "OFF（关闭）" 0 "No Action";
VAL_ 501 CDCS11_ALC_mode 2 "Automated LC" 1 "Voice allowed LC + Lever allowed LC" 0 "no action";
VAL_ 501 CDCS11_ADSDriving_mode 3 "Radical" 2 "Normal" 1 "Basic" 0 "No action";
VAL_ 501 CDCS11_TSR_OverspeedOnoffSet 3 "Reserved" 2 "OFF" 1 "ON" 0 "No Action";
VAL_ 501 CDCS11_NNP_AutoOnOffSet 3 "Reserved" 2 "OFF" 1 "ON" 0 "No Action";
VAL_ 501 CDCS11_SnCtrl_NNP_OnOff 2 "NNP OFF Request" 1 "NNP ON Request" 0 "No Request";
VAL_ 501 CDCS11_GM_VidedIn 3 "Reserved" 2 "OFF" 1 "ON" 0 "No Action";
VAL_ 501 CDCS11_TSR_SLFOnOffSet 3 "Reserved" 2 "OFF" 1 "ON" 0 "No Action";
VAL_ 501 CDCS11_APA_FunctionMode 9 "TAB on" 8 "ISM on" 7 "AVP on" 6 "HPP on" 5 "RPA on" 4 "FAPA on" 3 "choice parking in" 2 "Parking out" 1 "Parking in" 0 "No Request";
VAL_ 501 CDCS11_TrackreverseSW 2 "Track revers off" 1 "Track revers on" 0 "No Request";
VAL_ 501 CDCS11_SetPathwaySW 2 "off" 1 "on" 0 "No Request";
VAL_ 501 CDCS11_PA_changeLanguage 2 "English" 1 "Chinese" 0 "No Action";
VAL_ 501 CDCS11_LDP_OnOffSet 3 "reserved" 2 "OFF" 1 "ON" 0 "No action";
VAL_ 501 CDCS11_AVMSw 3 "Show Calibration" 2 "Show AVM" 1 "Hide" 0 "No Request";
VAL_ 501 CDCS11_tryHPP 1 "Request" 0 "No Request";
VAL_ 501 CDCS11_RPASw 3 "reserved" 2 "OFF" 1 "ON" 0 "No action";
VAL_ 501 CDCS11_SetSw 1 "Request" 0 "No Request";
VAL_ 501 CDCS11_SoundCtrlSetReq 7 "request AVM off" 6 "request AVM on" 5 "request RPA off" 4 "request RPA on" 3 "Start APA Parking" 2 "request APA off" 1 "request APA on" 0 "No Request";
VAL_ 501 CDCS11_location_sw 1 "parking area" 0 "default";
VAL_ 501 CDCS11_Pathrefresh 1 "Request Path refresh" 0 "No Request";
VAL_ 501 CDCS11_HPAGuideSW 2 "off" 1 "on" 0 "No Request";
VAL_ 501 CDCS11_HPAPathwaytoCloudSW 2 "off" 1 "on" 0 "No Request";
VAL_ 501 CDCS11_PathlearningSw 2 "Request Path learning off" 1 "Request Path learning on" 0 "No Request";
VAL_ 501 CDCS11_PA_screenMd 9 "TAB" 8 "ISM" 7 "AVP" 6 "HPP" 5 "RPA" 4 "FAPA" 3 "AVM" 2 "RVC" 1 "PDC" 0 "No Request";
VAL_ 501 CDCS11_PASw 3 "Reserve" 2 "Request PA off" 1 "Request PA on" 0 "No Request";
VAL_ 501 CDCS11_PA_Recover 1 "Recover" 0 "Default";
VAL_ 501 CDCS_Lcsndrequest 3 "Request inactive" 2 "Request  active right" 1 "Request active left" 0 "No action";
VAL_ 501 CDCS_Lcsndconfirm 2 "Confirm inactive" 1 "Confirm active" 0 "No action";
VAL_ 501 CDCS_SpdAdaptComfirm 2 "No" 1 "OK" 0 "No Action";
VAL_ 501 CDCS_PayModeConfirm 2 "No" 1 "OK" 0 "No Action";
VAL_ 501 CDCS11_SelectSlotID 15 "Reserved" 14 "Reserved" 13 "Reserved" 12 "slot 12" 11 "slot 11" 10 "slot 10" 9 "slot 9" 8 "slot 8" 7 "slot 7" 6 "slot 6" 5 "slot 5" 4 "slot 4" 3 "slot 3" 2 "slot 2" 1 "slot 1" 0 "No Action";
VAL_ 501 CDCS11_ParkingInReq 2 "Request  RPA" 1 "Request" 0 "No Request";
VAL_ 501 CDCS11_ParkingOutReq 2 "Request  RPA" 1 "Request" 0 "No Request";
VAL_ 501 CDCS11_AVM_ViewMode 2 "Request 3D Mode" 1 "Request 2D Mode" 0 "No Action";
VAL_ 501 CDCS11_RPA_FunctionMode 3 "choice parking in" 2 "Parking out" 1 "Parking in" 0 "No action";
VAL_ 501 CDCS11_AVM_VideoOutputFail 1 "Fail" 0 "No fail";
VAL_ 501 CDCS11_AVM_Initialization 1 "Request Initialize" 0 "No Request";
VAL_ 501 CDCS11_AVM_bodySync 3 "reserved" 2 "OFF" 1 "ON" 0 "No action";
VAL_ 501 CDCS11_AVM_licenseplateabbr 34 "台" 33 "澳" 32 "港" 31 "新" 30 "宁" 29 "蒙" 28 "桂" 27 "藏" 26 "青" 25 "甘" 24 "陕" 23 "云" 22 "贵" 21 "川" 20 "琼" 19 "粤" 18 "湘" 17 "鄂" 16 "豫" 15 "鲁" 14 "赣" 13 "闽" 12 "皖" 11 "浙" 10 "苏" 9 "黑" 8 "吉" 7 "辽" 6 "晋" 5 "冀" 4 "渝" 3 "沪" 2 "津" 1 "京" 0 "无";
VAL_ 501 CDCS11_AVM_SpeView 2 "Rear wide view" 1 "Front wide view" 0 "No Request";
VAL_ 501 CDCS11_AVM_licenseplateArea 26 "Z" 25 "Y" 24 "X" 23 "W" 22 "V" 21 "U" 20 "T" 19 "S" 18 "R" 17 "Q" 16 "P" 15 "O" 14 "N" 13 "M" 12 "L" 11 "K" 10 "J" 9 "I" 8 "H" 7 "G" 6 "F" 5 "E" 4 "D" 3 "C" 2 "B" 1 "A" 0 "Nothing";
VAL_ 501 CDCS11_AVM_StartMode 7 "Reserved" 6 "Reserved" 5 "Reserved" 4 "Reserved" 3 "24h" 2 "12h" 1 "0h" 0 "No Action";
VAL_ 501 CDCS11_AVM_LicensePlateNO1 41 "9" 40 "8" 39 "7" 38 "6" 37 "5" 36 "4" 35 "3" 34 "2" 33 "1" 32 "0" 26 "Z" 25 "Y" 24 "X" 23 "W" 22 "V" 21 "U" 20 "T" 19 "S" 18 "R" 17 "Q" 16 "P" 15 "O" 14 "N" 13 "M" 12 "L" 11 "K" 10 "J" 9 "I" 8 "H" 7 "G" 6 "F" 5 "E" 4 "D" 3 "C" 2 "B" 1 "A" 0 "Nothing";
VAL_ 501 CDCS11_ELK_OnOffSet 3 "reserved" 2 "OFF" 1 "ON" 0 "No action";
VAL_ 501 CDCS11_AVM_LicensePlateNO2 41 "9" 40 "8" 39 "7" 38 "6" 37 "5" 36 "4" 35 "3" 34 "2" 33 "1" 32 "0" 26 "Z" 25 "Y" 24 "X" 23 "W" 22 "V" 21 "U" 20 "T" 19 "S" 18 "R" 17 "Q" 16 "P" 15 "O" 14 "N" 13 "M" 12 "L" 11 "K" 10 "J" 9 "I" 8 "H" 7 "G" 6 "F" 5 "E" 4 "D" 3 "C" 2 "B" 1 "A" 0 "Nothing";
VAL_ 501 CDCS11_DrvOffAlertSwitch 3 "reserved" 2 "OFF" 1 "ON" 0 "No action";
VAL_ 501 CDCS11_AVM_LicensePlateNO3 41 "9" 40 "8" 39 "7" 38 "6" 37 "5" 36 "4" 35 "3" 34 "2" 33 "1" 32 "0" 26 "Z" 25 "Y" 24 "X" 23 "W" 22 "V" 21 "U" 20 "T" 19 "S" 18 "R" 17 "Q" 16 "P" 15 "O" 14 "N" 13 "M" 12 "L" 11 "K" 10 "J" 9 "I" 8 "H" 7 "G" 6 "F" 5 "E" 4 "D" 3 "C" 2 "B" 1 "A" 0 "Nothing";
VAL_ 501 CDCS11_DCWposition 3 "level3" 2 "level2" 1 "level1" 0 "off";
VAL_ 501 CDCS11_AVM_LicensePlateNO4 41 "9" 40 "8" 39 "7" 38 "6" 37 "5" 36 "4" 35 "3" 34 "2" 33 "1" 32 "0" 26 "Z" 25 "Y" 24 "X" 23 "W" 22 "V" 21 "U" 20 "T" 19 "S" 18 "R" 17 "Q" 16 "P" 15 "O" 14 "N" 13 "M" 12 "L" 11 "K" 10 "J" 9 "I" 8 "H" 7 "G" 6 "F" 5 "E" 4 "D" 3 "C" 2 "B" 1 "A" 0 "Nothing";
VAL_ 501 CDCS11_AVM_LicensePlateNO5 41 "9" 40 "8" 39 "7" 38 "6" 37 "5" 36 "4" 35 "3" 34 "2" 33 "1" 32 "0" 26 "Z" 25 "Y" 24 "X" 23 "W" 22 "V" 21 "U" 20 "T" 19 "S" 18 "R" 17 "Q" 16 "P" 15 "O" 14 "N" 13 "M" 12 "L" 11 "K" 10 "J" 9 "I" 8 "H" 7 "G" 6 "F" 5 "E" 4 "D" 3 "C" 2 "B" 1 "A" 0 "Nothing";
VAL_ 501 CDCS11_AVM_LicensePlateNO6 41 "9" 40 "8" 39 "7" 38 "6" 37 "5" 36 "4" 35 "3" 34 "2" 33 "1" 32 "0" 26 "Z" 25 "Y" 24 "X" 23 "W" 22 "V" 21 "U" 20 "T" 19 "S" 18 "R" 17 "Q" 16 "P" 15 "O" 14 "N" 13 "M" 12 "L" 11 "K" 10 "J" 9 "I" 8 "H" 7 "G" 6 "F" 5 "E" 4 "D" 3 "C" 2 "B" 1 "A" 0 "Nothing";
VAL_ 501 CDCS11_DataUp_Trigger 3 "Reserved" 2 "Reserved" 1 "trigger" 0 "no action";
VAL_ 501 CDCS11_AVM_LicensePlateNO7 41 "9" 40 "8" 39 "7" 38 "6" 37 "5" 36 "4" 35 "3" 34 "2" 33 "1" 32 "0" 26 "Z" 25 "Y" 24 "X" 23 "W" 22 "V" 21 "U" 20 "T" 19 "S" 18 "R" 17 "Q" 16 "P" 15 "O" 14 "N" 13 "M" 12 "L" 11 "K" 10 "J" 9 "I" 8 "H" 7 "G" 6 "F" 5 "E" 4 "D" 3 "C" 2 "B" 1 "A" 0 "Nothing";
VAL_ 501 CDCS11_AVM_LicensePlateNO8 41 "9" 40 "8" 39 "7" 38 "6" 37 "5" 36 "4" 35 "3" 34 "2" 33 "1" 32 "0" 26 "Z" 25 "Y" 24 "X" 23 "W" 22 "V" 21 "U" 20 "T" 19 "S" 18 "R" 17 "Q" 16 "P" 15 "O" 14 "N" 13 "M" 12 "L" 11 "K" 10 "J" 9 "I" 8 "H" 7 "G" 6 "F" 5 "E" 4 "D" 3 "C" 2 "B" 1 "A" 0 "Nothing";
VAL_ 501 CDCS11_AVM_Powertype 3 "PHEV" 2 "Traditional" 1 "EV" 0 "No Action";
VAL_ 501 CDCS11_AVM_Diaphaneity 11 "100%" 10 "90%" 9 "80%" 8 "70%" 7 "60%" 6 "50%" 5 "40%" 4 "30%" 3 "20%" 2 "10%" 1 "0" 0 "No Action";
VAL_ 501 CDCS11_AVM_DiaphaneitySw 1 "Request" 0 "No Request";
VAL_ 501 CDCS11_LDWLKAAidSwSts 7 "Reserved" 6 "Reserved" 5 "Reserved" 4 "LKA" 3 "LDW+LKA" 2 "LDW" 1 "OFF" 0 "No Request";
VAL_ 501 CDCS11_MOD_Sound_Sw 3 "Reserved" 2 "Off（关闭）" 1 "On（开启）" 0 "No Action";
VAL_ 501 CDCS11_MOD_BSD_Sw 3 "Reserved" 2 "Off（关闭）" 1 "On（开启）" 0 "No Action";
VAL_ 501 CDCS11_PA_FRS_OnOffSet 3 "Reserved" 2 "Off（关闭）" 1 "On（开启）" 0 "No Action";
VAL_ 501 CDCS11_PA_3D_OnOffSet 3 "Reserved" 2 "Off（关闭）" 1 "On（开启）" 0 "No Action";
VAL_ 501 CDCS11_PA_measure_OnOffSet 3 "Reserved" 2 "Off（关闭）" 1 "On（开启）" 0 "No Action";
VAL_ 501 CDCS11_MODSw 3 "Reserved" 2 "Off（关闭）" 1 "On（开启）" 0 "No Action";
VAL_ 501 CDCS11_VoiceNotifFrequency_mode 3 "Detailed" 2 "Simple" 1 "Basic" 0 "Not defined";
VAL_ 501 CDCS11_ACCOnOffSet 3 "Reserved" 2 "Off（关闭）" 1 "On（开启）" 0 "No Action";
VAL_ 501 CDCS11_HPASw 3 "Reserved" 2 "Off（关闭）" 1 "On（开启）" 0 "No Action";
VAL_ 501 CDCS11_DeleteMapID 0 "No Action";
VAL_ 501 CDCS11_UploadMapID 0 "No Action";
VAL_ 501 CDCS11_HPAActiveConfirm 1 "Confirm" 0 "No Confirm";
VAL_ 501 CDCS11_HPApreparkingSw 2 "off" 1 "on" 0 "No Action";
VAL_ 501 CDCS11_HPAPathwaytoCloud_WorkSts 7 "Reserve" 6 "Reserve" 5 "Reserve" 4 "Uploading error" 3 "Uploading" 2 "Uploaded" 1 "To be uploaded" 0 "No Action";
VAL_ 501 CDCS11_PA_Select_ID 0 "default";
VAL_ 501 CDCS11_learnpath_St 2 "complete and upload" 1 "complete" 0 "default";
VAL_ 501 CDCS11_LKAActvReq 7 "Reserved" 6 "Reserved" 5 "Reserved" 4 "LDP+LDW" 3 "LDP  ON" 2 "LDW ON" 1 "OFF" 0 "No Action";
VAL_ 501 CDCS11_TSR_LimitOverspeedSet 255 "No Action";
VAL_ 501 CDCS11_ParkingoutSlot_Type 3 "Oblique" 2 "Parallel" 1 "Vertical" 0 "Undecided";
VAL_ 501 CDCS11_ParkingoutSlot_Dire 3 "Front" 2 "Right" 1 "Left" 0 "No request";
VAL_ 501 CDCS11_OptionalSlot_Type 3 "Oblique" 2 "Parallel" 1 "Vertical" 0 "Undecided";
VAL_ 501 CDCS11_OptionalSlot_Dire 4 "Rear" 3 "Front" 2 "Right" 1 "Left" 0 "No request";
VAL_ 501 CDCS11_OptionalSlotCoor_P0_X 0 "No Action";
VAL_ 501 CDCS11_OptionalSlotCoor_P0_Y 0 "No Action";
VAL_ 501 CDCS11_OptionalSlotCoor_P1_X 0 "No Action";
VAL_ 501 CDCS11_OptionalSlotCoor_P1_Y 0 "No Action";
VAL_ 501 CDCS11_OptionalSlotCoor_P2_X 0 "No Action";
VAL_ 501 CDCS11_OptionalSlotCoor_P2_Y 0 "No Action";
VAL_ 501 CDCS11_OptionalSlotCoor_P3_X 0 "No Action";
VAL_ 501 CDCS11_OptionalSlotCoor_P3_Y 0 "No Action";
VAL_ 515 CDCS15_NNP_DriverStatus 3 "reserved" 2 "Driver Distracted" 1 "Driver Fatigue" 0 "None";
VAL_ 515 CDCS15_Storage_St 1 "not available" 0 "available";
VAL_ 515 CDCS15_USB_St 1 "not available" 0 "available";
VAL_ 515 CDCS15_UserSceneMode 15 "Reserved" 14 "Reserved" 13 "Reserved" 12 "Reserved" 11 "Reserved" 10 "OtherMode5" 9 "OtherMode4" 8 "OtherMode3" 7 "OtherMode2" 6 "OtherMode1" 5 "CampingMode" 4 "PetMode" 3 "Childmode" 2 "CarWashMode" 1 "RacingMode" 0 "No Scene";
VAL_ 515 CDCS15_NNP_DriverFatigueStatus 3 "Fatigue" 2 "Not Fatigue" 1 "No Face" 0 "Disable";
VAL_ 515 CDCS15_NNP_DriverDistractedStatus 3 "Distracted" 2 "Not Distracted" 1 "No Face" 0 "Disable";
VAL_ 305 ICU1_VehicleSpdDisplayValid 1 "Valid" 0 "Invalid";
VAL_ 992 CalendarMonth 12 "December" 11 "November" 10 "October" 9 "September" 8 "August" 7 "July" 6 "June" 5 "May" 4 "April" 3 "March" 2 "February" 1 "January" 0 "Unknown";
VAL_ 992 TimeDspFmt 1 "12 hour mode(not used)" 0 "24 hour mode(default)";
